VERSION "FL_EP_CANFD"

NS_ :

BS_:

BU_: BMS CDU DCB EAC EVCC FLZCU LBMS RXCU

BO_ 1170 TMS_TDU_3: 64 FLZCU
 SG_ HVHRu : 23|8@0+ (5,0) [0|1270] "V" RXCU
 SG_ HVHRi : 31|8@0+ (0.25,0) [0|63.5] "A" RXCU
 SG_ HVHR_Sts : 34|3@0+ (1,0) [0|7] "" RXCU

BO_ 1172 TMS_1: 8 FLZCU
 SG_ ExternalTemperature_C : 39|8@0+ (0.5,-40) [-40|85] "°C" RXCU
 SG_ CirculationModeDisplaySts : 45|1@0+ (1,0) [0|1] "" RXCU

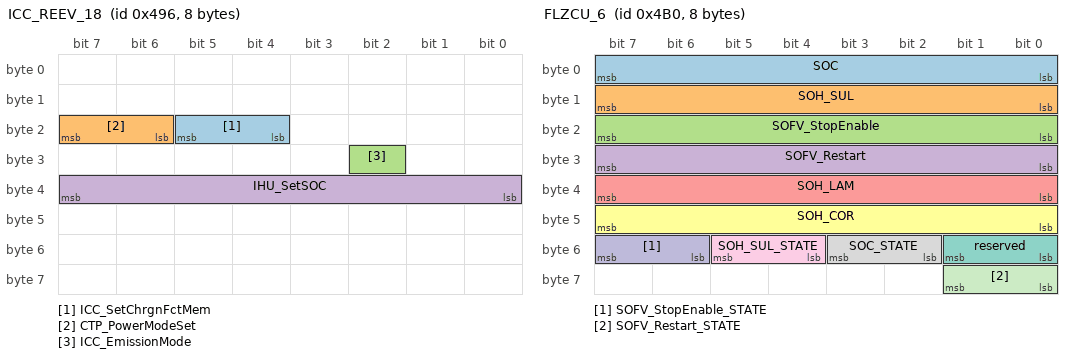
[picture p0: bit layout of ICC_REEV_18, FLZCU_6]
BO_ 1174 ICC_REEV_18: 8 FLZCU
 SG_ ICC_SetChrgnFctMem : 21|2@0+ (1,0) [0|3] "" RXCU
 SG_ CTP_PowerModeSet : 23|2@0+ (1,0) [0|3] "" RXCU
 SG_ ICC_EmissionMode : 26|1@0+ (1,0) [0|1] "" RXCU
 SG_ IHU_SetSOC : 39|8@0+ (1,0) [0|100] "%" RXCU

BO_ 1181 FLZCU_9: 8 FLZCU
 SG_ FLZCU_AlcoholLockInputSts : 47|1@0+ (1,0) [0|1] "" RXCU

BO_ 1182 CDU_OBC_3: 48 CDU
 SG_ CDU_OBC_3_CRC1 : 7|8@0+ (1,0) [0|255] "" RXCU
 SG_ CDU_OBC_3_RollgCntr1 : 11|4@0+ (1,0) [0|14] "" RXCU
 SG_ CDU_OBC_3_Resd1 : 15|4@0+ (1,0) [0|15] "" RXCU
 SG_ OBC_ChgCurr : 23|16@0+ (0.05,0) [0|400] "A" RXCU
 SG_ OBC_ChgVolt : 39|16@0+ (0.05,0) [0|1000] "V" RXCU
 SG_ OBC_MaxOutputPower : 55|8@0+ (0.1,0) [0|25.5] "kW" RXCU
 SG_ OBC_FaultCode : 63|8@0+ (1,0) [0|255] "" RXCU
 SG_ CDU_OBC_3_CRC2 : 71|8@0+ (1,0) [0|255] "" RXCU
 SG_ CDU_OBC_3_RollgCntr2 : 75|4@0+ (1,0) [0|14] "" RXCU
 SG_ CDU_OBC_3_Resd2 : 79|4@0+ (1,0) [0|15] "" RXCU
 SG_ OBC_MaxDisOutPower : 111|8@0+ (0.1,0) [0|25.5] "kW" RXCU
 SG_ OBC_CPMaxVolt : 119|8@0+ (0.1,0) [0|20] "V" RXCU
 SG_ CDU_OBC_3_CRC3 : 135|8@0+ (1,0) [0|255] "" RXCU
 SG_ CDU_OBC_3_RollgCntr3 : 139|4@0+ (1,0) [0|14] "" RXCU
 SG_ CDU_OBC_3_Resd3 : 143|4@0+ (1,0) [0|15] "" RXCU
 SG_ OBC_ChrgrInputCurr1 : 151|10@0+ (0.1,0) [0|100] "A" RXCU
 SG_ OBC_ChrgrInputCurr2 : 157|10@0+ (0.1,0) [0|100] "A" RXCU
 SG_ OBC_ChrgrInputCurr3 : 163|10@0+ (0.1,0) [0|100] "A" RXCU
 SG_ OBC_S2Swtsts : 169|2@0+ (1,0) [0|3] "" RXCU
 SG_ OBC_ChrgrInputVolt1 : 183|13@0+ (0.1,0) [0|800] "V" RXCU
 SG_ CDU_OBC_3_CRC4 : 199|8@0+ (1,0) [0|255] "" RXCU
 SG_ CDU_OBC_3_RollgCntr4 : 203|4@0+ (1,0) [0|14] "" RXCU
 SG_ CDU_OBC_3_Resd4 : 207|4@0+ (1,0) [0|15] "" RXCU
 SG_ OBC_ChrgrInputVolt2 : 215|13@0+ (0.1,0) [0|800] "V" RXCU
 SG_ OBC_ChrgrInputVolt3 : 231|13@0+ (0.1,0) [0|800] "V" RXCU
 SG_ OBC_FaultLevelSts : 234|3@0+ (1,0) [0|7] "" RXCU
 SG_ OBC_ElectronicLockSts : 242|3@0+ (1,0) [0|7] "" RXCU
 SG_ OBC_WorkingMode : 251|4@0+ (1,0) [0|15] "" RXCU
 SG_ OBC_Worksts : 253|2@0+ (1,0) [0|3] "" RXCU
 SG_ OBC_CPLineSts : 255|2@0+ (1,0) [0|3] "" RXCU
 SG_ CDU_OBC_3_CRC5 : 263|8@0+ (1,0) [0|255] "" RXCU
 SG_ CDU_OBC_3_RollgCntr5 : 267|4@0+ (1,0) [0|14] "" RXCU
 SG_ CDU_OBC_3_Resd5 : 271|4@0+ (1,0) [0|15] "" RXCU
 SG_ OBC_CCResisdent : 279|13@0+ (1,0) [0|3400] "R" RXCU
 SG_ OBC_HV_OutputUnderVolt : 280|1@0+ (1,0) [0|1] "" RXCU
 SG_ OBC_HV_OutputOverVolt : 288|1@0+ (1,0) [0|1] "" RXCU
 SG_ OBC_HV_OutputShortCircuit : 289|1@0+ (1,0) [0|1] "" RXCU
 SG_ OBC_InputUnderVolt : 290|1@0+ (1,0) [0|1] "" RXCU
 SG_ OBC_InputOverVolt : 291|1@0+ (1,0) [0|1] "" RXCU
 SG_ OBC_HighCurrOutputFault : 292|1@0+ (1,0) [0|1] "" RXCU
 SG_ OBC_CAN_Fault : 293|1@0+ (1,0) [0|1] "" RXCU
 SG_ OBC_KL30_UnderVolt : 302|1@0+ (1,0) [0|1] "" RXCU
 SG_ OBC_MaxInnerAc220VOutPower : 311|8@0+ (0.1,0) [0|25.4] "kW" RXCU
 SG_ OBC_ActInnerAc220VOutPower : 319|8@0+ (0.1,0) [0|25.4] "kW" RXCU
 SG_ CDU_OBC_3_CRC6 : 327|8@0+ (1,0) [0|255] "" RXCU
 SG_ CDU_OBC_3_RollgCntr6 : 331|4@0+ (1,0) [0|14] "" RXCU
 SG_ CDU_OBC_3_Resd6 : 335|4@0+ (1,0) [0|15] "" RXCU
 SG_ OBC_InnerDischgCurr : 343|10@0+ (0.1,0) [0|100] "A" RXCU
 SG_ OBC_InnerDischgVolt : 348|13@0+ (0.1,0) [0|800] "V" RXCU
 SG_ OBC_OutDischgCurr : 367|10@0+ (0.1,0) [0|100] "A" RXCU
 SG_ OBC_OutDischgVolt : 372|13@0+ (0.1,0) [0|800] "V" RXCU

BO_ 1184 TMS_TDU_1: 64 FLZCU
 SG_ TDU_1_EAC_Sts : 244|3@0+ (1,0) [0|7] "" RXCU
 SG_ EAC_u : 295|8@0+ (5,0) [0|1270] "V" RXCU
 SG_ EAC_i : 303|8@0+ (0.5,0) [0|127] "A" RXCU
 SG_ HVHu : 319|8@0+ (5,0) [0|1270] "V" RXCU
 SG_ HVHi : 343|8@0+ (0.25,0) [0|63.5] "A" RXCU
 SG_ HVH_Sts : 346|3@0+ (1,0) [0|7] "" RXCU

BO_ 1195 BNCM_8: 8 FLZCU
 SG_ BNCM_8_HV_Req : 35|2@0+ (1,0) [0|3] "" RXCU

BO_ 1199 TCM_1: 8 FLZCU
 SG_ TCM_1_TrailerSts : 16|1@0+ (1,0) [0|1] "" RXCU

BO_ 1200 FLZCU_6: 8 FLZCU
 SG_ SOC : 7|8@0+ (1,0) [0|100] "%" RXCU
 SG_ SOH_SUL : 15|8@0+ (1,0) [0|100] "%" RXCU
 SG_ SOFV_StopEnable : 23|8@0+ (0.0625,0) [0|15.875] "V" RXCU
 SG_ SOFV_Restart : 31|8@0+ (0.0625,0) [0|15.875] "V" RXCU
 SG_ SOH_LAM : 39|8@0+ (0.5,0) [0|127] "Ah" RXCU
 SG_ SOH_COR : 47|8@0+ (0.0625,0) [0|15.875] "V" RXCU
 SG_ reserved : 49|2@0+ (1,0) [0|3] "" RXCU
 SG_ SOC_STATE : 51|2@0+ (1,0) [0|3] "" RXCU
 SG_ SOH_SUL_STATE : 53|2@0+ (1,0) [0|3] "" RXCU
 SG_ SOFV_StopEnable_STATE : 55|2@0+ (1,0) [0|3] "" RXCU
 SG_ SOFV_Restart_STATE : 57|2@0+ (1,0) [0|3] "" RXCU

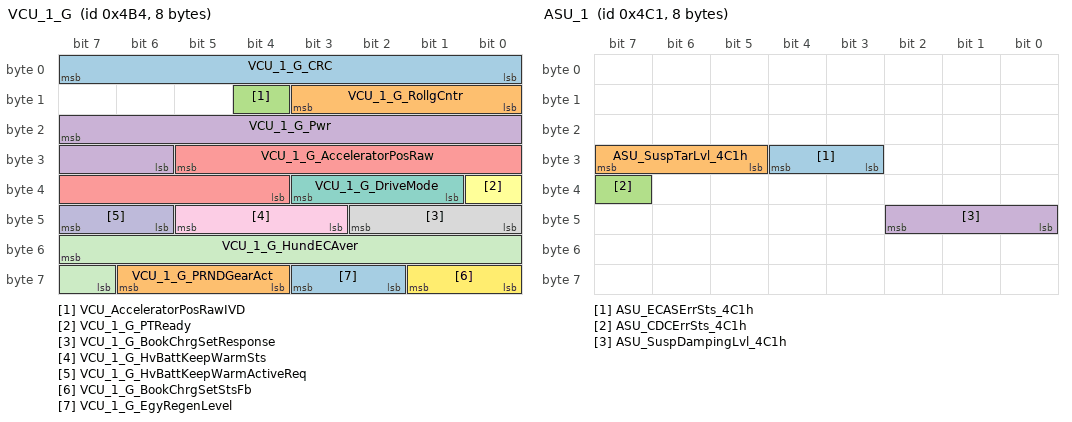
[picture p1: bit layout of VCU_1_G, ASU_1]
BO_ 1204 VCU_1_G: 8 RXCU
 SG_ VCU_1_G_CRC : 7|8@0+ (1,0) [0|255] "" FLZCU
 SG_ VCU_1_G_RollgCntr : 11|4@0+ (1,0) [0|14] "" FLZCU
 SG_ VCU_AcceleratorPosRawIVD : 12|1@0+ (1,0) [0|1] "" FLZCU
 SG_ VCU_1_G_Pwr : 23|10@0+ (1,-500) [-500|500] "" FLZCU
 SG_ VCU_1_G_AcceleratorPosRaw : 29|10@0+ (0.1,0) [0|100] "%" FLZCU
 SG_ VCU_1_G_PTReady : 32|1@0+ (1,0) [0|1] "" FLZCU
 SG_ VCU_1_G_DriveMode : 35|3@0+ (1,0) [0|7] "" FLZCU
 SG_ VCU_1_G_BookChrgSetResponse : 42|3@0+ (1,0) [0|7] "" BMS,CDU,FLZCU
 SG_ VCU_1_G_HvBattKeepWarmSts : 45|3@0+ (1,0) [0|7] "" FLZCU
 SG_ VCU_1_G_HvBattKeepWarmActiveReq : 47|2@0+ (1,0) [0|3] "" BMS,CDU,FLZCU
 SG_ VCU_1_G_HundECAver : 55|9@0+ (0.1,0) [0|51] "kwh" FLZCU
 SG_ VCU_1_G_BookChrgSetStsFb : 57|2@0+ (1,0) [0|3] "" FLZCU
 SG_ VCU_1_G_EgyRegenLevel : 59|2@0+ (1,0) [0|3] "" FLZCU
 SG_ VCU_1_G_PRNDGearAct : 62|3@0+ (1,0) [0|7] "" BMS,CDU,DCB,EVCC,FLZCU

BO_ 1207 TMS_TDU_2: 64 FLZCU
 SG_ EAC_i_400V : 279|9@0+ (0.1,0) [0|50] "A" RXCU
 SG_ HVH_Sts_400V : 282|3@0+ (1,0) [0|7] "" RXCU
 SG_ HVH_U_400V : 295|8@0+ (2,0) [0|508] "V" RXCU
 SG_ Flag_400V_800V : 299|2@0+ (1,0) [0|3] "" RXCU

BO_ 1209 VCU_2_G: 8 RXCU
 SG_ VCU_2_G_CRC : 7|8@0+ (1,0) [0|255] "" FLZCU
 SG_ VCU_2_G_RollgCntr : 11|4@0+ (1,0) [0|14] "" FLZCU
 SG_ VCU_2_G_Resd : 15|4@0+ (1,0) [0|15] "" FLZCU
 SG_ VCU_2_G_GasPedalPosInvalidData : 24|1@0+ (1,0) [0|1] "" FLZCU
 SG_ VCU_2_G_PowerLimit : 25|1@0+ (1,0) [0|1] "" FLZCU
 SG_ VCU_2_G_BrakeLightReq : 26|1@0+ (1,0) [0|1] "" FLZCU
 SG_ VCU_2_G_VehicleSystemFailure : 27|1@0+ (1,0) [0|1] "" FLZCU
 SG_ OnekeyHVOffSuccess_4B9h : 28|1@0+ (1,0) [0|1] "" FLZCU
 SG_ VCU_2_G_BootloadSts : 29|1@0+ (1,0) [0|1] "" FLZCU
 SG_ VCU_2_G_DischgSts : 30|1@0+ (1,0) [0|1] "" FLZCU
 SG_ VCU_2_G_BrakePedalStsValidData : 31|1@0+ (1,0) [0|1] "" FLZCU
 SG_ VCU_2_G_ExhibitionMod : 32|1@0+ (1,0) [0|1] "" FLZCU
 SG_ VCU_2_G_BrakePedalSts : 36|1@0+ (1,0) [0|1] "" FLZCU
 SG_ VCU_2_G_DCDCEnable : 37|1@0+ (1,0) [0|1] "" FLZCU
 SG_ VCU_2_G_HVReady : 38|1@0+ (1,0) [0|1] "" CDU,FLZCU,LBMS
 SG_ Res_VCU_2_G_Brake_state : 39|1@0+ (1,0) [0|1] "" FLZCU
 SG_ VCU_2_G_VCUEnergyflow : 43|4@0+ (1,0) [0|15] "" FLZCU
 SG_ VCU_2_G_GasPedalPosition : 49|10@0+ (0.1,0) [0|100] "%" FLZCU
 SG_ VCU_2_G_DrvGearShiftFailureIndcn : 53|4@0+ (1,0) [0|15] "" FLZCU
 SG_ VCU_2_G_OnekeyHVoffStyle : 55|2@0+ (1,0) [0|3] "" FLZCU

BO_ 1217 ASU_1: 8 FLZCU
 SG_ ASU_ECASErrSts_4C1h : 28|2@0+ (1,0) [0|3] "" RXCU
 SG_ ASU_SuspTarLvl_4C1h : 31|3@0+ (1,0) [0|7] "" RXCU
 SG_ ASU_CDCErrSts_4C1h : 39|1@0+ (1,0) [0|1] "" RXCU
 SG_ ASU_SuspDampingLvl_4C1h : 42|3@0+ (1,0) [0|7] "" RXCU

BO_ 1219 VCU_TMS_9: 16 RXCU
 SG_ VCU_CLMSystemPowerLimit : 23|10@0+ (0.04,0) [0|40] "KW" FLZCU
 SG_ HCU_HVHRAllow : 33|2@0+ (1,0) [0|3] "" FLZCU
 SG_ VCU_CLMEACAllow : 34|1@0+ (1,0) [0|1] "" FLZCU
 SG_ VCU_CLMHVHAllow : 35|1@0+ (1,0) [0|1] "" FLZCU
 SG_ VCU_CLMHVReady : 36|1@0+ (1,0) [0|1] "" FLZCU
 SG_ VCU_PwtCoolingLvl : 39|3@0+ (1,0) [0|7] "" FLZCU

BO_ 1224 BMS_12: 16 BMS
 SG_ BMS_Chg_Sts : 87|4@0+ (1,0) [0|15] "" RXCU

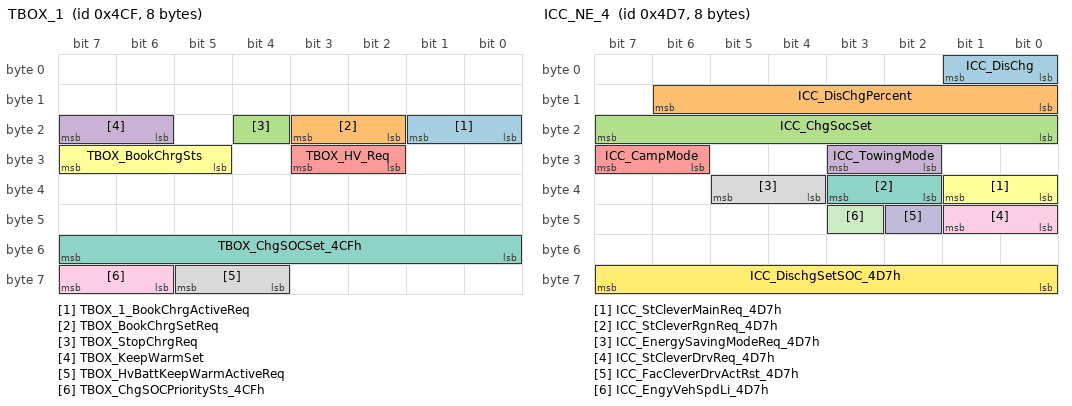
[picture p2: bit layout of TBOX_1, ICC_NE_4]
BO_ 1231 TBOX_1: 8 FLZCU
 SG_ TBOX_1_BookChrgActiveReq : 17|2@0+ (1,0) [0|3] "" RXCU
 SG_ TBOX_BookChrgSetReq : 19|2@0+ (1,0) [0|3] "" RXCU
 SG_ TBOX_StopChrgReq : 20|1@0+ (1,0) [0|1] "" RXCU
 SG_ TBOX_KeepWarmSet : 23|2@0+ (1,0) [0|3] "" RXCU
 SG_ TBOX_HV_Req : 27|2@0+ (1,0) [0|3] "" RXCU
 SG_ TBOX_BookChrgSts : 31|3@0+ (1,0) [0|7] "" RXCU
 SG_ TBOX_ChgSOCSet_4CFh : 55|8@0+ (1,0) [1|100] "%" RXCU
 SG_ TBOX_HvBattKeepWarmActiveReq : 61|2@0+ (1,0) [0|3] "" RXCU
 SG_ TBOX_ChgSOCPrioritySts_4CFh : 63|2@0+ (1,0) [0|3] "" RXCU

BO_ 1239 ICC_NE_4: 8 FLZCU
 SG_ ICC_DisChg : 1|2@0+ (1,0) [0|3] "" RXCU
 SG_ ICC_DisChgPercent : 14|7@0+ (1,0) [1|100] "%" RXCU
 SG_ ICC_ChgSocSet : 23|8@0+ (1,0) [1|100] "%" RXCU
 SG_ ICC_TowingMode : 27|2@0+ (1,0) [0|3] "" RXCU
 SG_ ICC_CampMode : 31|2@0+ (1,0) [0|3] "" RXCU
 SG_ ICC_StCleverMainReq_4D7h : 33|2@0+ (1,0) [0|3] "" RXCU
 SG_ ICC_StCleverRgnReq_4D7h : 35|2@0+ (1,0) [0|3] "" RXCU
 SG_ ICC_EnergySavingModeReq_4D7h : 37|2@0+ (1,0) [0|3] "" RXCU
 SG_ ICC_StCleverDrvReq_4D7h : 41|2@0+ (1,0) [0|3] "" RXCU
 SG_ ICC_FacCleverDrvActRst_4D7h : 42|1@0+ (1,0) [0|1] "" RXCU
 SG_ ICC_EngyVehSpdLi_4D7h : 43|1@0+ (1,0) [0|1] "" RXCU
 SG_ ICC_DischgSetSOC_4D7h : 63|8@0+ (1,0) [0|100] "" RXCU

BO_ 1246 ICC_TMS_5: 32 FLZCU
 SG_ ICC_KeepWarm : 35|2@0+ (1,0) [0|3] "" RXCU

BO_ 1248 FRZCU_TO_FLZCU: 48 FLZCU
 SG_ FRZCU_RKEButtAct : 239|3@0+ (1,0) [0|7] "" RXCU

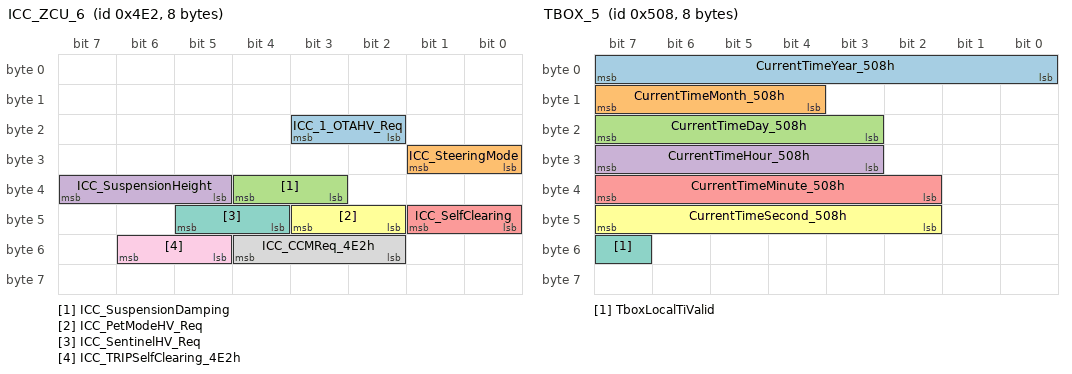
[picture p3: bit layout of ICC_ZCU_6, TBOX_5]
BO_ 1250 ICC_ZCU_6: 8 FLZCU
 SG_ ICC_1_OTAHV_Req : 19|2@0+ (1,0) [0|3] "" RXCU
 SG_ ICC_SteeringMode : 25|2@0+ (1,0) [0|3] "" RXCU
 SG_ ICC_SuspensionDamping : 36|2@0+ (1,0) [0|3] "" RXCU
 SG_ ICC_SuspensionHeight : 39|3@0+ (1,0) [0|7] "" RXCU
 SG_ ICC_SelfClearing : 41|2@0+ (1,0) [0|3] "" RXCU
 SG_ ICC_PetModeHV_Req : 43|2@0+ (1,0) [0|3] "" RXCU
 SG_ ICC_SentinelHV_Req : 45|2@0+ (1,0) [0|3] "" RXCU
 SG_ ICC_CCMReq_4E2h : 52|3@0+ (1,0) [0|7] "" RXCU
 SG_ ICC_TRIPSelfClearing_4E2h : 54|2@0+ (1,0) [0|3] "" RXCU

BO_ 1252 ICC_COM_1: 8 FLZCU
 SG_ TotalOdometer_km_OBD : 23|24@0+ (0.1,0) [0|999999.9] "km" RXCU
 SG_ TotalOdometer_km_OBDValidData : 60|1@0+ (1,0) [0|1] "" RXCU

BO_ 1265 ICC_ZCU_25: 24 FLZCU
 SG_ ICC_CinemaStatus : 185|2@0+ (1,0) [0|3] "" RXCU

BO_ 1268 BMS_4F4h: 64 BMS
 SG_ CRC1_4F4h : 7|8@0+ (1,0) [0|255] "" RXCU
 SG_ RollgCntr1_4F4h : 11|4@0+ (1,0) [0|14] "" RXCU
 SG_ Resd1_4F4h : 15|4@0+ (1,0) [0|15] "" RXCU
 SG_ SOCE_4F4h : 23|10@0+ (0.1,0) [0|100] "%" RXCU
 SG_ CRC2_4F4h : 71|8@0+ (1,0) [0|255] "" RXCU
 SG_ RollgCntr2_4F4h : 75|4@0+ (1,0) [0|14] "" RXCU
 SG_ Resd2_4F4h : 79|4@0+ (1,0) [0|15] "" RXCU
 SG_ HvBattEgyTotal_4F4h : 87|20@0+ (1,0) [0|1000000] "kWh" RXCU
 SG_ HvBattV2XTotal_4F4h : 99|20@0+ (1,0) [0|1000000] "kWh" RXCU
 SG_ CRC3_4F4h : 135|8@0+ (1,0) [0|255] "" RXCU
 SG_ RollgCntr3_4F4h : 139|4@0+ (1,0) [0|14] "" RXCU
 SG_ Resd3_4F4h : 143|4@0+ (1,0) [0|15] "" RXCU
 SG_ HvBattNoDrivEgyTotal_4F4h : 151|20@0+ (1,0) [0|1000000] "kWh" RXCU

BO_ 1288 TBOX_5: 8 FLZCU
 SG_ CurrentTimeYear_508h : 7|8@0+ (1,2000) [2000|2255] "" RXCU
 SG_ CurrentTimeMonth_508h : 15|4@0+ (1,0) [1|12] "" RXCU
 SG_ CurrentTimeDay_508h : 23|5@0+ (1,0) [1|31] "" RXCU
 SG_ CurrentTimeHour_508h : 31|5@0+ (1,0) [0|23] "" RXCU
 SG_ CurrentTimeMinute_508h : 39|6@0+ (1,0) [0|59] "" RXCU
 SG_ CurrentTimeSecond_508h : 47|6@0+ (1,0) [0|59] "" RXCU
 SG_ TboxLocalTiValid : 55|1@0+ (1,0) [0|1] "" RXCU

BO_ 1290 BMS_8: 8 BMS
 SG_ BMS_HvBattCellUnderU : 21|3@0+ (1,0) [0|7] "" RXCU
 SG_ BMS_HvBattUnderU : 23|2@0+ (1,0) [0|3] "" RXCU

BO_ 1291 BMS_2_G: 8 BMS
 SG_ BMS_SOCLight : 62|7@0+ (1,0) [0|100] "%" RXCU

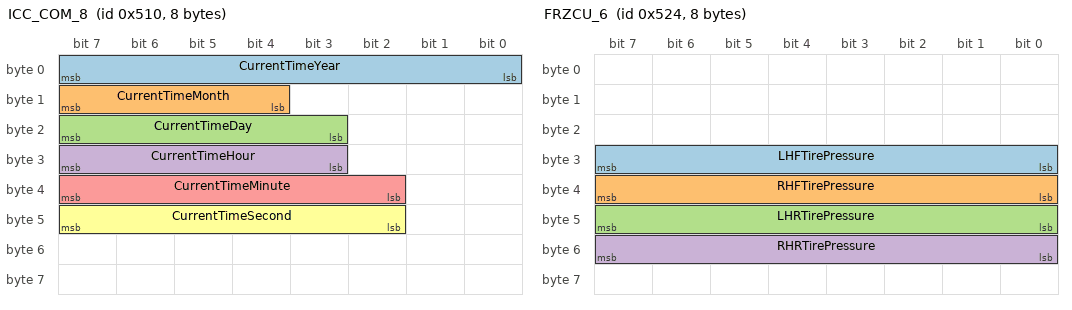
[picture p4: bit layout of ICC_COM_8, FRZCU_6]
BO_ 1296 ICC_COM_8: 8 FLZCU
 SG_ CurrentTimeYear : 7|8@0+ (1,2000) [2000|2255] "" RXCU
 SG_ CurrentTimeMonth : 15|4@0+ (1,0) [1|12] "" RXCU
 SG_ CurrentTimeDay : 23|5@0+ (1,0) [1|31] "" RXCU
 SG_ CurrentTimeHour : 31|5@0+ (1,0) [0|23] "" RXCU
 SG_ CurrentTimeMinute : 39|6@0+ (1,0) [0|59] "" RXCU
 SG_ CurrentTimeSecond : 47|6@0+ (1,0) [0|59] "" RXCU

BO_ 1298 APTC_2: 8 FLZCU
 SG_ APTC_ErrorLevel : 21|3@0+ (1,0) [0|7] "" RXCU
 SG_ APTC_ErrorCode2 : 31|8@0+ (1,0) [0|255] "" RXCU

BO_ 1314 HCU_25: 64 RXCU
 SG_ HCU_CRC1_522h : 7|8@0+ (1,0) [0|255] "" FLZCU
 SG_ HCU_RollgCntr1_522h : 11|4@0+ (1,0) [0|14] "" FLZCU
 SG_ HCU_Resd1_522h : 15|4@0+ (1,0) [0|15] "" FLZCU
 SG_ HCU_V2lDisChgBck : 17|2@0+ (1,0) [0|3] "" FLZCU
 SG_ HCU_DisChgMemFed : 19|2@0+ (1,0) [0|3] "" FLZCU
 SG_ HCU_V2VDisChgBck : 21|2@0+ (1,0) [0|3] "" CDU,FLZCU
 SG_ HCU_V2l_IntlDisChgBck : 23|2@0+ (1,0) [0|3] "" FLZCU
 SG_ HCU_FuelDetnOpDefeated : 25|2@0+ (1,0) [0|3] "" FLZCU
 SG_ HCU_FuelDetnModSwtFed : 27|2@0+ (1,0) [0|3] "" FLZCU
 SG_ HCU_FuelDetnStateFed : 29|2@0+ (1,0) [0|3] "" FLZCU
 SG_ HCU_HVDownRepairModeFed : 31|2@0+ (1,0) [0|3] "" FLZCU
 SG_ HCU_SumFuCns : 37|9@0+ (0.1,0) [0|50] "L/km" FLZCU
 SG_ HCU_TrailerMode : 39|2@0+ (1,0) [0|3] "" FLZCU
 SG_ HCU_TABSwtFed_522h : 40|2@0+ (1,0) [0|3] "" FLZCU
 SG_ HCU_MotSelfHeatLvlReq : 43|3@0+ (1,0) [0|7] "" FLZCU
 SG_ HCU_MotSelfHeatEnReq : 44|1@0+ (1,0) [0|1] "" FLZCU
 SG_ HCU_KeyDriveModememory : 49|2@0+ (1,0) [0|3] "" FLZCU
 SG_ HCU_DrivePowerDispSetFed : 51|2@0+ (1,0) [0|3] "" FLZCU
 SG_ HCU_TCMStsReq_522h : 54|1@0+ (1,0) [0|1] "" FLZCU
 SG_ HCU_EXPERTNormFed : 57|2@0+ (1,0) [0|3] "" FLZCU
 SG_ HCU_4LModeFed : 58|1@0+ (1,0) [0|1] "" FLZCU
 SG_ HCU_EXPERTEcoFed : 60|2@0+ (1,0) [0|3] "" FLZCU
 SG_ HCU_SingleRegnRmn : 61|1@0+ (1,0) [0|1] "" FLZCU
 SG_ HCU_DRIFTModeSts : 63|2@0+ (1,0) [0|3] "" FLZCU
 SG_ HCU_CRC2_522h : 71|8@0+ (1,0) [0|255] "" FLZCU
 SG_ HCU_RollgCntr2_522h : 75|4@0+ (1,0) [0|14] "" FLZCU
 SG_ HCU_Resd2_522h : 79|4@0+ (1,0) [0|15] "" FLZCU
 SG_ HCU_EXPERTAWDFed : 81|2@0+ (1,0) [0|3] "" FLZCU
 SG_ HCU_EXPERTRWDFed : 83|2@0+ (1,0) [0|3] "" FLZCU
 SG_ HCU_CrossaxisFed : 85|2@0+ (1,0) [0|3] "" FLZCU
 SG_ HCU_EXPERTSportFed : 87|2@0+ (1,0) [0|3] "" FLZCU
 SG_ HCU_StopChrgnModeFed : 89|2@0+ (1,0) [0|3] "" FLZCU
 SG_ HCU_StopChrgnFed : 91|2@0+ (1,0) [0|3] "" FLZCU
 SG_ HCU_CLIMBFed : 93|2@0+ (1,0) [0|3] "" FLZCU
 SG_ HCU_EXPERTAutoFed : 95|2@0+ (1,0) [0|3] "" FLZCU
 SG_ HCU_HEV_FunctionLimit : 96|1@0+ (1,0) [0|1] "" FLZCU
 SG_ HCU_ParkingChargeReminder : 97|1@0+ (1,0) [0|1] "" FLZCU
 SG_ HCU_PowerCut : 98|1@0+ (1,0) [0|1] "" FLZCU
 SG_ HCU_IMMOReleaseSignal : 99|1@0+ (1,0) [0|1] "" FLZCU
 SG_ HCU_LVPowSupSYSAbn_lit : 100|1@0+ (1,0) [0|1] "" FLZCU
 SG_ HCU_ChrgnFctMemSt : 102|2@0+ (1,0) [0|3] "" FLZCU
 SG_ HCU_PowerModeChangeInhibit : 104|1@0+ (1,0) [0|1] "" FLZCU
 SG_ HCU_DisconnectChagWarn : 105|1@0+ (1,0) [0|1] "" FLZCU
 SG_ HCU_EngineRunClmReq : 106|1@0+ (1,0) [0|1] "" FLZCU
 SG_ HCU_VehicleSpeedMax_Limit : 107|1@0+ (1,0) [0|1] "" FLZCU
 SG_ HCU_AccleAbility_Limit : 108|1@0+ (1,0) [0|1] "" FLZCU
 SG_ HCU_DriveInhibit_GearP : 109|1@0+ (1,0) [0|1] "" FLZCU
 SG_ HCU_SetModeNotChange : 110|1@0+ (1,0) [0|1] "" FLZCU
 SG_ HCU_UTURNSnowFed : 111|1@0+ (1,0) [0|1] "" FLZCU
 SG_ HCU_PowerLevel : 114|3@0+ (1,0) [0|7] "" FLZCU
 SG_ HCU_TowingModeEna : 115|1@0+ (1,0) [0|1] "" FLZCU
 SG_ HCU_LeaveVehicleWarning : 116|1@0+ (1,0) [0|1] "" FLZCU
 SG_ HCU_DedicatedModeInhibit : 117|1@0+ (1,0) [0|1] "" FLZCU
 SG_ HCU_DisChargeStopFault : 119|2@0+ (1,0) [0|3] "" FLZCU
 SG_ HCU_RearEDLSts : 123|4@0+ (1,0) [0|15] "" FLZCU
 SG_ HCU_FrntEDLSts : 127|4@0+ (1,0) [0|15] "" FLZCU
 SG_ HCU_CRC3_522h : 135|8@0+ (1,0) [0|255] "" FLZCU
 SG_ HCU_RollgCntr3_522h : 139|4@0+ (1,0) [0|14] "" FLZCU
 SG_ HCU_Resd3_522h : 143|4@0+ (1,0) [0|15] "" FLZCU
 SG_ HCU_CruiseLimitSpeedValue : 146|13@0+ (0.0625,0) [0|511.875] "km/h" FLZCU
 SG_ HCU_DriveMode_JT : 151|5@0+ (1,0) [0|31] "" BMS,FLZCU
 SG_ HCU_SocManageFed : 162|3@0+ (1,0) [0|7] "" FLZCU
 SG_ HCU_SinglePedalMemFed : 163|1@0+ (1,0) [0|1] "" FLZCU
 SG_ HCU_CCOSwtFed : 165|2@0+ (1,0) [0|3] "" FLZCU
 SG_ HCU_Pwr : 175|12@0+ (1,-2000) [-2000|2000] "KW" FLZCU
 SG_ HCU_DrvGearShiftFailureIndcn : 179|4@0+ (1,0) [0|15] "" FLZCU
 SG_ HCU_UTURNSandFed : 184|1@0+ (1,0) [0|1] "" FLZCU
 SG_ HCU_CruiseControlStatus : 186|2@0+ (1,0) [0|3] "" FLZCU
 SG_ HCU_EXPERTEESPSet : 188|2@0+ (1,0) [0|3] "" FLZCU
 SG_ HCU_EgyRegenLevel : 191|3@0+ (1,0) [0|7] "" FLZCU
 SG_ HCU_CRC4_522h : 199|8@0+ (1,0) [0|255] "" FLZCU
 SG_ HCU_RollgCntr4_522h : 203|4@0+ (1,0) [0|14] "" FLZCU
 SG_ HCU_Resd4_522h : 207|4@0+ (1,0) [0|15] "" FLZCU
 SG_ HCU_EngyFlowToDisp : 211|5@0+ (1,0) [0|31] "" FLZCU
 SG_ HCU_UTURNGrassFed : 212|1@0+ (1,0) [0|1] "" FLZCU
 SG_ HCU_UTURNMudFed : 213|1@0+ (1,0) [0|1] "" FLZCU
 SG_ HCU_LTCDispFed : 215|2@0+ (1,0) [0|3] "" FLZCU
 SG_ HCU_iTAS_Warn : 217|3@0+ (1,0) [0|7] "" FLZCU
 SG_ HCU_iCCO_Warn : 221|4@0+ (1,0) [0|15] "" FLZCU
 SG_ HCU_DriveModeChangeFail : 222|1@0+ (1,0) [0|1] "" FLZCU
 SG_ HCU_25_Crossaxis_Warn : 225|3@0+ (1,0) [0|7] "" FLZCU
 SG_ HCU_25_EDLFed : 227|2@0+ (1,0) [0|3] "" FLZCU
 SG_ HCU_DraggingModeRemind : 230|3@0+ (1,0) [0|7] "" FLZCU
 SG_ HCU_iTASSceneReq : 232|3@0+ (1,0) [0|7] "" FLZCU
 SG_ HCU_25_iTAS_SlopWarn : 234|2@0+ (1,0) [0|3] "" FLZCU
 SG_ HCU_ExterTempLowHint : 236|2@0+ (1,0) [0|3] "" FLZCU
 SG_ HCU_iTAS_Active : 238|2@0+ (1,0) [0|3] "" FLZCU
 SG_ HCU_25_VehSpdOffroadRmn : 240|1@0+ (1,0) [0|1] "" FLZCU
 SG_ HCU_DrivingModReq : 245|5@0+ (1,0) [0|31] "" FLZCU
 SG_ HCU_25_ADS_FctSts : 248|1@0+ (1,0) [0|1] "" FLZCU
 SG_ HCU_25_DRIFTModeSetReq : 251|3@0+ (1,0) [0|7] "" FLZCU
 SG_ HCU_25_CrossaxisReq : 253|2@0+ (1,0) [0|3] "" FLZCU
 SG_ HCU_25_CCOSwtReq : 255|2@0+ (1,0) [0|3] "" FLZCU
 SG_ HCU_CRC5_522h : 263|8@0+ (1,0) [0|255] "" FLZCU
 SG_ HCU_RollgCntr5_522h : 267|4@0+ (1,0) [0|14] "" FLZCU
 SG_ HCU_Resd5_522h : 271|4@0+ (1,0) [0|15] "" FLZCU
 SG_ HCU_25_ErrorCode : 279|16@0+ (1,0) [0|65535] "" FLZCU
 SG_ HCU_25_ErrorCount : 295|8@0+ (1,0) [0|255] "" FLZCU
 SG_ HCU_25_iDRIFT_Warn : 298|3@0+ (1,0) [0|7] "" FLZCU
 SG_ HCU_25_SetVehSpdOffroad : 300|2@0+ (1,0) [0|3] "" FLZCU
 SG_ HCU_25_LaunchMod_Warn : 303|3@0+ (1,0) [0|7] "" FLZCU
 SG_ HCU_25_TAB_Warn : 307|3@0+ (1,0) [0|7] "" FLZCU
 SG_ HCU_25_CCO_TextDisp : 311|4@0+ (1,0) [0|15] "" FLZCU
 SG_ HCU_25_DCM_Warn : 315|4@0+ (1,0) [0|15] "" FLZCU
 SG_ HCU_25_CCMFed : 317|2@0+ (1,0) [0|3] "" FLZCU
 SG_ HCU_25_TABReq : 319|2@0+ (1,0) [0|3] "" FLZCU
 SG_ HCU_SumElecCns : 339|12@0+ (0.1,-100) [-100|100] "kwh/100km" FLZCU
 SG_ HCU_CrossBorderSts : 341|2@0+ (1,0) [0|3] "" FLZCU
 SG_ HCU_DischgSetSOCFed : 367|8@0+ (1,0) [0|100] "%" FLZCU
 SG_ HCU_facCleverDrvAct_522h : 369|5@0+ (0.1,-1) [-1|2.1] "" FLZCU
 SG_ HCU_stCleverDrvAct_522h : 371|2@0+ (1,0) [0|3] "" FLZCU
 SG_ HCU_stCleverRgnAct_522h : 373|2@0+ (1,0) [0|3] "" FLZCU
 SG_ HCU_stCleverMainAct_522h : 375|2@0+ (1,0) [0|3] "" FLZCU
 SG_ EnergySavingModeSts_522h : 378|2@0+ (1,0) [0|3] "" FLZCU
 SG_ HCU_facCleverDrvActRstFed_522h : 380|2@0+ (1,0) [0|3] "" FLZCU
 SG_ HCU_SailramainingT_Indc_522h : 407|16@0+ (1,0) [0|65535] "s" FLZCU
 SG_ HCU_ATCM_Operation_REQ_522h : 416|3@0+ (1,0) [0|7] "" FLZCU
 SG_ HCU_ModeSwFailureIndc_522h : 419|3@0+ (1,0) [0|7] "" FLZCU
 SG_ HCU_Sailmode_522h : 423|4@0+ (1,0) [0|15] "" FLZCU
 SG_ HCU_CarSickRelfModeFb : 425|2@0+ (1,0) [0|3] "" FLZCU
 SG_ HCU_DeepSnowSts_522h : 427|2@0+ (1,0) [0|3] "" FLZCU
 SG_ DriveModeChangeFailReason_522h : 429|2@0+ (1,0) [0|3] "" FLZCU
 SG_ HCU_CLIMBDisReason_522h : 433|4@0+ (1,0) [0|15] "" FLZCU
 SG_ HCU_CarSickRelfModeDisReason : 436|3@0+ (1,0) [0|7] "" FLZCU
 SG_ HCU_DCMSwtFed : 439|3@0+ (1,0) [0|7] "" FLZCU
 SG_ HCU_LightSandSts_522h : 445|2@0+ (1,0) [0|3] "" FLZCU

BO_ 1316 FRZCU_6: 8 FLZCU
 SG_ LHFTirePressure : 31|8@0+ (2.75,0) [0|701.25] "kPa" RXCU
 SG_ RHFTirePressure : 39|8@0+ (2.75,0) [0|701.25] "kPa" RXCU
 SG_ LHRTirePressure : 47|8@0+ (2.75,0) [0|701.25] "kPa" RXCU
 SG_ RHRTirePressure : 55|8@0+ (2.75,0) [0|701.25] "kPa" RXCU

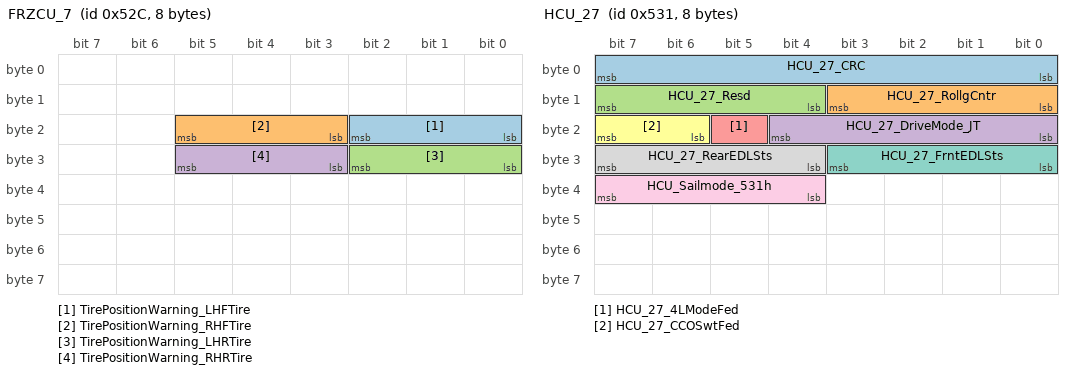
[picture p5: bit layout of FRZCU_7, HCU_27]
BO_ 1324 FRZCU_7: 8 FLZCU
 SG_ TirePositionWarning_LHFTire : 18|3@0+ (1,0) [0|7] "" RXCU
 SG_ TirePositionWarning_RHFTire : 21|3@0+ (1,0) [0|7] "" RXCU
 SG_ TirePositionWarning_LHRTire : 26|3@0+ (1,0) [0|7] "" RXCU
 SG_ TirePositionWarning_RHRTire : 29|3@0+ (1,0) [0|7] "" RXCU

BO_ 1329 HCU_27: 8 RXCU
 SG_ HCU_27_CRC : 7|8@0+ (1,0) [0|255] "" FLZCU
 SG_ HCU_27_RollgCntr : 11|4@0+ (1,0) [0|14] "" FLZCU
 SG_ HCU_27_Resd : 15|4@0+ (1,0) [0|15] "" FLZCU
 SG_ HCU_27_DriveMode_JT : 20|5@0+ (1,0) [0|31] "" FLZCU
 SG_ HCU_27_4LModeFed : 21|1@0+ (1,0) [0|1] "" FLZCU
 SG_ HCU_27_CCOSwtFed : 23|2@0+ (1,0) [0|3] "" FLZCU
 SG_ HCU_27_FrntEDLSts : 27|4@0+ (1,0) [0|15] "" FLZCU
 SG_ HCU_27_RearEDLSts : 31|4@0+ (1,0) [0|15] "" FLZCU
 SG_ HCU_Sailmode_531h : 39|4@0+ (1,0) [0|15] "" FLZCU

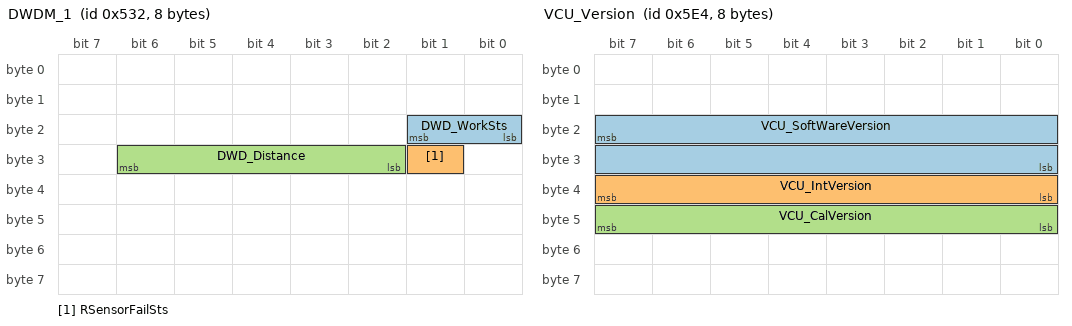
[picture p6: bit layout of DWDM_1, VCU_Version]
BO_ 1330 DWDM_1: 8 FLZCU
 SG_ DWD_WorkSts : 17|2@0+ (1,0) [0|3] "" RXCU
 SG_ RSensorFailSts : 25|1@0+ (1,0) [0|1] "" RXCU
 SG_ DWD_Distance : 30|5@0+ (1,0) [0|31] "" RXCU

BO_ 1360 ICC_LC_42: 64 FLZCU
 SG_ ICC_XDriveMode : 40|5@0+ (1,0) [0|31] "" RXCU

BO_ 1417 HCU_589h: 64 RXCU
 SG_ HCU_RangCnsDispElecThisTrip_589h : 7|11@0+ (1,0) [0|2047] "km" FLZCU
 SG_ HCU_RangCnsDispThisTrip_589h : 23|11@0+ (1,0) [0|2047] "km" FLZCU
 SG_ HCU_RealMileagThisTrip_589h : 28|11@0+ (1,0) [0|2047] "km" FLZCU
 SG_ HCU_ElecCnsAvgThisTrip_589h : 33|12@0+ (0.1,-100) [-100|100] "kwh/100km" FLZCU
 SG_ HCU_RangCnsDispHybThisTrip_589h : 53|11@0+ (1,0) [0|2047] "km" FLZCU
 SG_ HCU_RealMileagElecThisTrip_589h : 58|11@0+ (1,0) [0|2047] "km" FLZCU
 SG_ HCU_TimeHvRdyThisTrip_589h : 87|16@0+ (0.1,0) [0|6553.5] "h" FLZCU
 SG_ HCU_ACRangCnsThisTrip_589h : 103|11@0+ (1,-2047) [-2047|0] "km" FLZCU
 SG_ HCU_AuxRangCnsThisTrip_589h : 108|11@0+ (1,-2047) [-2047|0] "km" FLZCU
 SG_ HCU_RealMileagHybThisTrip_589h : 113|11@0+ (1,0) [0|2047] "km" FLZCU
 SG_ HCU_RangCnsDispElecAfRst_589h : 134|14@0+ (1,0) [0|16383] "km" FLZCU
 SG_ HCU_RgnRangBiasThisTrip_589h : 151|11@0+ (1,-1000) [-1000|1000] "km" FLZCU
 SG_ HCU_RangCnsDispAfChrg_589h : 156|11@0+ (1,0) [0|2047] "km" FLZCU
 SG_ HCU_RealMileagAfChrg_589h : 161|11@0+ (1,0) [0|2047] "km" FLZCU
 SG_ HCU_RangCnsDispElecAfChrg_589h : 182|11@0+ (1,0) [0|2047] "km" FLZCU
 SG_ HCU_RangCnsDispHybThisAfCh_589h : 187|11@0+ (1,0) [0|2047] "km" FLZCU
 SG_ HCU_FuelCnsAvgAfChrg_589h : 192|9@0+ (0.1,0) [0|50] "L/100km" FLZCU
 SG_ HCU_ElecCnsAvgAfChrg_589h : 215|12@0+ (0.1,-100) [-100|100] "kwh/100km" FLZCU
 SG_ HCU_TimeHvRdyAfChrg_589h : 219|11@0+ (0.1,0) [0|204.7] "h" FLZCU
 SG_ HCU_ACRangCnsAfChrg_589h : 235|11@0+ (1,-2047) [-2047|0] "km" FLZCU
 SG_ HCU_FuelCnsAvgThisTrip_589h : 240|9@0+ (0.1,0) [0|50] "L/100km" FLZCU
 SG_ HCU_RealMileagElecAfChrg_589h : 263|11@0+ (1,0) [0|2047] "km" FLZCU
 SG_ HCU_AuxRangCnsAfChrg_589h : 279|11@0+ (1,-2047) [-2047|0] "km" FLZCU
 SG_ HCU_RgnRangBiasAfChrg_589h : 284|11@0+ (1,-1000) [-1000|1032] "km" FLZCU
 SG_ HCU_RangCnsDispAfRst_589h : 289|11@0+ (1,0) [0|2047] "km" FLZCU
 SG_ HCU_RealMileagAfRst_589h : 310|11@0+ (1,0) [0|2047] "km" FLZCU
 SG_ HCU_RealMileagHybAfChrg_589h : 315|11@0+ (1,0) [0|2047] "km" FLZCU
 SG_ HCU_FuelCnsAvgAfRst_589h : 320|9@0+ (0.1,0) [0|50] "L/100km" FLZCU
 SG_ HCU_ElecCnsAvgAfRst_589h : 343|12@0+ (0.1,-100) [-100|100] "kwh/100km" FLZCU
 SG_ HCU_TimeHvRdyAfRst_589h : 347|16@0+ (0.1,0) [0|6553.5] "h" FLZCU
 SG_ HCU_ACRangCnsAfRst_589h : 363|11@0+ (1,-2047) [-2047|0] "km" FLZCU
 SG_ HCU_RangCnsDispHybThisAfRst_589h : 368|14@0+ (1,0) [0|16383] "km" FLZCU
 SG_ HCU_AuxRangCnsAfRst_589h : 407|11@0+ (1,-2047) [-2047|0] "km" FLZCU
 SG_ HCU_RgnRangBiasAfRst_589h : 412|11@0+ (1,-1000) [-1000|1032] "km" FLZCU
 SG_ HCU_stCleverDisReason_589h : 417|4@0+ (1,0) [0|15] "" FLZCU
 SG_ HCU_RealMileagElecAfRst_589h : 429|14@0+ (1,0) [0|16383] "km" FLZCU
 SG_ HCU_RealMileagHybAfRst_589h : 447|14@0+ (1,0) [0|16383] "km" FLZCU

BO_ 1419 ICC_58Bh: 32 FLZCU
 SG_ TotalOdometer_km_TRIPOBD_58Bh : 151|24@0+ (0.1,0) [0|999999.9] "km" RXCU

BO_ 1432 HCU_RemoteDiag: 32 RXCU
 SG_ HCU_TotalFaultNum : 7|8@0+ (1,0) [0|255] "" FLZCU
 SG_ HCU_FrameIndex : 12|5@0+ (1,0) [0|31] "" FLZCU
 SG_ HCU_SupplierNum : 15|3@0+ (1,0) [0|7] "" FLZCU
 SG_ HCU_FaultNum1 : 23|12@0+ (1,0) [0|4095] "" FLZCU
 SG_ HCU_FaultNum2 : 27|12@0+ (1,0) [0|4095] "" FLZCU
 SG_ HCU_FaultNum3 : 47|12@0+ (1,0) [0|4095] "" FLZCU
 SG_ HCU_FaultNum4 : 51|12@0+ (1,0) [0|4095] "" FLZCU
 SG_ HCU_FaultNum5 : 71|12@0+ (1,0) [0|4095] "" FLZCU
 SG_ HCU_FaultNum6 : 75|12@0+ (1,0) [0|4095] "" FLZCU
 SG_ HCU_FaultNum7 : 95|12@0+ (1,0) [0|4095] "" FLZCU
 SG_ HCU_FaultNum8 : 99|12@0+ (1,0) [0|4095] "" FLZCU
 SG_ HCU_FaultNum9 : 119|12@0+ (1,0) [0|4095] "" FLZCU
 SG_ HCU_FaultNum10 : 123|12@0+ (1,0) [0|4095] "" FLZCU
 SG_ HCU_FaultNum11 : 143|12@0+ (1,0) [0|4095] "" FLZCU
 SG_ HCU_FaultNum12 : 147|12@0+ (1,0) [0|4095] "" FLZCU
 SG_ HCU_FaultNum13 : 167|12@0+ (1,0) [0|4095] "" FLZCU
 SG_ HCU_FaultNum14 : 171|12@0+ (1,0) [0|4095] "" FLZCU
 SG_ HCU_FaultNum15 : 191|12@0+ (1,0) [0|4095] "" FLZCU
 SG_ HCU_FaultNum16 : 195|12@0+ (1,0) [0|4095] "" FLZCU
 SG_ HCU_FaultNum17 : 215|12@0+ (1,0) [0|4095] "" FLZCU
 SG_ HCU_FaultNum18 : 219|12@0+ (1,0) [0|4095] "" FLZCU
 SG_ HCU_FaultNum19 : 239|12@0+ (1,0) [0|4095] "" FLZCU
 SG_ HCU_FaultNum20 : 243|12@0+ (1,0) [0|4095] "" FLZCU

BO_ 1445 HCU_5A5h: 64 RXCU
 SG_ HCU_SumFuCnsThisTrip : 23|9@0+ (0.1,0) [0|50] "L/100km" FLZCU
 SG_ HCU_SumElecCnsThisTrip : 30|12@0+ (0.1,-100) [-100|100] "kwh/100km" FLZCU
 SG_ HCU_SumEgyCnsThisTrip : 34|9@0+ (0.1,0) [0|50] "L/100km" FLZCU
 SG_ TotalOdometer_km_virtual_5A5h : 87|24@0+ (0.1,0) [0|999999.9] "km" FLZCU

BO_ 1453 ICC_BD_49: 48 FLZCU
 SG_ ICC_BedStatus : 39|3@0+ (1,0) [0|7] "" RXCU

BO_ 1508 VCU_Version: 8 RXCU
 SG_ VCU_SoftWareVersion : 23|16@0+ (1,0) [0|65535] "" Vector__XXX
 SG_ VCU_IntVersion : 39|8@0+ (1,0) [0|255] "" Vector__XXX
 SG_ VCU_CalVersion : 47|8@0+ (1,0) [0|255] "" Vector__XXX

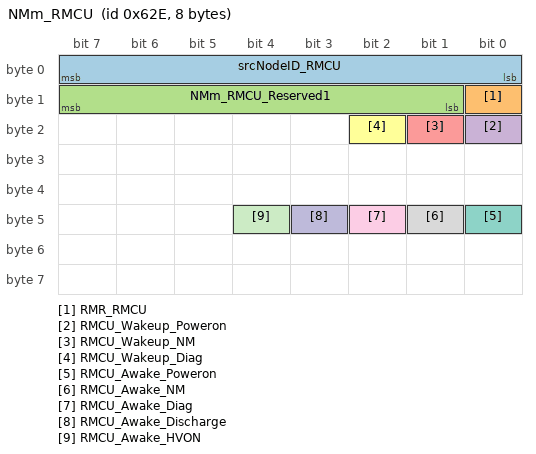
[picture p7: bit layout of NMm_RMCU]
BO_ 1582 NMm_RMCU: 8 RXCU
 SG_ srcNodeID_RMCU : 7|8@0+ (1,0) [0|255] "" Vector__XXX
 SG_ RMR_RMCU : 8|1@0+ (1,0) [0|1] "" Vector__XXX
 SG_ NMm_RMCU_Reserved1 : 15|7@0+ (1,0) [0|127] "" Vector__XXX
 SG_ RMCU_Wakeup_Poweron : 16|1@0+ (1,0) [0|1] "" Vector__XXX
 SG_ RMCU_Wakeup_NM : 17|1@0+ (1,0) [0|1] "" Vector__XXX
 SG_ RMCU_Wakeup_Diag : 18|1@0+ (1,0) [0|1] "" Vector__XXX
 SG_ RMCU_Awake_Poweron : 40|1@0+ (1,0) [0|1] "" Vector__XXX
 SG_ RMCU_Awake_NM : 41|1@0+ (1,0) [0|1] "" Vector__XXX
 SG_ RMCU_Awake_Diag : 42|1@0+ (1,0) [0|1] "" Vector__XXX
 SG_ RMCU_Awake_Discharge : 43|1@0+ (1,0) [0|1] "" Vector__XXX
 SG_ RMCU_Awake_HVON : 44|1@0+ (1,0) [0|1] "" Vector__XXX

CM_ BO_ 1184 "TMS发到总线的内部变量，方便查问题用";
CM_ BO_ 1195 "从休眠到唤醒：此帧快发20次，唤醒后：此阵按正常快发5次";
CM_ BO_ 1219 "TMS测试报文";
CM_ BO_ 1246 "TMS测试报文";
CM_ BO_ 1288 "ICC收到此帧报文后通过ICC_COM_8（0x510）转发出去";
CM_ BO_ 1298 "捷途新增";
CM_ BO_ 1360 "触发一次发送三帧有效+三帧 Not Active";
CM_ BO_ 1453 "捷途V1.3新增";
CM_ SG_ 1170 HVHRu "HVHR_Voltage
后高压电加热器电压";
CM_ SG_ 1170 HVHRi "HVHR_Current
后高压电加热器电流";
CM_ SG_ 1170 HVHR_Sts "HVHR_Status
后高压电加热器状态";
CM_ SG_ 1172 ExternalTemperature_C "External_temperature（℃）
Invalid:_When_external_temperature_is_fail,_the_signal_value_is_0xFE.";
CM_ SG_ 1172 CirculationModeDisplaySts "Circulation_Mode_Status
循环风门状态";
CM_ SG_ 1174 ICC_SetChrgnFctMem "强制保电记忆开关设置";
CM_ SG_ 1174 CTP_PowerModeSet "动力模式设置";
CM_ SG_ 1174 ICC_EmissionMode "设置排放检测模式";
CM_ SG_ 1174 IHU_SetSOC "设置电池";
CM_ SG_ 1181 FLZCU_AlcoholLockInputSts "酒精锁输入状态
0：输入无效，不允许上PT ready
1：输入有效，允许上PT ready";
CM_ SG_ 1182 CDU_OBC_3_CRC1 "Profile1A:E2E CRC (SAE J1850 CRC-8) for 8 Bytes
DataID:0x0026";
CM_ SG_ 1182 CDU_OBC_3_RollgCntr1 "Profile1A:E2E Rolling message counter(the maximum value of Alive counter is 14)";
CM_ SG_ 1182 CDU_OBC_3_Resd1 "Profile1A:E2E Reserved";
CM_ SG_ 1182 OBC_ChgCurr "output current";
CM_ SG_ 1182 OBC_ChgVolt "output voltage";
CM_ SG_ 1182 OBC_FaultCode "OBC fault matrix";
CM_ SG_ 1182 CDU_OBC_3_CRC2 "Profile1A:E2E CRC (SAE J1850 CRC-8) for 8 Bytes
DataID:No ASIL requirements.Not configure
CRC Reserved.";
CM_ SG_ 1182 CDU_OBC_3_RollgCntr2 "Profile1A:E2E Rolling message counter(the maximum value of Alive counter is 14)";
CM_ SG_ 1182 CDU_OBC_3_Resd2 "Profile1A:E2E Reserved";
CM_ SG_ 1182 OBC_CPMaxVolt "charger CP MaxVolt value";
CM_ SG_ 1182 CDU_OBC_3_CRC3 "Profile1A:E2E CRC (SAE J1850 CRC-8) for 8 Bytes
DataID:No ASIL requirements.Not configure
CRC Reserved.";
CM_ SG_ 1182 CDU_OBC_3_RollgCntr3 "Profile1A:E2E Rolling message counter(the maximum value of Alive counter is 14)";
CM_ SG_ 1182 CDU_OBC_3_Resd3 "Profile1A:E2E Reserved";
CM_ SG_ 1182 OBC_S2Swtsts "The states of S2 switch.";
CM_ SG_ 1182 CDU_OBC_3_CRC4 "Profile1A:E2E CRC (SAE J1850 CRC-8) for 8 Bytes
DataID:0x0027";
CM_ SG_ 1182 CDU_OBC_3_RollgCntr4 "Profile1A:E2E Rolling message counter(the maximum value of Alive counter is 14)";
CM_ SG_ 1182 CDU_OBC_3_Resd4 "Profile1A:E2E Reserved";
CM_ SG_ 1182 OBC_FaultLevelSts "OBC fault states
OBC故障等级状态（捷途新增等级4，等级5）";
CM_ SG_ 1182 OBC_ElectronicLockSts "Electronic Lock Sts";
CM_ SG_ 1182 OBC_WorkingMode "OBC working states";
CM_ SG_ 1182 OBC_Worksts "default state
steady power phase
steady voltage phase";
CM_ SG_ 1182 OBC_CPLineSts "The CP line status";
CM_ SG_ 1182 CDU_OBC_3_CRC5 "Profile1A:E2E CRC (SAE J1850 CRC-8) for 8 Bytes
DataID:No ASIL requirements.Not configure
CRC Reserved.";
CM_ SG_ 1182 CDU_OBC_3_RollgCntr5 "Profile1A:E2E Rolling message counter(the maximum value of Alive counter is 14)";
CM_ SG_ 1182 CDU_OBC_3_Resd5 "Profile1A:E2E Reserved";
CM_ SG_ 1182 OBC_HV_OutputUnderVolt "high voltage output under voltage";
CM_ SG_ 1182 OBC_HV_OutputOverVolt "high voltage output over voltage";
CM_ SG_ 1182 OBC_HV_OutputShortCircuit "high voltage output circuit short";
CM_ SG_ 1182 OBC_InputUnderVolt "OBC input under voltage";
CM_ SG_ 1182 OBC_InputOverVolt "OBC input over voltage";
CM_ SG_ 1182 OBC_HighCurrOutputFault "OBC output current fault";
CM_ SG_ 1182 OBC_CAN_Fault "CAN fault";
CM_ SG_ 1182 OBC_KL30_UnderVolt "KL30 under voltage";
CM_ SG_ 1182 OBC_MaxInnerAc220VOutPower "车内放电允许最大功率";
CM_ SG_ 1182 OBC_ActInnerAc220VOutPower "车内放电实际功率";
CM_ SG_ 1182 CDU_OBC_3_CRC6 "Profile1A:E2E CRC (SAE J1850 CRC-8) for 8 Bytes
DataID:No ASIL requirements.Not configure
CRC Reserved.";
CM_ SG_ 1182 CDU_OBC_3_RollgCntr6 "Profile1A:E2E Rolling message counter(the maximum value of Alive counter is 14)";
CM_ SG_ 1182 CDU_OBC_3_Resd6 "Profile1A:E2E Reserved";
CM_ SG_ 1184 TDU_1_EAC_Sts "EAC_Status
电动压缩机工作状态";
CM_ SG_ 1184 EAC_u "EAC_Voltage
电动压缩机电压";
CM_ SG_ 1184 EAC_i "EAC_current
电动压缩机电流";
CM_ SG_ 1184 HVHu "HVH_Voltage
高压电加热器电压";
CM_ SG_ 1184 HVHi "HVH_Current
高压电加热器电流";
CM_ SG_ 1184 HVH_Sts "HVH_Status
高压电加热器状态";
CM_ SG_ 1195 BNCM_8_HV_Req "APP请求上下高压";
CM_ SG_ 1199 TCM_1_TrailerSts "Trailer Status send by TCM. Vehicle can use this information to turn off/on some assistance like 'Park Distance Control'. Furthermore it might be used to turn off the fog light on the vehicle when a trailer is connected (at least in germany, there is a law saying that the vehicles fog lamp must not be turned on when a trailer is connected - only the fog of the trailer should be turned on).";
CM_ SG_ 1200 SOC "Battery_state_of_charge";
CM_ SG_ 1200 SOH_SUL "Max_possible_SOC,_reduced_by_sulphation";
CM_ SG_ 1200 SOFV_StopEnable "Battery_voltage_at_cranking_peak_with
pro-discharge";
CM_ SG_ 1200 SOFV_Restart "Battery_voltage_at_cranking_peak_without
pro-discharge";
CM_ SG_ 1200 SOH_LAM "State_of_health_(loss_of_active_mass_),预留";
CM_ SG_ 1200 SOH_COR "State of health (corrosion ),预留";
CM_ SG_ 1200 SOC_STATE "SOC_status";
CM_ SG_ 1200 SOH_SUL_STATE "SOH_SUL_status";
CM_ SG_ 1200 SOFV_StopEnable_STATE "SOFV_StopEnable_status";
CM_ SG_ 1200 SOFV_Restart_STATE "SOFV_Restart status";
CM_ SG_ 1204 VCU_1_G_CRC "Profile1A:E2E CRC (SAE J1850 CRC-8) for 8 Bytes
DataID:0x005C";
CM_ SG_ 1204 VCU_1_G_RollgCntr "Profile1A:E2E Rolling message counter(the maximum value of Alive counter is 14)";
CM_ SG_ 1204 VCU_1_G_Pwr "instant power（股份信号D01未使用）";
CM_ SG_ 1204 VCU_1_G_AcceleratorPosRaw "真实油门开度
Raw position of the accelerator pedal (unfiltered). Represents always raw pedal position without any other influcence only mandatory to calculated gradient acceleration pedal.";
CM_ SG_ 1204 VCU_1_G_PTReady "PT Ready indication";
CM_ SG_ 1204 VCU_1_G_DriveMode "Driving modes（股份信号D01未使用）";
CM_ SG_ 1204 VCU_1_G_HvBattKeepWarmSts "插枪保温状态";
CM_ SG_ 1204 VCU_1_G_HvBattKeepWarmActiveReq "插枪保温开启请求";
CM_ SG_ 1204 VCU_1_G_HundECAver "average consumption per hundred KM（股份信号D01未使用）";
CM_ SG_ 1204 VCU_1_G_BookChrgSetStsFb "预约充电设置与否状态反馈";
CM_ SG_ 1204 VCU_1_G_EgyRegenLevel "power regeneration level（股份信号D01未使用）";
CM_ SG_ 1204 VCU_1_G_PRNDGearAct "Gear indication";
CM_ SG_ 1207 EAC_i_400V "400V EAC current
400V电动压缩机电流（捷途不发，预留）";
CM_ SG_ 1207 HVH_Sts_400V "400V HVH Status
400V高压电加热器状态（捷途不发，预留）";
CM_ SG_ 1207 HVH_U_400V "400V HVH Voltage
400V高压电加热器电压（捷途不发，预留）";
CM_ SG_ 1207 Flag_400V_800V "Flag 400V 800V
400V和800V标志（预留）";
CM_ SG_ 1209 VCU_2_G_CRC "Profile1A:E2E CRC (SAE J1850 CRC-8) for 8 Bytes
DataID:0x005D";
CM_ SG_ 1209 VCU_2_G_RollgCntr "Profile1A:E2E Rolling message counter(the maximum value of Alive counter is 14)";
CM_ SG_ 1209 VCU_2_G_Resd "Profile1A:E2E Reserved";
CM_ SG_ 1209 VCU_2_G_PowerLimit "power limitation indication";
CM_ SG_ 1209 VCU_2_G_BrakeLightReq "break light during regeneration (calibration)";
CM_ SG_ 1209 VCU_2_G_VehicleSystemFailure "vehicle system failure";
CM_ SG_ 1209 OnekeyHVOffSuccess_4B9h "物理开关一键下高压状态反馈（法规要求）";
CM_ SG_ 1209 VCU_2_G_BootloadSts "0x1:software flash";
CM_ SG_ 1209 VCU_2_G_DischgSts "ICM indication Discharging state";
CM_ SG_ 1209 VCU_2_G_BrakePedalStsValidData "制动踏板状态有效";
CM_ SG_ 1209 VCU_2_G_BrakePedalSts "制动踏板状态";
CM_ SG_ 1209 VCU_2_G_HVReady "HV Ready";
CM_ SG_ 1209 Res_VCU_2_G_Brake_state "break signal

RVM legal request";
CM_ SG_ 1209 VCU_2_G_GasPedalPosition "Driver/Cruise control
This signal including compositive informations which are actual gas pedal position and dummy Cruise control gas pedal position";
CM_ SG_ 1209 VCU_2_G_DrvGearShiftFailureIndcn "0x0:No Indication；（仪表不显示）
0x1:换挡请踩刹车；（驾驶员期望换挡但没有踩下制动踏板时以此提示驾驶员。触发后驾驶员踩下制动踏板或4s后停发）
0x2:换挡车速过高
0x3:换挡请拔下充电枪（P挡且交流枪连接或直流枪连接时拨动换挡杆）
0x4: EPB无法锁止
0x5: EPB无法释放
0x6: 无法切换行驶方向（车辆D/R挡时EGS通讯丢失）
0x7: 换挡杆需求维修（EGS通讯丢失超过3个驾驶循环或发生故障AllWarningInfo!=0x0）";
CM_ SG_ 1209 VCU_2_G_OnekeyHVoffStyle "物理开关一键下高压触发类型";
CM_ SG_ 1217 ASU_ECASErrSts_4C1h "ECAS Error Status";
CM_ SG_ 1217 ASU_SuspTarLvl_4C1h "悬架高度反馈
Suspension Target High Level
0x0:No requirement
0x1:Very high level 脱困
0x2:high2 level  越野2
0x3:high1 level  越野1
0x4:normal level 标准
0x5:low level    较低
0x6:very low level 极低
0x7:easy Loading level  载物高度
";
CM_ SG_ 1217 ASU_CDCErrSts_4C1h "CDC error Satus";
CM_ SG_ 1217 ASU_SuspDampingLvl_4C1h "Suspension Target High Level";
CM_ SG_ 1219 VCU_CLMSystemPowerLimit "HVH_power_limit";
CM_ SG_ 1219 HCU_HVHRAllow "APTC允许使能信号
Before?HV?power?off,VCU?will?send?Unable,HVHR?will?prepare?for?HV?shut?down";
CM_ SG_ 1219 VCU_CLMEACAllow "Before?HV?power?off,VCU?will?send?Unable,EAC?will?prepare?for?HV?shut?down";
CM_ SG_ 1219 VCU_CLMHVHAllow "Before?HV?power?off,VCU?will?send?Unable,HVH?will?prepare?for?HV?shut?down";
CM_ SG_ 1219 VCU_CLMHVReady "HV_Ready";
CM_ SG_ 1219 VCU_PwtCoolingLvl "电驱系统冷却等级";
CM_ SG_ 1224 BMS_Chg_Sts "充电状态BMS_Chg_Sts";
CM_ SG_ 1231 TBOX_1_BookChrgActiveReq "起始充电时间到/请求充电;
VCU/IHU收服务化信号，TBOX同步转成CAN信号BNCM收；";
CM_ SG_ 1231 TBOX_BookChrgSetReq "TBOX预约充电开启/取消设置请求";
CM_ SG_ 1231 TBOX_StopChrgReq "结束充电请求";
CM_ SG_ 1231 TBOX_KeepWarmSet "TBOX插枪保温设置";
CM_ SG_ 1231 TBOX_HV_Req "TBOX远程高压上下电";
CM_ SG_ 1231 TBOX_BookChrgSts "预约充电状态";
CM_ SG_ 1231 TBOX_ChgSOCSet_4CFh "TBOX远程充电SOC设置
Charge target SOC";
CM_ SG_ 1231 TBOX_HvBattKeepWarmActiveReq "电池保温请求";
CM_ SG_ 1231 TBOX_ChgSOCPrioritySts_4CFh "充电优先级设置反馈
0x0:充电时长优先/充满优先（交流预约充电时）
0x1:SOC设置优先";
CM_ SG_ 1239 ICC_DisChg "Discharge switch";
CM_ SG_ 1239 ICC_DisChgPercent "discharge limit set SOC(ICC确认发送)";
CM_ SG_ 1239 ICC_ChgSocSet "Charge target SOC(ICC确认发送)";
CM_ SG_ 1239 ICC_TowingMode "打开/关闭拖车模式服务";
CM_ SG_ 1239 ICC_CampMode "露营模式开启/关闭";
CM_ SG_ 1239 ICC_StCleverMainReq_4D7h "智慧能量管理设置请求";
CM_ SG_ 1239 ICC_StCleverRgnReq_4D7h "智慧能量回收设置请求";
CM_ SG_ 1239 ICC_EnergySavingModeReq_4D7h "节能模式设置请求";
CM_ SG_ 1239 ICC_StCleverDrvReq_4D7h "智慧驾驶风格设置请求";
CM_ SG_ 1239 ICC_FacCleverDrvActRst_4D7h "运动因子重置";
CM_ SG_ 1239 ICC_EngyVehSpdLi_4D7h "限速设置";
CM_ SG_ 1239 ICC_DischgSetSOC_4D7h "放电SOC设置
0x0:Not Active
0xFE:Abnormal
0xFF:Invalid";
CM_ SG_ 1246 ICC_KeepWarm "Keep Warm Working Status Set
恒温模式工作状态设置";
CM_ SG_ 1248 FRZCU_RKEButtAct "RKE钥匙按键动作
增加0x2:RemoteLongPress（检测到用户按下钥匙启动按键后触发）";
CM_ SG_ 1250 ICC_1_OTAHV_Req "OTA high voltage power down request";
CM_ SG_ 1250 ICC_SteeringMode "个性化-转向模式设置";
CM_ SG_ 1250 ICC_SuspensionDamping "个性化-悬架阻尼设置";
CM_ SG_ 1250 ICC_SuspensionHeight "个性化-悬架高度设置";
CM_ SG_ 1250 ICC_SelfClearing "能耗分布自清零指令";
CM_ SG_ 1250 ICC_PetModeHV_Req "宠物模式高压请求";
CM_ SG_ 1250 ICC_SentinelHV_Req "哨兵模式高压请求";
CM_ SG_ 1250 ICC_CCMReq_4E2h "攀爬模式动画场景显示请求
0x0:不动作
0x1:沙地脱困
0x2:雪地暴行
0x3:攀爬挑战
0x4:丛林探路
0x5:拔河
0x6:救援";
CM_ SG_ 1250 ICC_TRIPSelfClearing_4E2h "本次里程自清零信号外发";
CM_ SG_ 1252 TotalOdometer_km_OBD "GB18285-2018新增OBD输出检查要求车辆累积行驶里程信号。";
CM_ SG_ 1265 ICC_CinemaStatus "影院模式状态";
CM_ SG_ 1268 CRC1_4F4h "Profile1A:E2E CRC (SAE J1850 CRC-8) for 8 Bytes
DataID:Reserved";
CM_ SG_ 1268 RollgCntr1_4F4h "Profile1A:E2E Rolling message counter(the maximum value of Alive counter is 14)";
CM_ SG_ 1268 SOCE_4F4h "发送SOCE
battery SOCE
0x3FE:Abnormal
0x3FF:Invalid";
CM_ SG_ 1268 CRC2_4F4h "Profile1A:E2E CRC (SAE J1850 CRC-8) for 8 Bytes
DataID:Reserved";
CM_ SG_ 1268 RollgCntr2_4F4h "Profile1A:E2E Rolling message counter(the maximum value of Alive counter is 14";
CM_ SG_ 1268 HvBattEgyTotal_4F4h "总吞吐能量
0xFFFFE:Abnormal
0xFFFFF:Invalid";
CM_ SG_ 1268 HvBattV2XTotal_4F4h "V2X总放电能量
0xFFFFE:Abnormal
0xFFFFF:Invalid";
CM_ SG_ 1268 CRC3_4F4h "Profile1A:E2E CRC (SAE J1850 CRC-8) for 8 Bytes
DataID:Reserved";
CM_ SG_ 1268 RollgCntr3_4F4h "Profile1A:E2E Rolling message counter(the maximum value of Alive counter is 14)";
CM_ SG_ 1268 HvBattNoDrivEgyTotal_4F4h "非驱动总能量
0xFFFFE:Abnormal
0xFFFFF:Invalid";
CM_ SG_ 1288 CurrentTimeYear_508h "GPS时间（年）";
CM_ SG_ 1288 CurrentTimeMonth_508h "GPS时间（月）";
CM_ SG_ 1288 CurrentTimeDay_508h "GPS时间（日）";
CM_ SG_ 1288 CurrentTimeHour_508h "GPS时间（时）";
CM_ SG_ 1288 CurrentTimeMinute_508h "GPS时间（分）";
CM_ SG_ 1288 CurrentTimeSecond_508h "GPS时间（秒）";
CM_ SG_ 1288 TboxLocalTiValid "本地时间有效位";
CM_ SG_ 1290 BMS_HvBattCellUnderU "电池电芯欠压故障
（默认发0，检测到电芯欠压时根据阈值发送过压等级)";
CM_ SG_ 1290 BMS_HvBattUnderU "电池包总压欠压故障
（默认发0，检测到电池过压时根据阈值发送过压等级)";
CM_ SG_ 1291 BMS_SOCLight "BMS SOCLight
SOC电量显示（仪表显示）";
CM_ SG_ 1296 CurrentTimeYear "时间（年)";
CM_ SG_ 1296 CurrentTimeMonth "时间（月）";
CM_ SG_ 1296 CurrentTimeDay "时间（日）";
CM_ SG_ 1296 CurrentTimeHour "时间（时）";
CM_ SG_ 1296 CurrentTimeMinute "时间（分）";
CM_ SG_ 1296 CurrentTimeSecond "时间（秒）";
CM_ SG_ 1298 APTC_ErrorLevel "APTC故障等级
0x0:正常
0x1:轻微故障
0x2:一般故障
0x3:严重故障";
CM_ SG_ 1298 APTC_ErrorCode2 "APTC故障码
0x00:无故障
Bit0:_高压互锁(ErrorLevel=1)
Bit1:CAN通讯超时(ErrorLevel=1)
Bit2:IGBT驱动15V电超范围故障(ErrorLevel=1)
Bit3低压超范围故障:(ErrorLevel=1)";
CM_ SG_ 1314 HCU_CRC1_522h "Profile1A:E2E CRC (SAE J1850 CRC-8) for 8 Bytes
DataID:Reserved";
CM_ SG_ 1314 HCU_RollgCntr1_522h "Profile1A:E2E Rolling message counter(the maximum value of Alive counter is 14)";
CM_ SG_ 1314 HCU_V2lDisChgBck "V2L外放电开关反馈";
CM_ SG_ 1314 HCU_DisChgMemFed "V2L外放电记忆开关反馈";
CM_ SG_ 1314 HCU_V2VDisChgBck "V2V放电开关反馈";
CM_ SG_ 1314 HCU_V2l_IntlDisChgBck "V2L内放电开关反馈";
CM_ SG_ 1314 HCU_FuelDetnOpDefeated "燃油检测开启失败提示";
CM_ SG_ 1314 HCU_FuelDetnModSwtFed "燃油检测开关反馈";
CM_ SG_ 1314 HCU_FuelDetnStateFed "燃油检测模式状态反馈";
CM_ SG_ 1314 HCU_HVDownRepairModeFed "断高压维修模式开关反馈";
CM_ SG_ 1314 HCU_SumFuCns "自清零后累计百公里油耗显示(仅仪表使用)";
CM_ SG_ 1314 HCU_TrailerMode "被拖模式开关反馈";
CM_ SG_ 1314 HCU_TABSwtFed_522h "ICC坦克转向开关反馈
0x0:Not_Active 使能位
0x1:Active 激活
0x2:Stand_by 就绪
0x3:Failed 失败";
CM_ SG_ 1314 HCU_MotSelfHeatLvlReq "电驱自发热档位需求";
CM_ SG_ 1314 HCU_MotSelfHeatEnReq "电驱自发热使能开关";
CM_ SG_ 1314 HCU_KeyDriveModememory "驾驶模式记忆开关反馈";
CM_ SG_ 1314 HCU_DrivePowerDispSetFed "驱动系统功率显示方式开关反馈";
CM_ SG_ 1314 HCU_TCMStsReq_522h "TCM使能状态";
CM_ SG_ 1314 HCU_EXPERTNormFed "专家模式动力设置标准模式开关反馈";
CM_ SG_ 1314 HCU_4LModeFed "低速四驱开关反馈";
CM_ SG_ 1314 HCU_EXPERTEcoFed "专家模式动力设置柔和模式开关反馈";
CM_ SG_ 1314 HCU_SingleRegnRmn "当车机收到HCU发送信号“HCU_SingleRegnRmn =0x1”时，弹框提示“单踏板受限已退出，请注意安全驾驶！”，并播放报警音持续3s；
当车机收到HCU发送信号“HCU_SingleRegnRmn=0x0”时，停止提示，并停止报警音；";
CM_ SG_ 1314 HCU_DRIFTModeSts "通过大屏设置漂移模式灵敏度开关反馈
0x0:不动作
0x1:入门
0x2:大师
0x3:专家";
CM_ SG_ 1314 HCU_CRC2_522h "Profile1A:E2E CRC (SAE J1850 CRC-8) for 8 Bytes
DataID:Reserved";
CM_ SG_ 1314 HCU_RollgCntr2_522h "Profile1A:E2E Rolling message counter(the maximum value of Alive counter is 14)";
CM_ SG_ 1314 HCU_EXPERTAWDFed "专家模式驱动形式四驱开关设置反馈";
CM_ SG_ 1314 HCU_EXPERTRWDFed "专家模式驱动形式后驱开关设置反馈";
CM_ SG_ 1314 HCU_CrossaxisFed "专家模式交叉轴模式开关设置反馈";
CM_ SG_ 1314 HCU_EXPERTSportFed "专家模式动力设置激进模式开关反馈";
CM_ SG_ 1314 HCU_StopChrgnModeFed "驻车发电模式开关反馈";
CM_ SG_ 1314 HCU_StopChrgnFed "驻车发电开关反馈";
CM_ SG_ 1314 HCU_CLIMBFed "防溜设置开关反馈";
CM_ SG_ 1314 HCU_EXPERTAutoFed "专家模式驱动形式Auto开关设置反馈";
CM_ SG_ 1314 HCU_HEV_FunctionLimit "仪表文字提示“HEV模式不可用”";
CM_ SG_ 1314 HCU_ParkingChargeReminder "仪表文字提示“请先驻车再充电”";
CM_ SG_ 1314 HCU_PowerCut "仪表文字提示“动力即将切断，请靠边停车”";
CM_ SG_ 1314 HCU_IMMOReleaseSignal "防盗报警指示灯信号";
CM_ SG_ 1314 HCU_LVPowSupSYSAbn_lit "低压供电系统异常状态";
CM_ SG_ 1314 HCU_ChrgnFctMemSt "强制保电记忆开关反馈";
CM_ SG_ 1314 HCU_PowerModeChangeInhibit "仪表文字提示“为保障越野性能，模式无法切换”";
CM_ SG_ 1314 HCU_DisconnectChagWarn "仪表文字提示“请拔下充电枪”";
CM_ SG_ 1314 HCU_EngineRunClmReq "仪表文字提示“空调请求发动机运行中”";
CM_ SG_ 1314 HCU_VehicleSpeedMax_Limit "仪表文字提示“最高车速受限，请尽快联系售后检修”";
CM_ SG_ 1314 HCU_AccleAbility_Limit "仪表文字提示“加速性能受限，请尽快联系售后检修”";
CM_ SG_ 1314 HCU_DriveInhibit_GearP "仪表文字提示“动力受限，进入P挡后无法再次行驶，请尽快联系售后检修”";
CM_ SG_ 1314 HCU_SetModeNotChange "仪表文字提示“模式禁止切换”";
CM_ SG_ 1314 HCU_UTURNSnowFed "极限调头雪地场景反馈";
CM_ SG_ 1314 HCU_PowerLevel "仪表驱动能力等级";
CM_ SG_ 1314 HCU_TowingModeEna "大屏被拖提醒文字提示ICC接收
0x1时，大屏文字提示“切换至被拖模式需满足以下条件：1、挡位处于P挡；2、踩下刹车；3、车辆不在充电状态”";
CM_ SG_ 1314 HCU_LeaveVehicleWarning "仪表声音提醒";
CM_ SG_ 1314 HCU_DedicatedModeInhibit "仪表文字提示“当前模式不可用，请切换至越野模式”";
CM_ SG_ 1314 HCU_DisChargeStopFault "0x1时仪表文字提示“电池电量过低，放电停止”0x2时仪表文字提示“燃油不足，放电停止”";
CM_ SG_ 1314 HCU_RearEDLSts "后差速锁状态
0x0:不锁
0x1:解锁
0x2:锁止
0x3:切换提醒
0x4:不满足锁止条件
0x5:差速锁无法锁止故障
0x6:差速锁无法解锁故障";
CM_ SG_ 1314 HCU_FrntEDLSts "前差速锁状态
0x0: 不锁
0x1: 解锁
0x2：锁止
0x3：切换提醒
0x4：不满足锁止条件
0x5：差速锁无法锁止故障
0x6：差速锁无法解锁故障
0x7：提示需挂入后锁和4L
0x8：提示开启后锁
0x9：提示开启4L";
CM_ SG_ 1314 HCU_CRC3_522h "Profile1A:E2E CRC (SAE J1850 CRC-8) for 8 Bytes
DataID:Reserved";
CM_ SG_ 1314 HCU_RollgCntr3_522h "Profile1A:E2E Rolling message counter(the maximum value of Alive counter is 14)";
CM_ SG_ 1314 HCU_CruiseLimitSpeedValue "定速巡航设定车速";
CM_ SG_ 1314 HCU_DriveMode_JT "驾驶模式反馈
0x0:经济
0x1:标准
0x2:运动
0x3:雪/草地
0x4:泥地
0x5:越野
0x6:沙地
0x7:岩石
0x8:专家
0x9:智能
0xA:涉水
0xB:极限掉头
0xC:漂移
0xD:拖挂
0xE:越野竞速
0xF:晕车舒缓
0x10:智慧能量管理
0x11:纵横征服
0x12~0x1F：预留";
CM_ SG_ 1314 HCU_SocManageFed "Soc_Manage_Feedback";
CM_ SG_ 1314 HCU_SinglePedalMemFed "单踏板记忆开关反馈";
CM_ SG_ 1314 HCU_CCOSwtFed "越野蠕行开关反馈";
CM_ SG_ 1314 HCU_Pwr "instant_power";
CM_ SG_ 1314 HCU_UTURNSandFed "极限调头泥地场景开关反馈";
CM_ SG_ 1314 HCU_CruiseControlStatus "定速巡航指示灯";
CM_ SG_ 1314 HCU_EXPERTEESPSet "关闭牵引力控制系统&车身稳定控制系统（TCS&VDC_OFF）
全开（TCS、VDC等与ESP有关功能全部开启）
全关（TCS、VDC及RMI放侧翻、DTC发动机拖滞力矩管理）";
CM_ SG_ 1314 HCU_EgyRegenLevel "power_regeneration_level";
CM_ SG_ 1314 HCU_CRC4_522h "Profile1A:E2E CRC (SAE J1850 CRC-8) for 8 Bytes
DataID:0x0114";
CM_ SG_ 1314 HCU_RollgCntr4_522h "Profile1A:E2E Rolling message counter(the maximum value of Alive counter is 14)";
CM_ SG_ 1314 HCU_EngyFlowToDisp "0x0:初始化
0x1:无能量流状态
0x2:发动机单独运行
0x3:纯电前驱
0x4:纯电前驱回馈
0x5:纯电后驱
0x6:纯电后驱回馈
0x7:纯电四驱
0x8:纯电四驱回馈
0x9:串联前驱电池充电
0xA:串联前驱电池放电
0xB:串联前驱电池无电流
0xC:串联前驱回馈
0xD:串联后驱电池充电
0xE:串联后驱电池放电
0xF:串联后驱电池无电流
0x10:串联后驱回馈
0x11:串联四驱电池充电
0x12:串联四驱电池放电
0x13:串联四驱电池无电流
0x14:串联四驱回馈
0x15:并联前驱电池充电
0x16:并联前驱电池放电
0x17:并联前驱电池无电流
0x18:并联前驱回馈
0x19:并联四驱电池充电
0x1A:并联四驱电池放电
0x1B:并联四驱电池无电流
0x1C:并联四驱回馈
0x1D:原地发电电池充电
0x1E:原地发电电池放电
0x1F:原地发电电池无电流";
CM_ SG_ 1314 HCU_UTURNGrassFed "极限调头草地场景反馈";
CM_ SG_ 1314 HCU_UTURNMudFed "极限调头沙地场景开关反馈";
CM_ SG_ 1314 HCU_LTCDispFed "续航里程选择开关反馈";
CM_ SG_ 1314 HCU_iTAS_Warn "0x0: 无提示
0x1:iTAS功能已激活，无法锁止后桥差速锁
0x2:请释放EPB
0x3:当前车速过高，请减速
0x4：制动盘温度过高，极限掉头功能已退出
0x5：车辆被卡住，极限掉头功能退出
0x6：极限掉头使用时间到达极限，功能退出
0x7：请切换至D档开启极限掉头";
CM_ SG_ 1314 HCU_iCCO_Warn "0x0: 无提示
0x1:请释放EPB
0x2:当前车速过高，请减速
0x3:请关好车门，系好安全带
0x4:请切换至D档或N档开启越野蠕行
0x5:请关闭 APA/ACC/CC巡航
0x6:请退出HDC陡坡缓降/自动驻车
0x7:请手动切换驾驶模式至雪地或泥地或沙地或岩石
0x8:请踩制动踏板
0x9:iCCO越野蠕行已退出";
CM_ SG_ 1314 HCU_DriveModeChangeFail "驾驶模式切换不满足条件，提示“请停车后退出当前驾驶模式”";
CM_ SG_ 1314 HCU_25_Crossaxis_Warn "0x0: 无提示
0x1:请释放EPB
0x2:当前车速过高，交叉轴功能已退出
0x3:请切换至D档开启交叉轴功能
0x4:请关好车门，系好安全带
0x5:请将车辆静止后踩制动踏板
0x6:进入交叉轴模式后进行空簧高度调节";
CM_ SG_ 1314 HCU_25_EDLFed "中央差速锁显示信号";
CM_ SG_ 1314 HCU_DraggingModeRemind "0x0: 无提示
0x1:禁用ECO和越野模式
0x2:拖挂模式下仅支持Normal和Sport
0x3:ECO和越野模式恢复
0x4~0x7:预留";
CM_ SG_ 1314 HCU_iTASSceneReq "iTAS场景选择信息";
CM_ SG_ 1314 HCU_25_iTAS_SlopWarn "极限调头坡度条件不满足提醒
0x0:无提示
0x1:地面坡度过大
0x2~0x3:Reserved";
CM_ SG_ 1314 HCU_ExterTempLowHint "0x0:无提示
0x1:环境温度低切换为HEV模式
0x2:环境温度过低发动机运行中";
CM_ SG_ 1314 HCU_iTAS_Active "极限掉头激活状态（仪表）";
CM_ SG_ 1314 HCU_25_VehSpdOffroadRmn "漂移，掉头，专家，交叉轴，越野蠕行，越野竞速功能，用户在车辆未静止状态下点退出按钮或硬开关，仪表接收该信号0x1后显示“请将车辆禁止后再设置”";
CM_ SG_ 1314 HCU_DrivingModReq "HCU给IPB映射驾驶模式";
CM_ SG_ 1314 HCU_25_ADS_FctSts "智能驾驶功能激活状态";
CM_ SG_ 1314 HCU_25_DRIFTModeSetReq "漂移灵敏度开启信号(HCU判断完成后外发)";
CM_ SG_ 1314 HCU_25_CrossaxisReq "交叉轴开启信号(HCU判断完成后外发)";
CM_ SG_ 1314 HCU_25_CCOSwtReq "CCO开启信号(HCU判断完成后外发)";
CM_ SG_ 1314 HCU_CRC5_522h "Profile1A:E2E CRC (SAE J1850 CRC-8) for 8 Bytes
DataID:Reserved";
CM_ SG_ 1314 HCU_RollgCntr5_522h "Profile1A:E2E Rolling message counter(the maximum value of Alive counter is 14)";
CM_ SG_ 1314 HCU_25_ErrorCode "HCU接收各控制器故障等级后处理的故障码";
CM_ SG_ 1314 HCU_25_ErrorCount "用于上报当前HCU故障总数";
CM_ SG_ 1314 HCU_25_iDRIFT_Warn "0x0:无提示
0x1:请关好车门，系好安全带
0x2:请将车辆停止
0x3:系统故障，漂移模式暂无法开启
0x4:进入漂移模式后进行空簧高度调节";
CM_ SG_ 1314 HCU_25_SetVehSpdOffroad "越野模式切换车速条件不满足提示
0x0:无提示
0x1:请将车辆静止后再设置
0x2~0x3:Reserved";
CM_ SG_ 1314 HCU_25_LaunchMod_Warn "越野竞速弹射模式弹窗提示
0x0:无提示
0x1:弹射模式已激活，松开制动踏板，开始弹射
0x2:弹射模式已退出
0x3:条件不满足，弹射模式不可用
0x4~0x7:Reserved";
CM_ SG_ 1314 HCU_25_TAB_Warn "TAB功能提醒(T1J FL2华为智驾使用，D01及D01华为智驾版不使用)";
CM_ SG_ 1314 HCU_25_CCO_TextDisp "CCO功能提示信息
越野蠕行功能提示
(T1J FL2华为智驾使用，D01及D01华为智驾版不使用)";
CM_ SG_ 1314 HCU_25_DCM_Warn "纵横征服功能提示
0x0:No_Warn
0x1:请释放 EPB
0x2:请关好车门,系好安全带
0x3:请切换至D/R档开启攀爬模式
0x4:请关闭APA/ACC/CC巡航
0x5:请退出HDC 陡坡缓降/AVH自动驻车
0x6:请踩制动踏板
0x7:纵横征服 已退出
0x8: 请在车辆静止时进入或退出该模式
0x9:功率限制，功能无法正常使用
0xA: 请丢开加速踏板
0xB:请踩制动
0xC~0xF:Reserved";
CM_ SG_ 1314 HCU_25_CCMFed "攀爬设置开关反馈";
CM_ SG_ 1314 HCU_25_TABReq "HCU发送TAB功能请求(T1J FL2华为智驾使用，D01及D01华为智驾版不使用)";
CM_ SG_ 1314 HCU_SumElecCns "自清零后累计百公里电耗显示(仅仪表使用)";
CM_ SG_ 1314 HCU_CrossBorderSts "HCU 反馈飞车模式执行情况
0x1: On 表示飞车模式限制已开启
0x2: Off 表示飞车模式限制未开启";
CM_ SG_ 1314 HCU_DischgSetSOCFed "放电SOC设置状态反馈
0xFE:Abnormal
0xFF:Invalid";
CM_ SG_ 1314 HCU_facCleverDrvAct_522h "驾驶运动因子";
CM_ SG_ 1314 HCU_stCleverDrvAct_522h "智慧驾驶风格状态";
CM_ SG_ 1314 HCU_stCleverRgnAct_522h "智慧能量回收状态";
CM_ SG_ 1314 HCU_stCleverMainAct_522h "智慧能量管理状态";
CM_ SG_ 1314 EnergySavingModeSts_522h "节能模式设置反馈";
CM_ SG_ 1314 HCU_facCleverDrvActRstFed_522h "驾驶运动因子重置反馈";
CM_ SG_ 1314 HCU_SailramainingT_Indc_522h "剩余航行时间（对比）,真实显示的";
CM_ SG_ 1314 HCU_ATCM_Operation_REQ_522h "航行模式按键确认信号
0x0:Not Active
0x1:进入航行提示  Switch to sailfunc indiction
0x2:进入上滩提示Switch to upbeach indiction
0x3:陆地时点击航行物理开关误操作提示 misoperation indiction: press sailfunc sw when conenmod 
0x4:陆地时点击上滩物理开关误操作提示misoperation indiction: press upbeach  sw when conenmod 
0x5:涉水时点击上滩物理开关误操作提示misoperation indiction: press upbeach sw when wadests
0x6:reserved
0x7:reserved";
CM_ SG_ 1314 HCU_ModeSwFailureIndc_522h "模式切换失效提示
0x0: Not Active
0x1:进入航行失败：车门未关
Entry navigation failed: Car door is not closed
0x2：进入航行失败：后视镜未展开
Entry navigation failed: Rearview mirror not deployed
0x3:进入航行失败：进排气防水阀故障
Entry navigation failed: Intake and exhaust waterproof valve malfunction
0x4：进入航行失败：车速过大
Entry navigation failed: Speed too fast
0x5：进入航行失败：电量过低
Entry navigation failed: Low battery
0x6：进入航行失败：空调放水阀故障|散热风扇故障
Entry navigation failed: Air conditioning drain valve malfunction| Cooling fan malfunction";
CM_ SG_ 1314 HCU_Sailmode_522h "涉水模式
0x0:Convenmod
0x1:SalWadeSts  浅涉水
0x2:DpWadeSts 深涉水（保留）
0x3:SailingFunc  航行
0x4:UpbeachSts  上滩
0x5:WaitfinspSts 待检（保留）
0x6:EmerfloatingSts 应急浮水
0x7:Reserved2";
CM_ SG_ 1314 HCU_CarSickRelfModeFb "晕车舒缓状态反馈";
CM_ SG_ 1314 HCU_DeepSnowSts_522h "深雪模式状态信号";
CM_ SG_ 1314 DriveModeChangeFailReason_522h "驾驶模式切换失败原因提示";
CM_ SG_ 1314 HCU_CLIMBDisReason_522h "攀爬防溜设置失败原因提示
0x0:不提醒
0x1:请踩刹车上Ready
0x2:请挂入D档或N档
0x3:请切换到岩石模式
0x4:底盘限扭系统激活
0x5:请关闭智驾功能后重试
0x6:请减速后重试
0x7:驱动系统故障
0x8:纵向加速度无效
0x9:请退出越野蠕行
0xA:制动辅助不可用
0xB:IPB系统故障";
CM_ SG_ 1314 HCU_CarSickRelfModeDisReason "晕车舒缓开启失败原因
0x0:不提示
0x1:请退出越野模式
0x2:请退出越野蠕行
0X3:请退出节能模式
0X4:请退出拖挂模式
0X5:请退出被拖模式
0X6:请退出定速巡航模式
0X7:请退出智驾模式";
CM_ SG_ 1314 HCU_DCMSwtFed "纵横征服模式场景
0x0:not active
0x1:泥沙脱困
0x2:雪地暴行
0x3:攀爬挑战
0x4:丛林探路
0x5:拔河
0x6:救援
0x7:Reserved";
CM_ SG_ 1314 HCU_LightSandSts_522h "浅沙模式：
0x0:信号无作用
0x1:浅沙模式激活
0x1:浅沙模式关闭";
CM_ SG_ 1316 LHFTirePressure "左前方位轮胎胎压";
CM_ SG_ 1316 RHFTirePressure "右前方位轮胎胎压";
CM_ SG_ 1316 LHRTirePressure "左后方位轮胎胎压";
CM_ SG_ 1316 RHRTirePressure "右后方位轮胎胎压";
CM_ SG_ 1324 TirePositionWarning_LHFTire "左前方位轮胎胎压报警，含快速失压、低压、高压、高温。";
CM_ SG_ 1324 TirePositionWarning_RHFTire "右前方位轮胎胎压报警，含快速失压、低压、高压、高温。";
CM_ SG_ 1324 TirePositionWarning_LHRTire "左后方位轮胎胎压报警，含快速失压、低压、高压、高温。";
CM_ SG_ 1324 TirePositionWarning_RHRTire "右后方位轮胎胎压报警，含快速失压、低压、高压、高温。";
CM_ SG_ 1329 HCU_27_CRC "Profile1A:E2E CRC (SAE J1850 CRC-8) for 8 Bytes
DataID:No ASIL requirements.Not configure
CRC Reserved.";
CM_ SG_ 1329 HCU_27_RollgCntr "Profile1A:E2E Rolling message counter(the maximum value of Alive counter is 14)";
CM_ SG_ 1329 HCU_27_Resd "Profile1A:E2E Reserved";
CM_ SG_ 1329 HCU_27_DriveMode_JT "驾驶模式反馈
0x0：经济
0x1：标准
0x2：运动
0x3：雪/草地
0x4: 泥地
0x5: 越野
0x6: 沙地
0x7: 岩石
0x8: 专家
0x9: 智能
0xA: 涉水
0xB: 极限掉头
0xC: 漂移
0xD: 拖挂
0xE: 越野竞速
0xF:晕车舒缓
0x10:智慧能量管理
0x11:纵横征服
0x12~0x1F：预留";
CM_ SG_ 1329 HCU_27_4LModeFed "低速四驱开关反馈";
CM_ SG_ 1329 HCU_27_CCOSwtFed "越野蠕行开关反馈";
CM_ SG_ 1329 HCU_27_FrntEDLSts "前差速锁状态
0x0:不锁
0x1:解锁
0x2：锁止
0x3：切换提醒
0x4：不满足锁止条件
0x5：差速锁无法锁止故障
0x6：差速锁无法解锁故障
0x7：提示需挂入后锁和4L
0x8：提示开启后锁
0x9：提示开启4L";
CM_ SG_ 1329 HCU_27_RearEDLSts "后差速锁状态
0x0:不锁
0x1:解锁
0x2：锁止
0x3：切换提醒
0x4：不满足锁止条件
0x5：差速锁无法锁止故障
0x6：差速锁无法解锁故障";
CM_ SG_ 1329 HCU_Sailmode_531h "模式切换
新增紧急浮水
0x0:Convenmod
0x1:SalWadeSts  浅涉水
0x2:DpWadeSts 深涉水（保留）
0x3:SailingFunc  航行
0x4:UpbeachSts  上滩
0x5:WaitfinspSts 待检（保留）
0x6:EmerfloatingSts 应急浮水（新增）
0x7:Reserved2";
CM_ SG_ 1330 DWD_WorkSts "涉水雷达工作状态";
CM_ SG_ 1330 RSensorFailSts "右探头工作状态";
CM_ SG_ 1330 DWD_Distance "报警距离分段";
CM_ SG_ 1360 ICC_XDriveMode "ICC通过视频流发给VCU进行驾驶模式设置
0x0:Not Active
0x1:无法判断 unidentifiable
0x2:普通1 Normal
0x3:雪地1 SNOW
0x4:泥地1 MUD
0x5:岩石1 ROCK
0x6:沙地1 SAND
0x7:水面1 WATER SURFACE
0x8：普通2 Normal
0x9:雪地2 SNOW
0xA:泥地2 MUD
0xB: 岩石2 ROCK
0xC:沙地2 SAND
0xD:水面2 WATER SURFACE
0xE:普通3 Normal
0xF:雪地3 SNOW
0x10:泥地3 MUD
0x11:岩石3 ROCK
0x12:沙地3 SAND";
CM_ SG_ 1417 HCU_RangCnsDispElecThisTrip_589h "本次行程消耗的纯电续航";
CM_ SG_ 1417 HCU_RangCnsDispThisTrip_589h "本次行程消耗续航";
CM_ SG_ 1417 HCU_RealMileagThisTrip_589h "本次行程实际里程数";
CM_ SG_ 1417 HCU_ElecCnsAvgThisTrip_589h "本次行程平均电耗";
CM_ SG_ 1417 HCU_RangCnsDispHybThisTrip_589h "本次行程消耗的燃油续航";
CM_ SG_ 1417 HCU_RealMileagElecThisTrip_589h "本次行程纯电行驶里程";
CM_ SG_ 1417 HCU_TimeHvRdyThisTrip_589h "本次行程用车时长";
CM_ SG_ 1417 HCU_ACRangCnsThisTrip_589h "本次行程空调导致里程衰减";
CM_ SG_ 1417 HCU_AuxRangCnsThisTrip_589h "本次行程电器额外消耗导致里程衰减";
CM_ SG_ 1417 HCU_RealMileagHybThisTrip_589h "本次行程混动行驶里程";
CM_ SG_ 1417 HCU_RangCnsDispElecAfRst_589h "自小计里程重置后在标准工况下消耗的纯电续航";
CM_ SG_ 1417 HCU_RgnRangBiasThisTrip_589h "本次行程里程偏差（上下坡、环境温度、驾驶风格等）";
CM_ SG_ 1417 HCU_RangCnsDispAfChrg_589h "自补能后消耗的续航";
CM_ SG_ 1417 HCU_RealMileagAfChrg_589h "自补能后实际里程数";
CM_ SG_ 1417 HCU_RangCnsDispElecAfChrg_589h "自补能后消耗的纯电续航";
CM_ SG_ 1417 HCU_RangCnsDispHybThisAfCh_589h "自补能后消耗的燃油续航";
CM_ SG_ 1417 HCU_FuelCnsAvgAfChrg_589h "自补能后平均油耗";
CM_ SG_ 1417 HCU_ElecCnsAvgAfChrg_589h "自补能后平均电耗";
CM_ SG_ 1417 HCU_TimeHvRdyAfChrg_589h "自补能后用车时长";
CM_ SG_ 1417 HCU_ACRangCnsAfChrg_589h "自补能后空调导致里程衰减";
CM_ SG_ 1417 HCU_FuelCnsAvgThisTrip_589h "本次行程平均油耗";
CM_ SG_ 1417 HCU_RealMileagElecAfChrg_589h "自补能后纯电行驶里程";
CM_ SG_ 1417 HCU_AuxRangCnsAfChrg_589h "自补能后电器额外消耗导致里程衰减";
CM_ SG_ 1417 HCU_RgnRangBiasAfChrg_589h "自补能后里程偏差（上下坡，环境温度，驾驶风格等）";
CM_ SG_ 1417 HCU_RangCnsDispAfRst_589h "自小计里程重置后消耗续航";
CM_ SG_ 1417 HCU_RealMileagAfRst_589h "自小计里程重置后实际里程数";
CM_ SG_ 1417 HCU_RealMileagHybAfChrg_589h "自补能后混动行驶里程";
CM_ SG_ 1417 HCU_FuelCnsAvgAfRst_589h "自小计里程重置后平均油耗";
CM_ SG_ 1417 HCU_ElecCnsAvgAfRst_589h "自小计里程重置后平均电耗";
CM_ SG_ 1417 HCU_TimeHvRdyAfRst_589h "自小计里程重置后用车时长";
CM_ SG_ 1417 HCU_ACRangCnsAfRst_589h "自小计里程重置后空调导致里程衰减";
CM_ SG_ 1417 HCU_RangCnsDispHybThisAfRst_589h "自小计里程重置后在标准工况下消耗的燃油续航";
CM_ SG_ 1417 HCU_AuxRangCnsAfRst_589h "自小计里程重置后电器额外消耗导致里程衰减";
CM_ SG_ 1417 HCU_RgnRangBiasAfRst_589h "自小计里程重置后里程偏差（上下坡、环境温度、驾驶风格等）";
CM_ SG_ 1417 HCU_stCleverDisReason_589h "智慧能量管理切换失败原因
0x0:No_Command
0x1:请退出越野驾驶模式
0x2:请退出cco模式
0x3:请退出ads模式
0x4:请退出节能模式
0x5:请退出晕车舒缓模式
0x6:请退出被拖模式
0x7:请退出拖挂模式";
CM_ SG_ 1417 HCU_RealMileagElecAfRst_589h "自小计里程重置后纯电行驶里程";
CM_ SG_ 1417 HCU_RealMileagHybAfRst_589h "自小计里程重置后混动行驶里程";
CM_ SG_ 1419 TotalOdometer_km_TRIPOBD_58Bh "自启动后累计里程";
CM_ SG_ 1432 HCU_TotalFaultNum "当前故障总数";
CM_ SG_ 1432 HCU_FrameIndex "帧序号";
CM_ SG_ 1432 HCU_SupplierNum "供应商代码";
CM_ SG_ 1432 HCU_FaultNum1 "故障列表1";
CM_ SG_ 1432 HCU_FaultNum2 "故障列表2";
CM_ SG_ 1432 HCU_FaultNum3 "故障列表3";
CM_ SG_ 1432 HCU_FaultNum4 "故障列表4";
CM_ SG_ 1432 HCU_FaultNum5 "故障列表5";
CM_ SG_ 1432 HCU_FaultNum6 "故障列表6";
CM_ SG_ 1432 HCU_FaultNum7 "故障列表7";
CM_ SG_ 1432 HCU_FaultNum8 "故障列表8";
CM_ SG_ 1432 HCU_FaultNum9 "故障列表9";
CM_ SG_ 1432 HCU_FaultNum10 "故障列表10";
CM_ SG_ 1432 HCU_FaultNum11 "故障列表11";
CM_ SG_ 1432 HCU_FaultNum12 "故障列表12";
CM_ SG_ 1432 HCU_FaultNum13 "故障列表13";
CM_ SG_ 1432 HCU_FaultNum14 "故障列表14";
CM_ SG_ 1432 HCU_FaultNum15 "故障列表15";
CM_ SG_ 1432 HCU_FaultNum16 "故障列表16";
CM_ SG_ 1432 HCU_FaultNum17 "故障列表17";
CM_ SG_ 1432 HCU_FaultNum18 "故障列表18";
CM_ SG_ 1432 HCU_FaultNum19 "故障列表19";
CM_ SG_ 1432 HCU_FaultNum20 "故障列表20";
CM_ SG_ 1445 HCU_SumFuCnsThisTrip "自启动后百公里油耗显示(仅仪表使用)";
CM_ SG_ 1445 HCU_SumElecCnsThisTrip "自启动后百公里电耗显示(仅仪表使用)";
CM_ SG_ 1445 HCU_SumEgyCnsThisTrip "自启动后百公里能耗L/100km";
CM_ SG_ 1445 TotalOdometer_km_virtual_5A5h "电池耐久法规（GTR 22）新增仪表接收总虚拟里程";
CM_ SG_ 1453 ICC_BedStatus "大床模式开关请求
0x1:居家大床
0x2:副驾单人床
0x3:驻车沙发
0x4:旅行小床
0x5:暂停";
CM_ SG_ 1582 RMR_RMCU "If set to 1 to force the network management of all other nodes on the bus into the re-peat message state.";
CM_ SG_ 1582 RMCU_Wakeup_Poweron "KL15 ON";
CM_ SG_ 1582 RMCU_Wakeup_NM "NM报文";
CM_ SG_ 1582 RMCU_Wakeup_Diag "Wakeup Source3 Reserved";
CM_ SG_ 1582 RMCU_Awake_Poweron "KL15 ON";
CM_ SG_ 1582 RMCU_Awake_NM "Awake Reason2 Reserved";
CM_ SG_ 1582 RMCU_Awake_Diag "接收到本部件相关的诊断报文";
CM_ SG_ 1582 RMCU_Awake_Discharge "放电中且放电未超时";
CM_ SG_ 1582 RMCU_Awake_HVON "整车处于高压状态";
BA_DEF_ SG_ "ASIL" ENUM "QM","A","B","C","D";
BA_DEF_ SG_ "E2EDataLength" INT 0 65535;
BA_DEF_ SG_ "GenSigInactiveValue" HEX 0 80000000;
BA_DEF_ SG_ "GenSigInvalidValue" HEX 0 281474976710655;
BA_DEF_ SG_ "GenSigStartValue" HEX 0 80000000;
BA_DEF_ SG_ "GenSigSendType" ENUM "Cyclic","OnWrite","OnWriteWithRepetition","OnChange","OnChangeWithRepetition","IfActive","IfActiveWithRepetition","NoSigSendType";
BA_DEF_ BO_ "CANFD_BRS" ENUM "0","1";
BA_DEF_ BO_ "DiagUudtResponse" ENUM "True","False";
BA_DEF_ BO_ "GRC_History" STRING ;
BA_DEF_ BO_ "GenMsgCycleTime" INT 0 65535;
BA_DEF_ BO_ "GenMsgCycleTimeFast" INT 0 65535;
BA_DEF_ BO_ "GenMsgDelayTime" INT 0 65535;
BA_DEF_ BO_ "GenMsgILSupport" ENUM "No","Yes";
BA_DEF_ BO_ "GenMsgNrOfRepetition" INT 0 255;
BA_DEF_ BO_ "GenMsgSendType" ENUM "Cyclic","Event","IfActive","CE","CA","NoMsgSendType";
BA_DEF_ BO_ "GenMsgStartDelayTime" INT 0 65535;
BA_DEF_ BO_ "MsgType" ENUM "IL","NM","DIAG","APPL";
BA_DEF_ BO_ "Msg_ASIL" ENUM "vector_leerstring","QM","A","B","C","D";
BA_DEF_ BO_ "NmAsrMessage" ENUM "No","Yes";
BA_DEF_ BO_ "NmMessage" ENUM "No","Yes";
BA_DEF_ BO_ "SCP_AuthInfoTxLength" INT 9 512;
BA_DEF_ BO_ "SCP_FreshnessValueLength" INT 0 512;
BA_DEF_ BO_ "SCP_FreshnessValueTxLength" INT 0 512;
BA_DEF_ BO_ "VFrameFormat" ENUM "StandardCAN","ExtendedCAN","reserved","J1939PG","reserved","reserved","reserved","reserved","reserved","reserved","reserved","reserved","reserved","reserved","StandardCAN_FD","ExtendedCAN_FD";
BA_DEF_DEF_ "ASIL" "QM";
BA_DEF_DEF_ "E2EDataLength" 64;
BA_DEF_DEF_ "GenSigInactiveValue" 0;
BA_DEF_DEF_ "GenSigInvalidValue" 0;
BA_DEF_DEF_ "GenSigStartValue" 0;
BA_DEF_DEF_ "GenSigSendType" "NoSigSendType";
BA_DEF_DEF_ "CANFD_BRS" "1";
BA_DEF_DEF_ "DiagUudtResponse" "True";
BA_DEF_DEF_ "GRC_History" "";
BA_DEF_DEF_ "GenMsgCycleTime" 0;
BA_DEF_DEF_ "GenMsgCycleTimeFast" 0;
BA_DEF_DEF_ "GenMsgDelayTime" 0;
BA_DEF_DEF_ "GenMsgILSupport" "Yes";
BA_DEF_DEF_ "GenMsgNrOfRepetition" 0;
BA_DEF_DEF_ "GenMsgSendType" "Cyclic";
BA_DEF_DEF_ "GenMsgStartDelayTime" 0;
BA_DEF_DEF_ "MsgType" "IL";
BA_DEF_DEF_ "Msg_ASIL" "vector_leerstring";
BA_DEF_DEF_ "NmAsrMessage" "No";
BA_DEF_DEF_ "NmMessage" "No";
BA_DEF_DEF_ "SCP_AuthInfoTxLength" 28;
BA_DEF_DEF_ "SCP_FreshnessValueLength" 48;
BA_DEF_DEF_ "SCP_FreshnessValueTxLength" 4;
BA_DEF_DEF_ "VFrameFormat" "J1939PG";
BA_ "GenMsgCycleTime" BO_ 1170 100;
BA_ "VFrameFormat" BO_ 1170 14;
BA_ "GenMsgCycleTime" BO_ 1172 100;
BA_ "VFrameFormat" BO_ 1172 14;
BA_ "GenMsgNrOfRepetition" BO_ 1174 3;
BA_ "GenMsgCycleTime" BO_ 1174 100;
BA_ "GenMsgDelayTime" BO_ 1174 5;
BA_ "GenMsgCycleTimeFast" BO_ 1174 50;
BA_ "GenMsgSendType" BO_ 1174 3;
BA_ "VFrameFormat" BO_ 1174 14;
BA_ "GenMsgCycleTime" BO_ 1181 100;
BA_ "VFrameFormat" BO_ 1181 14;
BA_ "GenMsgCycleTime" BO_ 1182 100;
BA_ "VFrameFormat" BO_ 1182 14;
BA_ "GenMsgCycleTime" BO_ 1184 100;
BA_ "VFrameFormat" BO_ 1184 14;
BA_ "GenMsgNrOfRepetition" BO_ 1195 5;
BA_ "GenMsgCycleTime" BO_ 1195 100;
BA_ "GenMsgDelayTime" BO_ 1195 5;
BA_ "GenMsgCycleTimeFast" BO_ 1195 100;
BA_ "GenMsgSendType" BO_ 1195 3;
BA_ "VFrameFormat" BO_ 1195 14;
BA_ "GenMsgCycleTime" BO_ 1199 100;
BA_ "VFrameFormat" BO_ 1199 14;
BA_ "GenMsgCycleTime" BO_ 1200 100;
BA_ "VFrameFormat" BO_ 1200 14;
BA_ "GenMsgCycleTime" BO_ 1204 100;
BA_ "VFrameFormat" BO_ 1204 14;
BA_ "GenMsgCycleTime" BO_ 1207 100;
BA_ "VFrameFormat" BO_ 1207 14;
BA_ "GenMsgCycleTime" BO_ 1209 100;
BA_ "VFrameFormat" BO_ 1209 14;
BA_ "GenMsgCycleTime" BO_ 1217 100;
BA_ "VFrameFormat" BO_ 1217 14;
BA_ "GenMsgCycleTime" BO_ 1219 100;
BA_ "VFrameFormat" BO_ 1219 14;
BA_ "GenMsgCycleTime" BO_ 1224 100;
BA_ "VFrameFormat" BO_ 1224 14;
BA_ "GenMsgNrOfRepetition" BO_ 1231 3;
BA_ "GenMsgCycleTime" BO_ 1231 100;
BA_ "GenMsgDelayTime" BO_ 1231 5;
BA_ "GenMsgCycleTimeFast" BO_ 1231 100;
BA_ "GenMsgSendType" BO_ 1231 3;
BA_ "VFrameFormat" BO_ 1231 14;
BA_ "GenMsgNrOfRepetition" BO_ 1239 3;
BA_ "GenMsgCycleTime" BO_ 1239 100;
BA_ "GenMsgDelayTime" BO_ 1239 5;
BA_ "GenMsgCycleTimeFast" BO_ 1239 50;
BA_ "GenMsgSendType" BO_ 1239 3;
BA_ "VFrameFormat" BO_ 1239 14;
BA_ "GenMsgNrOfRepetition" BO_ 1246 3;
BA_ "GenMsgCycleTime" BO_ 1246 100;
BA_ "GenMsgDelayTime" BO_ 1246 5;
BA_ "GenMsgCycleTimeFast" BO_ 1246 50;
BA_ "GenMsgSendType" BO_ 1246 3;
BA_ "VFrameFormat" BO_ 1246 14;
BA_ "GenMsgNrOfRepetition" BO_ 1248 5;
BA_ "GenMsgCycleTime" BO_ 1248 100;
BA_ "GenMsgDelayTime" BO_ 1248 5;
BA_ "GenMsgCycleTimeFast" BO_ 1248 10;
BA_ "GenMsgSendType" BO_ 1248 3;
BA_ "VFrameFormat" BO_ 1248 14;
BA_ "GenMsgNrOfRepetition" BO_ 1250 3;
BA_ "GenMsgCycleTime" BO_ 1250 100;
BA_ "GenMsgDelayTime" BO_ 1250 5;
BA_ "GenMsgCycleTimeFast" BO_ 1250 50;
BA_ "GenMsgSendType" BO_ 1250 3;
BA_ "VFrameFormat" BO_ 1250 14;
BA_ "GenMsgCycleTime" BO_ 1252 100;
BA_ "VFrameFormat" BO_ 1252 14;
BA_ "GenMsgNrOfRepetition" BO_ 1265 3;
BA_ "GenMsgCycleTime" BO_ 1265 100;
BA_ "GenMsgDelayTime" BO_ 1265 5;
BA_ "GenMsgCycleTimeFast" BO_ 1265 100;
BA_ "GenMsgSendType" BO_ 1265 3;
BA_ "VFrameFormat" BO_ 1265 14;
BA_ "GenMsgCycleTime" BO_ 1268 500;
BA_ "VFrameFormat" BO_ 1268 14;
BA_ "GenMsgCycleTime" BO_ 1288 500;
BA_ "VFrameFormat" BO_ 1288 14;
BA_ "GenMsgCycleTime" BO_ 1290 500;
BA_ "VFrameFormat" BO_ 1290 14;
BA_ "GenMsgCycleTime" BO_ 1291 500;
BA_ "VFrameFormat" BO_ 1291 14;
BA_ "GenMsgCycleTime" BO_ 1296 500;
BA_ "VFrameFormat" BO_ 1296 14;
BA_ "GenMsgCycleTime" BO_ 1298 500;
BA_ "VFrameFormat" BO_ 1298 14;
BA_ "GenMsgCycleTime" BO_ 1314 100;
BA_ "VFrameFormat" BO_ 1314 14;
BA_ "GenMsgCycleTime" BO_ 1316 500;
BA_ "VFrameFormat" BO_ 1316 14;
BA_ "GenMsgCycleTime" BO_ 1324 500;
BA_ "VFrameFormat" BO_ 1324 14;
BA_ "GenMsgCycleTime" BO_ 1329 100;
BA_ "VFrameFormat" BO_ 1329 14;
BA_ "GenMsgCycleTime" BO_ 1330 100;
BA_ "VFrameFormat" BO_ 1330 14;
BA_ "GenMsgNrOfRepetition" BO_ 1360 3;
BA_ "GenMsgCycleTime" BO_ 1360 100;
BA_ "GenMsgDelayTime" BO_ 1360 5;
BA_ "GenMsgCycleTimeFast" BO_ 1360 100;
BA_ "GenMsgSendType" BO_ 1360 3;
BA_ "VFrameFormat" BO_ 1360 14;
BA_ "GenMsgCycleTime" BO_ 1417 1000;
BA_ "VFrameFormat" BO_ 1417 14;
BA_ "GenMsgCycleTime" BO_ 1419 1000;
BA_ "VFrameFormat" BO_ 1419 14;
BA_ "GenMsgCycleTime" BO_ 1432 500;
BA_ "GRC_History" BO_ 1432 "[{'approvedBy':'贾少辉','author':'于俊','changesComments':'1、HCU新增故障报文HCU_RemoteDiag；\n[能源管理部-王新欢]','date':'2026/3/12','ecu':'HCU_RemoteDiag(0x598)','ecuName':'RXCU,\nPDCS1,\nPDCS2,\nCGW','reviewedBy':'杨华','revision':'V2.0'}]";
BA_ "VFrameFormat" BO_ 1432 14;
BA_ "GenMsgCycleTime" BO_ 1445 1000;
BA_ "VFrameFormat" BO_ 1445 14;
BA_ "GenMsgCycleTime" BO_ 1453 500;
BA_ "VFrameFormat" BO_ 1453 14;
BA_ "GenMsgCycleTime" BO_ 1508 2000;
BA_ "VFrameFormat" BO_ 1508 14;
BA_ "GenMsgCycleTime" BO_ 1582 1000;
BA_ "NmMessage" BO_ 1582 1;
BA_ "DiagUudtResponse" BO_ 1582 1;
BA_ "MsgType" BO_ 1582 1;
BA_ "NmAsrMessage" BO_ 1582 1;
BA_ "GenMsgILSupport" BO_ 1582 0;
BA_ "VFrameFormat" BO_ 1582 0;
BA_ "GenSigInvalidValue" SG_ 1170 HVHRu 255;
BA_ "GenSigSendType" SG_ 1170 HVHRu 0;
BA_ "GenSigInvalidValue" SG_ 1170 HVHRi 255;
BA_ "GenSigSendType" SG_ 1170 HVHRi 0;
BA_ "GenSigInvalidValue" SG_ 1170 HVHR_Sts 7;
BA_ "GenSigSendType" SG_ 1170 HVHR_Sts 0;
BA_ "GenSigInvalidValue" SG_ 1172 ExternalTemperature_C 254;
BA_ "GenSigStartValue" SG_ 1172 ExternalTemperature_C 254;
BA_ "GenSigSendType" SG_ 1172 ExternalTemperature_C 0;
BA_ "GenSigStartValue" SG_ 1172 CirculationModeDisplaySts 1;
BA_ "GenSigSendType" SG_ 1172 CirculationModeDisplaySts 0;
BA_ "GenSigSendType" SG_ 1174 ICC_SetChrgnFctMem 2;
BA_ "GenSigSendType" SG_ 1174 CTP_PowerModeSet 2;
BA_ "GenSigSendType" SG_ 1174 ICC_EmissionMode 0;
BA_ "GenSigSendType" SG_ 1174 IHU_SetSOC 2;
BA_ "GenSigSendType" SG_ 1181 FLZCU_AlcoholLockInputSts 0;
BA_ "GenSigSendType" SG_ 1182 CDU_OBC_3_CRC1 0;
BA_ "GenSigSendType" SG_ 1182 CDU_OBC_3_RollgCntr1 0;
BA_ "GenSigSendType" SG_ 1182 CDU_OBC_3_Resd1 0;
BA_ "GenSigInvalidValue" SG_ 1182 OBC_ChgCurr 65535;
BA_ "GenSigSendType" SG_ 1182 OBC_ChgCurr 0;
BA_ "GenSigInvalidValue" SG_ 1182 OBC_ChgVolt 65535;
BA_ "GenSigSendType" SG_ 1182 OBC_ChgVolt 0;
BA_ "GenSigInvalidValue" SG_ 1182 OBC_MaxOutputPower 255;
BA_ "GenSigSendType" SG_ 1182 OBC_MaxOutputPower 0;
BA_ "GenSigSendType" SG_ 1182 OBC_FaultCode 0;
BA_ "GenSigSendType" SG_ 1182 CDU_OBC_3_CRC2 0;
BA_ "GenSigSendType" SG_ 1182 CDU_OBC_3_RollgCntr2 0;
BA_ "GenSigSendType" SG_ 1182 CDU_OBC_3_Resd2 0;
BA_ "GenSigInvalidValue" SG_ 1182 OBC_MaxDisOutPower 255;
BA_ "GenSigSendType" SG_ 1182 OBC_MaxDisOutPower 0;
BA_ "GenSigInvalidValue" SG_ 1182 OBC_CPMaxVolt 255;
BA_ "GenSigSendType" SG_ 1182 OBC_CPMaxVolt 0;
BA_ "GenSigSendType" SG_ 1182 CDU_OBC_3_CRC3 0;
BA_ "GenSigSendType" SG_ 1182 CDU_OBC_3_RollgCntr3 0;
BA_ "GenSigSendType" SG_ 1182 CDU_OBC_3_Resd3 0;
BA_ "GenSigSendType" SG_ 1182 OBC_ChrgrInputCurr1 0;
BA_ "GenSigSendType" SG_ 1182 OBC_ChrgrInputCurr2 0;
BA_ "GenSigSendType" SG_ 1182 OBC_ChrgrInputCurr3 0;
BA_ "GenSigSendType" SG_ 1182 OBC_S2Swtsts 0;
BA_ "GenSigSendType" SG_ 1182 OBC_ChrgrInputVolt1 0;
BA_ "GenSigSendType" SG_ 1182 CDU_OBC_3_CRC4 0;
BA_ "GenSigSendType" SG_ 1182 CDU_OBC_3_RollgCntr4 0;
BA_ "GenSigSendType" SG_ 1182 CDU_OBC_3_Resd4 0;
BA_ "GenSigSendType" SG_ 1182 OBC_ChrgrInputVolt2 0;
BA_ "GenSigSendType" SG_ 1182 OBC_ChrgrInputVolt3 0;
BA_ "GenSigSendType" SG_ 1182 OBC_FaultLevelSts 0;
BA_ "GenSigSendType" SG_ 1182 OBC_ElectronicLockSts 0;
BA_ "GenSigSendType" SG_ 1182 OBC_WorkingMode 0;
BA_ "GenSigSendType" SG_ 1182 OBC_Worksts 0;
BA_ "GenSigSendType" SG_ 1182 OBC_CPLineSts 0;
BA_ "GenSigSendType" SG_ 1182 CDU_OBC_3_CRC5 0;
BA_ "GenSigSendType" SG_ 1182 CDU_OBC_3_RollgCntr5 0;
BA_ "GenSigSendType" SG_ 1182 CDU_OBC_3_Resd5 0;
BA_ "GenSigSendType" SG_ 1182 OBC_CCResisdent 0;
BA_ "GenSigSendType" SG_ 1182 OBC_HV_OutputUnderVolt 0;
BA_ "GenSigSendType" SG_ 1182 OBC_HV_OutputOverVolt 0;
BA_ "GenSigSendType" SG_ 1182 OBC_HV_OutputShortCircuit 0;
BA_ "GenSigSendType" SG_ 1182 OBC_InputUnderVolt 0;
BA_ "GenSigSendType" SG_ 1182 OBC_InputOverVolt 0;
BA_ "GenSigSendType" SG_ 1182 OBC_HighCurrOutputFault 0;
BA_ "GenSigSendType" SG_ 1182 OBC_CAN_Fault 0;
BA_ "GenSigSendType" SG_ 1182 OBC_KL30_UnderVolt 0;
BA_ "GenSigInvalidValue" SG_ 1182 OBC_MaxInnerAc220VOutPower 255;
BA_ "GenSigSendType" SG_ 1182 OBC_MaxInnerAc220VOutPower 0;
BA_ "GenSigInvalidValue" SG_ 1182 OBC_ActInnerAc220VOutPower 255;
BA_ "GenSigSendType" SG_ 1182 OBC_ActInnerAc220VOutPower 0;
BA_ "GenSigSendType" SG_ 1182 CDU_OBC_3_CRC6 0;
BA_ "GenSigSendType" SG_ 1182 CDU_OBC_3_RollgCntr6 0;
BA_ "GenSigSendType" SG_ 1182 CDU_OBC_3_Resd6 0;
BA_ "GenSigInvalidValue" SG_ 1182 OBC_InnerDischgCurr 1023;
BA_ "GenSigSendType" SG_ 1182 OBC_InnerDischgCurr 0;
BA_ "GenSigInvalidValue" SG_ 1182 OBC_InnerDischgVolt 8191;
BA_ "GenSigSendType" SG_ 1182 OBC_InnerDischgVolt 0;
BA_ "GenSigInvalidValue" SG_ 1182 OBC_OutDischgCurr 1023;
BA_ "GenSigSendType" SG_ 1182 OBC_OutDischgCurr 0;
BA_ "GenSigInvalidValue" SG_ 1182 OBC_OutDischgVolt 8191;
BA_ "GenSigSendType" SG_ 1182 OBC_OutDischgVolt 0;
BA_ "GenSigSendType" SG_ 1184 TDU_1_EAC_Sts 0;
BA_ "GenSigInvalidValue" SG_ 1184 EAC_u 255;
BA_ "GenSigStartValue" SG_ 1184 EAC_u 255;
BA_ "GenSigSendType" SG_ 1184 EAC_u 0;
BA_ "GenSigInvalidValue" SG_ 1184 EAC_i 255;
BA_ "GenSigStartValue" SG_ 1184 EAC_i 255;
BA_ "GenSigSendType" SG_ 1184 EAC_i 0;
BA_ "GenSigInvalidValue" SG_ 1184 HVHu 255;
BA_ "GenSigSendType" SG_ 1184 HVHu 0;
BA_ "GenSigInvalidValue" SG_ 1184 HVHi 255;
BA_ "GenSigSendType" SG_ 1184 HVHi 0;
BA_ "GenSigInvalidValue" SG_ 1184 HVH_Sts 7;
BA_ "GenSigSendType" SG_ 1184 HVH_Sts 0;
BA_ "GenSigSendType" SG_ 1195 BNCM_8_HV_Req 4;
BA_ "ASIL" SG_ 1199 TCM_1_TrailerSts 2;
BA_ "GenSigSendType" SG_ 1199 TCM_1_TrailerSts 0;
BA_ "GenSigInvalidValue" SG_ 1200 SOC 255;
BA_ "GenSigStartValue" SG_ 1200 SOC 255;
BA_ "GenSigSendType" SG_ 1200 SOC 0;
BA_ "GenSigInvalidValue" SG_ 1200 SOH_SUL 255;
BA_ "GenSigStartValue" SG_ 1200 SOH_SUL 100;
BA_ "GenSigSendType" SG_ 1200 SOH_SUL 0;
BA_ "GenSigInvalidValue" SG_ 1200 SOFV_StopEnable 255;
BA_ "GenSigStartValue" SG_ 1200 SOFV_StopEnable 254;
BA_ "GenSigSendType" SG_ 1200 SOFV_StopEnable 0;
BA_ "GenSigInvalidValue" SG_ 1200 SOFV_Restart 255;
BA_ "GenSigStartValue" SG_ 1200 SOFV_Restart 254;
BA_ "GenSigSendType" SG_ 1200 SOFV_Restart 0;
BA_ "GenSigStartValue" SG_ 1200 SOH_LAM 255;
BA_ "GenSigSendType" SG_ 1200 SOH_LAM 0;
BA_ "GenSigStartValue" SG_ 1200 SOH_COR 255;
BA_ "GenSigSendType" SG_ 1200 SOH_COR 0;
BA_ "GenSigStartValue" SG_ 1200 reserved 3;
BA_ "GenSigSendType" SG_ 1200 reserved 0;
BA_ "GenSigInvalidValue" SG_ 1200 SOC_STATE 3;
BA_ "GenSigStartValue" SG_ 1200 SOC_STATE 3;
BA_ "GenSigSendType" SG_ 1200 SOC_STATE 0;
BA_ "GenSigInvalidValue" SG_ 1200 SOH_SUL_STATE 3;
BA_ "GenSigStartValue" SG_ 1200 SOH_SUL_STATE 3;
BA_ "GenSigSendType" SG_ 1200 SOH_SUL_STATE 0;
BA_ "GenSigInvalidValue" SG_ 1200 SOFV_StopEnable_STATE 3;
BA_ "GenSigStartValue" SG_ 1200 SOFV_StopEnable_STATE 3;
BA_ "GenSigSendType" SG_ 1200 SOFV_StopEnable_STATE 0;
BA_ "GenSigInvalidValue" SG_ 1200 SOFV_Restart_STATE 3;
BA_ "GenSigStartValue" SG_ 1200 SOFV_Restart_STATE 3;
BA_ "GenSigSendType" SG_ 1200 SOFV_Restart_STATE 0;
BA_ "GenSigSendType" SG_ 1204 VCU_1_G_CRC 0;
BA_ "GenSigSendType" SG_ 1204 VCU_1_G_RollgCntr 0;
BA_ "GenSigSendType" SG_ 1204 VCU_AcceleratorPosRawIVD 0;
BA_ "GenSigStartValue" SG_ 1204 VCU_1_G_Pwr 500;
BA_ "GenSigSendType" SG_ 1204 VCU_1_G_Pwr 0;
BA_ "ASIL" SG_ 1204 VCU_1_G_AcceleratorPosRaw 2;
BA_ "GenSigSendType" SG_ 1204 VCU_1_G_AcceleratorPosRaw 0;
BA_ "ASIL" SG_ 1204 VCU_1_G_PTReady 2;
BA_ "GenSigSendType" SG_ 1204 VCU_1_G_PTReady 0;
BA_ "GenSigStartValue" SG_ 1204 VCU_1_G_DriveMode 6;
BA_ "ASIL" SG_ 1204 VCU_1_G_DriveMode 2;
BA_ "GenSigSendType" SG_ 1204 VCU_1_G_DriveMode 0;
BA_ "GenSigSendType" SG_ 1204 VCU_1_G_BookChrgSetResponse 0;
BA_ "GenSigSendType" SG_ 1204 VCU_1_G_HvBattKeepWarmSts 0;
BA_ "GenSigSendType" SG_ 1204 VCU_1_G_HvBattKeepWarmActiveReq 0;
BA_ "GenSigInvalidValue" SG_ 1204 VCU_1_G_HundECAver 511;
BA_ "GenSigSendType" SG_ 1204 VCU_1_G_HundECAver 0;
BA_ "GenSigSendType" SG_ 1204 VCU_1_G_BookChrgSetStsFb 0;
BA_ "GenSigSendType" SG_ 1204 VCU_1_G_EgyRegenLevel 0;
BA_ "ASIL" SG_ 1204 VCU_1_G_PRNDGearAct 2;
BA_ "GenSigSendType" SG_ 1204 VCU_1_G_PRNDGearAct 0;
BA_ "GenSigInvalidValue" SG_ 1207 EAC_i_400V 511;
BA_ "GenSigSendType" SG_ 1207 EAC_i_400V 0;
BA_ "GenSigInvalidValue" SG_ 1207 HVH_Sts_400V 7;
BA_ "GenSigStartValue" SG_ 1207 HVH_Sts_400V 7;
BA_ "GenSigSendType" SG_ 1207 HVH_Sts_400V 0;
BA_ "GenSigInvalidValue" SG_ 1207 HVH_U_400V 255;
BA_ "GenSigSendType" SG_ 1207 HVH_U_400V 0;
BA_ "GenSigSendType" SG_ 1207 Flag_400V_800V 0;
BA_ "GenSigSendType" SG_ 1209 VCU_2_G_CRC 0;
BA_ "GenSigSendType" SG_ 1209 VCU_2_G_RollgCntr 0;
BA_ "GenSigSendType" SG_ 1209 VCU_2_G_Resd 0;
BA_ "GenSigInvalidValue" SG_ 1209 VCU_2_G_GasPedalPosInvalidData 1;
BA_ "ASIL" SG_ 1209 VCU_2_G_GasPedalPosInvalidData 2;
BA_ "GenSigSendType" SG_ 1209 VCU_2_G_GasPedalPosInvalidData 0;
BA_ "ASIL" SG_ 1209 VCU_2_G_PowerLimit 2;
BA_ "GenSigSendType" SG_ 1209 VCU_2_G_PowerLimit 0;
BA_ "GenSigSendType" SG_ 1209 VCU_2_G_BrakeLightReq 0;
BA_ "ASIL" SG_ 1209 VCU_2_G_VehicleSystemFailure 2;
BA_ "GenSigSendType" SG_ 1209 VCU_2_G_VehicleSystemFailure 0;
BA_ "GenSigSendType" SG_ 1209 OnekeyHVOffSuccess_4B9h 0;
BA_ "GenSigSendType" SG_ 1209 VCU_2_G_BootloadSts 0;
BA_ "GenSigSendType" SG_ 1209 VCU_2_G_DischgSts 0;
BA_ "GenSigSendType" SG_ 1209 VCU_2_G_BrakePedalStsValidData 0;
BA_ "GenSigSendType" SG_ 1209 VCU_2_G_ExhibitionMod 0;
BA_ "ASIL" SG_ 1209 VCU_2_G_BrakePedalSts 2;
BA_ "GenSigSendType" SG_ 1209 VCU_2_G_BrakePedalSts 0;
BA_ "GenSigSendType" SG_ 1209 VCU_2_G_DCDCEnable 0;
BA_ "ASIL" SG_ 1209 VCU_2_G_HVReady 2;
BA_ "GenSigSendType" SG_ 1209 VCU_2_G_HVReady 0;
BA_ "GenSigSendType" SG_ 1209 Res_VCU_2_G_Brake_state 0;
BA_ "GenSigSendType" SG_ 1209 VCU_2_G_VCUEnergyflow 0;
BA_ "GenSigInvalidValue" SG_ 1209 VCU_2_G_GasPedalPosition 1023;
BA_ "ASIL" SG_ 1209 VCU_2_G_GasPedalPosition 2;
BA_ "GenSigSendType" SG_ 1209 VCU_2_G_GasPedalPosition 0;
BA_ "GenSigSendType" SG_ 1209 VCU_2_G_DrvGearShiftFailureIndcn 0;
BA_ "GenSigSendType" SG_ 1209 VCU_2_G_OnekeyHVoffStyle 0;
BA_ "ASIL" SG_ 1217 ASU_ECASErrSts_4C1h 2;
BA_ "GenSigSendType" SG_ 1217 ASU_ECASErrSts_4C1h 0;
BA_ "ASIL" SG_ 1217 ASU_SuspTarLvl_4C1h 2;
BA_ "GenSigSendType" SG_ 1217 ASU_SuspTarLvl_4C1h 0;
BA_ "ASIL" SG_ 1217 ASU_CDCErrSts_4C1h 2;
BA_ "GenSigSendType" SG_ 1217 ASU_CDCErrSts_4C1h 0;
BA_ "ASIL" SG_ 1217 ASU_SuspDampingLvl_4C1h 2;
BA_ "GenSigSendType" SG_ 1217 ASU_SuspDampingLvl_4C1h 0;
BA_ "GenSigInvalidValue" SG_ 1219 VCU_CLMSystemPowerLimit 1023;
BA_ "GenSigSendType" SG_ 1219 VCU_CLMSystemPowerLimit 0;
BA_ "GenSigSendType" SG_ 1219 HCU_HVHRAllow 0;
BA_ "GenSigSendType" SG_ 1219 VCU_CLMEACAllow 0;
BA_ "GenSigSendType" SG_ 1219 VCU_CLMHVHAllow 0;
BA_ "GenSigSendType" SG_ 1219 VCU_CLMHVReady 0;
BA_ "GenSigSendType" SG_ 1219 VCU_PwtCoolingLvl 0;
BA_ "GenSigInvalidValue" SG_ 1224 BMS_Chg_Sts 15;
BA_ "GenSigSendType" SG_ 1224 BMS_Chg_Sts 0;
BA_ "GenSigSendType" SG_ 1231 TBOX_1_BookChrgActiveReq 0;
BA_ "GenSigSendType" SG_ 1231 TBOX_BookChrgSetReq 2;
BA_ "GenSigSendType" SG_ 1231 TBOX_StopChrgReq 2;
BA_ "GenSigSendType" SG_ 1231 TBOX_KeepWarmSet 0;
BA_ "GenSigSendType" SG_ 1231 TBOX_HV_Req 0;
BA_ "GenSigSendType" SG_ 1231 TBOX_BookChrgSts 0;
BA_ "GenSigInvalidValue" SG_ 1231 TBOX_ChgSOCSet_4CFh 255;
BA_ "GenSigSendType" SG_ 1231 TBOX_ChgSOCSet_4CFh 2;
BA_ "GenSigSendType" SG_ 1231 TBOX_HvBattKeepWarmActiveReq 2;
BA_ "GenSigSendType" SG_ 1231 TBOX_ChgSOCPrioritySts_4CFh 0;
BA_ "GenSigSendType" SG_ 1239 ICC_DisChg 2;
BA_ "GenSigInvalidValue" SG_ 1239 ICC_DisChgPercent 127;
BA_ "GenSigSendType" SG_ 1239 ICC_DisChgPercent 0;
BA_ "GenSigInvalidValue" SG_ 1239 ICC_ChgSocSet 255;
BA_ "GenSigStartValue" SG_ 1239 ICC_ChgSocSet 255;
BA_ "GenSigSendType" SG_ 1239 ICC_ChgSocSet 2;
BA_ "GenSigSendType" SG_ 1239 ICC_TowingMode 2;
BA_ "GenSigSendType" SG_ 1239 ICC_CampMode 2;
BA_ "GenSigSendType" SG_ 1239 ICC_StCleverMainReq_4D7h 2;
BA_ "GenSigSendType" SG_ 1239 ICC_StCleverRgnReq_4D7h 2;
BA_ "GenSigSendType" SG_ 1239 ICC_EnergySavingModeReq_4D7h 2;
BA_ "GenSigSendType" SG_ 1239 ICC_StCleverDrvReq_4D7h 2;
BA_ "GenSigSendType" SG_ 1239 ICC_FacCleverDrvActRst_4D7h 2;
BA_ "GenSigSendType" SG_ 1239 ICC_EngyVehSpdLi_4D7h 0;
BA_ "GenSigSendType" SG_ 1239 ICC_DischgSetSOC_4D7h 2;
BA_ "GenSigSendType" SG_ 1246 ICC_KeepWarm 0;
BA_ "GenSigSendType" SG_ 1248 FRZCU_RKEButtAct 0;
BA_ "GenSigSendType" SG_ 1250 ICC_1_OTAHV_Req 0;
BA_ "GenSigSendType" SG_ 1250 ICC_SteeringMode 2;
BA_ "GenSigSendType" SG_ 1250 ICC_SuspensionDamping 2;
BA_ "GenSigSendType" SG_ 1250 ICC_SuspensionHeight 2;
BA_ "GenSigSendType" SG_ 1250 ICC_SelfClearing 2;
BA_ "GenSigSendType" SG_ 1250 ICC_PetModeHV_Req 0;
BA_ "GenSigSendType" SG_ 1250 ICC_SentinelHV_Req 0;
BA_ "GenSigSendType" SG_ 1250 ICC_CCMReq_4E2h 2;
BA_ "GenSigSendType" SG_ 1250 ICC_TRIPSelfClearing_4E2h 2;
BA_ "GenSigInvalidValue" SG_ 1252 TotalOdometer_km_OBD 16777215;
BA_ "GenSigSendType" SG_ 1252 TotalOdometer_km_OBD 0;
BA_ "GenSigSendType" SG_ 1252 TotalOdometer_km_OBDValidData 0;
BA_ "GenSigSendType" SG_ 1265 ICC_CinemaStatus 0;
BA_ "GenSigSendType" SG_ 1268 CRC1_4F4h 0;
BA_ "GenSigSendType" SG_ 1268 RollgCntr1_4F4h 0;
BA_ "GenSigSendType" SG_ 1268 Resd1_4F4h 0;
BA_ "GenSigInvalidValue" SG_ 1268 SOCE_4F4h 1023;
BA_ "GenSigStartValue" SG_ 1268 SOCE_4F4h 1022;
BA_ "GenSigSendType" SG_ 1268 SOCE_4F4h 0;
BA_ "GenSigSendType" SG_ 1268 CRC2_4F4h 0;
BA_ "GenSigSendType" SG_ 1268 RollgCntr2_4F4h 0;
BA_ "GenSigSendType" SG_ 1268 Resd2_4F4h 0;
BA_ "GenSigInvalidValue" SG_ 1268 HvBattEgyTotal_4F4h 1048575;
BA_ "GenSigStartValue" SG_ 1268 HvBattEgyTotal_4F4h 1048574;
BA_ "GenSigSendType" SG_ 1268 HvBattEgyTotal_4F4h 0;
BA_ "GenSigInvalidValue" SG_ 1268 HvBattV2XTotal_4F4h 1048575;
BA_ "GenSigStartValue" SG_ 1268 HvBattV2XTotal_4F4h 1048574;
BA_ "GenSigSendType" SG_ 1268 HvBattV2XTotal_4F4h 0;
BA_ "GenSigSendType" SG_ 1268 CRC3_4F4h 0;
BA_ "GenSigSendType" SG_ 1268 RollgCntr3_4F4h 0;
BA_ "GenSigSendType" SG_ 1268 Resd3_4F4h 0;
BA_ "GenSigInvalidValue" SG_ 1268 HvBattNoDrivEgyTotal_4F4h 1048575;
BA_ "GenSigStartValue" SG_ 1268 HvBattNoDrivEgyTotal_4F4h 1048574;
BA_ "GenSigSendType" SG_ 1268 HvBattNoDrivEgyTotal_4F4h 0;
BA_ "GenSigSendType" SG_ 1288 CurrentTimeYear_508h 0;
BA_ "GenSigStartValue" SG_ 1288 CurrentTimeMonth_508h 1;
BA_ "GenSigSendType" SG_ 1288 CurrentTimeMonth_508h 0;
BA_ "GenSigStartValue" SG_ 1288 CurrentTimeDay_508h 1;
BA_ "GenSigSendType" SG_ 1288 CurrentTimeDay_508h 0;
BA_ "GenSigSendType" SG_ 1288 CurrentTimeHour_508h 0;
BA_ "GenSigSendType" SG_ 1288 CurrentTimeMinute_508h 0;
BA_ "GenSigSendType" SG_ 1288 CurrentTimeSecond_508h 0;
BA_ "GenSigSendType" SG_ 1288 TboxLocalTiValid 0;
BA_ "ASIL" SG_ 1290 BMS_HvBattCellUnderU 3;
BA_ "GenSigSendType" SG_ 1290 BMS_HvBattCellUnderU 0;
BA_ "ASIL" SG_ 1290 BMS_HvBattUnderU 3;
BA_ "GenSigSendType" SG_ 1290 BMS_HvBattUnderU 0;
BA_ "GenSigInvalidValue" SG_ 1291 BMS_SOCLight 127;
BA_ "ASIL" SG_ 1291 BMS_SOCLight 2;
BA_ "GenSigSendType" SG_ 1291 BMS_SOCLight 0;
BA_ "GenSigSendType" SG_ 1296 CurrentTimeYear 0;
BA_ "GenSigStartValue" SG_ 1296 CurrentTimeMonth 1;
BA_ "GenSigSendType" SG_ 1296 CurrentTimeMonth 0;
BA_ "GenSigStartValue" SG_ 1296 CurrentTimeDay 1;
BA_ "GenSigSendType" SG_ 1296 CurrentTimeDay 0;
BA_ "GenSigSendType" SG_ 1296 CurrentTimeHour 0;
BA_ "GenSigSendType" SG_ 1296 CurrentTimeMinute 0;
BA_ "GenSigSendType" SG_ 1296 CurrentTimeSecond 0;
BA_ "GenSigSendType" SG_ 1298 APTC_ErrorLevel 0;
BA_ "GenSigSendType" SG_ 1298 APTC_ErrorCode2 0;
BA_ "GenSigSendType" SG_ 1314 HCU_CRC1_522h 0;
BA_ "GenSigSendType" SG_ 1314 HCU_RollgCntr1_522h 0;
BA_ "GenSigSendType" SG_ 1314 HCU_Resd1_522h 0;
BA_ "GenSigSendType" SG_ 1314 HCU_V2lDisChgBck 0;
BA_ "GenSigSendType" SG_ 1314 HCU_DisChgMemFed 0;
BA_ "GenSigSendType" SG_ 1314 HCU_V2VDisChgBck 0;
BA_ "GenSigSendType" SG_ 1314 HCU_V2l_IntlDisChgBck 0;
BA_ "GenSigSendType" SG_ 1314 HCU_FuelDetnOpDefeated 0;
BA_ "GenSigInvalidValue" SG_ 1314 HCU_FuelDetnModSwtFed 3;
BA_ "GenSigSendType" SG_ 1314 HCU_FuelDetnModSwtFed 0;
BA_ "GenSigInvalidValue" SG_ 1314 HCU_FuelDetnStateFed 3;
BA_ "GenSigSendType" SG_ 1314 HCU_FuelDetnStateFed 0;
BA_ "GenSigInvalidValue" SG_ 1314 HCU_HVDownRepairModeFed 3;
BA_ "GenSigSendType" SG_ 1314 HCU_HVDownRepairModeFed 0;
BA_ "GenSigSendType" SG_ 1314 HCU_SumFuCns 0;
BA_ "GenSigInvalidValue" SG_ 1314 HCU_TrailerMode 3;
BA_ "GenSigSendType" SG_ 1314 HCU_TrailerMode 0;
BA_ "GenSigSendType" SG_ 1314 HCU_TABSwtFed_522h 0;
BA_ "GenSigSendType" SG_ 1314 HCU_MotSelfHeatLvlReq 0;
BA_ "GenSigSendType" SG_ 1314 HCU_MotSelfHeatEnReq 0;
BA_ "GenSigSendType" SG_ 1314 HCU_KeyDriveModememory 0;
BA_ "GenSigSendType" SG_ 1314 HCU_DrivePowerDispSetFed 0;
BA_ "GenSigSendType" SG_ 1314 HCU_TCMStsReq_522h 0;
BA_ "GenSigInvalidValue" SG_ 1314 HCU_EXPERTNormFed 3;
BA_ "GenSigSendType" SG_ 1314 HCU_EXPERTNormFed 0;
BA_ "GenSigSendType" SG_ 1314 HCU_4LModeFed 0;
BA_ "GenSigInvalidValue" SG_ 1314 HCU_EXPERTEcoFed 3;
BA_ "GenSigSendType" SG_ 1314 HCU_EXPERTEcoFed 0;
BA_ "GenSigSendType" SG_ 1314 HCU_SingleRegnRmn 0;
BA_ "GenSigSendType" SG_ 1314 HCU_DRIFTModeSts 0;
BA_ "GenSigSendType" SG_ 1314 HCU_CRC2_522h 0;
BA_ "GenSigSendType" SG_ 1314 HCU_RollgCntr2_522h 0;
BA_ "GenSigSendType" SG_ 1314 HCU_Resd2_522h 0;
BA_ "GenSigInvalidValue" SG_ 1314 HCU_EXPERTAWDFed 3;
BA_ "GenSigSendType" SG_ 1314 HCU_EXPERTAWDFed 0;
BA_ "GenSigInvalidValue" SG_ 1314 HCU_EXPERTRWDFed 3;
BA_ "GenSigSendType" SG_ 1314 HCU_EXPERTRWDFed 0;
BA_ "GenSigInvalidValue" SG_ 1314 HCU_CrossaxisFed 3;
BA_ "GenSigSendType" SG_ 1314 HCU_CrossaxisFed 0;
BA_ "GenSigInvalidValue" SG_ 1314 HCU_EXPERTSportFed 3;
BA_ "GenSigSendType" SG_ 1314 HCU_EXPERTSportFed 0;
BA_ "GenSigSendType" SG_ 1314 HCU_StopChrgnModeFed 0;
BA_ "GenSigInvalidValue" SG_ 1314 HCU_StopChrgnFed 3;
BA_ "GenSigSendType" SG_ 1314 HCU_StopChrgnFed 0;
BA_ "GenSigInvalidValue" SG_ 1314 HCU_CLIMBFed 3;
BA_ "GenSigSendType" SG_ 1314 HCU_CLIMBFed 0;
BA_ "GenSigInvalidValue" SG_ 1314 HCU_EXPERTAutoFed 3;
BA_ "GenSigSendType" SG_ 1314 HCU_EXPERTAutoFed 0;
BA_ "GenSigSendType" SG_ 1314 HCU_HEV_FunctionLimit 0;
BA_ "GenSigSendType" SG_ 1314 HCU_ParkingChargeReminder 0;
BA_ "GenSigSendType" SG_ 1314 HCU_PowerCut 0;
BA_ "GenSigSendType" SG_ 1314 HCU_IMMOReleaseSignal 0;
BA_ "GenSigSendType" SG_ 1314 HCU_LVPowSupSYSAbn_lit 0;
BA_ "GenSigSendType" SG_ 1314 HCU_ChrgnFctMemSt 0;
BA_ "GenSigSendType" SG_ 1314 HCU_PowerModeChangeInhibit 0;
BA_ "GenSigSendType" SG_ 1314 HCU_DisconnectChagWarn 0;
BA_ "GenSigSendType" SG_ 1314 HCU_EngineRunClmReq 0;
BA_ "GenSigSendType" SG_ 1314 HCU_VehicleSpeedMax_Limit 0;
BA_ "GenSigSendType" SG_ 1314 HCU_AccleAbility_Limit 0;
BA_ "GenSigSendType" SG_ 1314 HCU_DriveInhibit_GearP 0;
BA_ "GenSigSendType" SG_ 1314 HCU_SetModeNotChange 0;
BA_ "GenSigSendType" SG_ 1314 HCU_UTURNSnowFed 0;
BA_ "GenSigSendType" SG_ 1314 HCU_PowerLevel 0;
BA_ "GenSigSendType" SG_ 1314 HCU_TowingModeEna 0;
BA_ "GenSigSendType" SG_ 1314 HCU_LeaveVehicleWarning 0;
BA_ "GenSigSendType" SG_ 1314 HCU_DedicatedModeInhibit 0;
BA_ "GenSigSendType" SG_ 1314 HCU_DisChargeStopFault 0;
BA_ "GenSigSendType" SG_ 1314 HCU_RearEDLSts 0;
BA_ "GenSigSendType" SG_ 1314 HCU_FrntEDLSts 0;
BA_ "GenSigSendType" SG_ 1314 HCU_CRC3_522h 0;
BA_ "GenSigSendType" SG_ 1314 HCU_RollgCntr3_522h 0;
BA_ "GenSigSendType" SG_ 1314 HCU_Resd3_522h 0;
BA_ "GenSigSendType" SG_ 1314 HCU_CruiseLimitSpeedValue 0;
BA_ "GenSigSendType" SG_ 1314 HCU_DriveMode_JT 0;
BA_ "GenSigSendType" SG_ 1314 HCU_SocManageFed 0;
BA_ "GenSigSendType" SG_ 1314 HCU_SinglePedalMemFed 0;
BA_ "GenSigSendType" SG_ 1314 HCU_CCOSwtFed 0;
BA_ "GenSigStartValue" SG_ 1314 HCU_Pwr 2000;
BA_ "GenSigSendType" SG_ 1314 HCU_Pwr 0;
BA_ "GenSigSendType" SG_ 1314 HCU_DrvGearShiftFailureIndcn 0;
BA_ "GenSigSendType" SG_ 1314 HCU_UTURNSandFed 0;
BA_ "GenSigSendType" SG_ 1314 HCU_CruiseControlStatus 0;
BA_ "GenSigSendType" SG_ 1314 HCU_EXPERTEESPSet 0;
BA_ "GenSigSendType" SG_ 1314 HCU_EgyRegenLevel 0;
BA_ "GenSigSendType" SG_ 1314 HCU_CRC4_522h 0;
BA_ "GenSigSendType" SG_ 1314 HCU_RollgCntr4_522h 0;
BA_ "GenSigSendType" SG_ 1314 HCU_Resd4_522h 0;
BA_ "GenSigSendType" SG_ 1314 HCU_EngyFlowToDisp 0;
BA_ "GenSigSendType" SG_ 1314 HCU_UTURNGrassFed 0;
BA_ "GenSigSendType" SG_ 1314 HCU_UTURNMudFed 0;
BA_ "GenSigSendType" SG_ 1314 HCU_LTCDispFed 0;
BA_ "GenSigSendType" SG_ 1314 HCU_iTAS_Warn 0;
BA_ "GenSigSendType" SG_ 1314 HCU_iCCO_Warn 0;
BA_ "GenSigSendType" SG_ 1314 HCU_DriveModeChangeFail 0;
BA_ "GenSigSendType" SG_ 1314 HCU_25_Crossaxis_Warn 0;
BA_ "GenSigSendType" SG_ 1314 HCU_25_EDLFed 0;
BA_ "GenSigSendType" SG_ 1314 HCU_DraggingModeRemind 0;
BA_ "GenSigSendType" SG_ 1314 HCU_iTASSceneReq 0;
BA_ "GenSigSendType" SG_ 1314 HCU_25_iTAS_SlopWarn 0;
BA_ "GenSigSendType" SG_ 1314 HCU_ExterTempLowHint 0;
BA_ "GenSigSendType" SG_ 1314 HCU_iTAS_Active 0;
BA_ "GenSigSendType" SG_ 1314 HCU_25_VehSpdOffroadRmn 0;
BA_ "GenSigSendType" SG_ 1314 HCU_DrivingModReq 0;
BA_ "GenSigSendType" SG_ 1314 HCU_25_ADS_FctSts 0;
BA_ "GenSigSendType" SG_ 1314 HCU_25_DRIFTModeSetReq 0;
BA_ "GenSigSendType" SG_ 1314 HCU_25_CrossaxisReq 0;
BA_ "GenSigSendType" SG_ 1314 HCU_25_CCOSwtReq 0;
BA_ "GenSigSendType" SG_ 1314 HCU_CRC5_522h 0;
BA_ "GenSigSendType" SG_ 1314 HCU_RollgCntr5_522h 0;
BA_ "GenSigSendType" SG_ 1314 HCU_Resd5_522h 0;
BA_ "GenSigSendType" SG_ 1314 HCU_25_ErrorCode 0;
BA_ "GenSigSendType" SG_ 1314 HCU_25_ErrorCount 0;
BA_ "GenSigSendType" SG_ 1314 HCU_25_iDRIFT_Warn 0;
BA_ "GenSigSendType" SG_ 1314 HCU_25_SetVehSpdOffroad 0;
BA_ "GenSigSendType" SG_ 1314 HCU_25_LaunchMod_Warn 0;
BA_ "GenSigSendType" SG_ 1314 HCU_25_TAB_Warn 0;
BA_ "GenSigSendType" SG_ 1314 HCU_25_CCO_TextDisp 0;
BA_ "GenSigSendType" SG_ 1314 HCU_25_DCM_Warn 0;
BA_ "GenSigSendType" SG_ 1314 HCU_25_CCMFed 0;
BA_ "GenSigSendType" SG_ 1314 HCU_25_TABReq 0;
BA_ "GenSigInvalidValue" SG_ 1314 HCU_SumElecCns 4095;
BA_ "GenSigSendType" SG_ 1314 HCU_SumElecCns 0;
BA_ "GenSigSendType" SG_ 1314 HCU_CrossBorderSts 0;
BA_ "GenSigSendType" SG_ 1314 HCU_DischgSetSOCFed 0;
BA_ "GenSigSendType" SG_ 1314 HCU_facCleverDrvAct_522h 0;
BA_ "GenSigSendType" SG_ 1314 HCU_stCleverDrvAct_522h 0;
BA_ "GenSigSendType" SG_ 1314 HCU_stCleverRgnAct_522h 0;
BA_ "GenSigSendType" SG_ 1314 HCU_stCleverMainAct_522h 0;
BA_ "GenSigSendType" SG_ 1314 EnergySavingModeSts_522h 0;
BA_ "GenSigSendType" SG_ 1314 HCU_facCleverDrvActRstFed_522h 0;
BA_ "GenSigSendType" SG_ 1314 HCU_SailramainingT_Indc_522h 0;
BA_ "GenSigSendType" SG_ 1314 HCU_ATCM_Operation_REQ_522h 0;
BA_ "GenSigSendType" SG_ 1314 HCU_ModeSwFailureIndc_522h 0;
BA_ "GenSigSendType" SG_ 1314 HCU_Sailmode_522h 0;
BA_ "GenSigSendType" SG_ 1314 HCU_CarSickRelfModeFb 0;
BA_ "GenSigSendType" SG_ 1314 HCU_DeepSnowSts_522h 0;
BA_ "GenSigSendType" SG_ 1314 DriveModeChangeFailReason_522h 0;
BA_ "GenSigSendType" SG_ 1314 HCU_CLIMBDisReason_522h 0;
BA_ "GenSigSendType" SG_ 1314 HCU_CarSickRelfModeDisReason 0;
BA_ "GenSigSendType" SG_ 1314 HCU_DCMSwtFed 0;
BA_ "GenSigSendType" SG_ 1314 HCU_LightSandSts_522h 0;
BA_ "GenSigInvalidValue" SG_ 1316 LHFTirePressure 255;
BA_ "GenSigSendType" SG_ 1316 LHFTirePressure 0;
BA_ "GenSigInvalidValue" SG_ 1316 RHFTirePressure 255;
BA_ "GenSigSendType" SG_ 1316 RHFTirePressure 0;
BA_ "GenSigInvalidValue" SG_ 1316 LHRTirePressure 255;
BA_ "GenSigSendType" SG_ 1316 LHRTirePressure 0;
BA_ "GenSigInvalidValue" SG_ 1316 RHRTirePressure 255;
BA_ "GenSigSendType" SG_ 1316 RHRTirePressure 0;
BA_ "GenSigSendType" SG_ 1324 TirePositionWarning_LHFTire 0;
BA_ "GenSigSendType" SG_ 1324 TirePositionWarning_RHFTire 0;
BA_ "GenSigSendType" SG_ 1324 TirePositionWarning_LHRTire 0;
BA_ "GenSigSendType" SG_ 1324 TirePositionWarning_RHRTire 0;
BA_ "GenSigSendType" SG_ 1329 HCU_27_CRC 0;
BA_ "GenSigSendType" SG_ 1329 HCU_27_RollgCntr 0;
BA_ "GenSigSendType" SG_ 1329 HCU_27_Resd 0;
BA_ "GenSigSendType" SG_ 1329 HCU_27_DriveMode_JT 0;
BA_ "GenSigSendType" SG_ 1329 HCU_27_4LModeFed 0;
BA_ "GenSigSendType" SG_ 1329 HCU_27_CCOSwtFed 0;
BA_ "GenSigSendType" SG_ 1329 HCU_27_FrntEDLSts 0;
BA_ "GenSigSendType" SG_ 1329 HCU_27_RearEDLSts 0;
BA_ "GenSigSendType" SG_ 1329 HCU_Sailmode_531h 0;
BA_ "GenSigSendType" SG_ 1330 DWD_WorkSts 0;
BA_ "GenSigSendType" SG_ 1330 RSensorFailSts 0;
BA_ "GenSigSendType" SG_ 1330 DWD_Distance 0;
BA_ "GenSigSendType" SG_ 1360 ICC_XDriveMode 0;
BA_ "GenSigSendType" SG_ 1417 HCU_RangCnsDispElecThisTrip_589h 0;
BA_ "GenSigSendType" SG_ 1417 HCU_RangCnsDispThisTrip_589h 0;
BA_ "GenSigSendType" SG_ 1417 HCU_RealMileagThisTrip_589h 0;
BA_ "GenSigInvalidValue" SG_ 1417 HCU_ElecCnsAvgThisTrip_589h 4095;
BA_ "GenSigSendType" SG_ 1417 HCU_ElecCnsAvgThisTrip_589h 0;
BA_ "GenSigSendType" SG_ 1417 HCU_RangCnsDispHybThisTrip_589h 0;
BA_ "GenSigSendType" SG_ 1417 HCU_RealMileagElecThisTrip_589h 0;
BA_ "GenSigSendType" SG_ 1417 HCU_TimeHvRdyThisTrip_589h 0;
BA_ "GenSigSendType" SG_ 1417 HCU_ACRangCnsThisTrip_589h 0;
BA_ "GenSigSendType" SG_ 1417 HCU_AuxRangCnsThisTrip_589h 0;
BA_ "GenSigSendType" SG_ 1417 HCU_RealMileagHybThisTrip_589h 0;
BA_ "GenSigSendType" SG_ 1417 HCU_RangCnsDispElecAfRst_589h 0;
BA_ "GenSigSendType" SG_ 1417 HCU_RgnRangBiasThisTrip_589h 0;
BA_ "GenSigSendType" SG_ 1417 HCU_RangCnsDispAfChrg_589h 0;
BA_ "GenSigSendType" SG_ 1417 HCU_RealMileagAfChrg_589h 0;
BA_ "GenSigSendType" SG_ 1417 HCU_RangCnsDispElecAfChrg_589h 0;
BA_ "GenSigSendType" SG_ 1417 HCU_RangCnsDispHybThisAfCh_589h 0;
BA_ "GenSigInvalidValue" SG_ 1417 HCU_FuelCnsAvgAfChrg_589h 499;
BA_ "GenSigSendType" SG_ 1417 HCU_FuelCnsAvgAfChrg_589h 0;
BA_ "GenSigInvalidValue" SG_ 1417 HCU_ElecCnsAvgAfChrg_589h 4095;
BA_ "GenSigSendType" SG_ 1417 HCU_ElecCnsAvgAfChrg_589h 0;
BA_ "GenSigSendType" SG_ 1417 HCU_TimeHvRdyAfChrg_589h 0;
BA_ "GenSigSendType" SG_ 1417 HCU_ACRangCnsAfChrg_589h 0;
BA_ "GenSigInvalidValue" SG_ 1417 HCU_FuelCnsAvgThisTrip_589h 499;
BA_ "GenSigSendType" SG_ 1417 HCU_FuelCnsAvgThisTrip_589h 0;
BA_ "GenSigSendType" SG_ 1417 HCU_RealMileagElecAfChrg_589h 0;
BA_ "GenSigSendType" SG_ 1417 HCU_AuxRangCnsAfChrg_589h 0;
BA_ "GenSigSendType" SG_ 1417 HCU_RgnRangBiasAfChrg_589h 0;
BA_ "GenSigSendType" SG_ 1417 HCU_RangCnsDispAfRst_589h 0;
BA_ "GenSigSendType" SG_ 1417 HCU_RealMileagAfRst_589h 0;
BA_ "GenSigSendType" SG_ 1417 HCU_RealMileagHybAfChrg_589h 0;
BA_ "GenSigInvalidValue" SG_ 1417 HCU_FuelCnsAvgAfRst_589h 499;
BA_ "GenSigSendType" SG_ 1417 HCU_FuelCnsAvgAfRst_589h 0;
BA_ "GenSigInvalidValue" SG_ 1417 HCU_ElecCnsAvgAfRst_589h 4095;
BA_ "GenSigSendType" SG_ 1417 HCU_ElecCnsAvgAfRst_589h 0;
BA_ "GenSigSendType" SG_ 1417 HCU_TimeHvRdyAfRst_589h 0;
BA_ "GenSigSendType" SG_ 1417 HCU_ACRangCnsAfRst_589h 0;
BA_ "GenSigSendType" SG_ 1417 HCU_RangCnsDispHybThisAfRst_589h 0;
BA_ "GenSigSendType" SG_ 1417 HCU_AuxRangCnsAfRst_589h 0;
BA_ "GenSigSendType" SG_ 1417 HCU_RgnRangBiasAfRst_589h 0;
BA_ "GenSigSendType" SG_ 1417 HCU_stCleverDisReason_589h 0;
BA_ "GenSigSendType" SG_ 1417 HCU_RealMileagElecAfRst_589h 0;
BA_ "GenSigSendType" SG_ 1417 HCU_RealMileagHybAfRst_589h 0;
BA_ "GenSigInvalidValue" SG_ 1419 TotalOdometer_km_TRIPOBD_58Bh 16777215;
BA_ "GenSigSendType" SG_ 1419 TotalOdometer_km_TRIPOBD_58Bh 0;
BA_ "GenSigSendType" SG_ 1432 HCU_TotalFaultNum 0;
BA_ "GenSigSendType" SG_ 1432 HCU_FrameIndex 0;
BA_ "GenSigSendType" SG_ 1432 HCU_SupplierNum 0;
BA_ "GenSigSendType" SG_ 1432 HCU_FaultNum1 0;
BA_ "GenSigSendType" SG_ 1432 HCU_FaultNum2 0;
BA_ "GenSigSendType" SG_ 1432 HCU_FaultNum3 0;
BA_ "GenSigSendType" SG_ 1432 HCU_FaultNum4 0;
BA_ "GenSigSendType" SG_ 1432 HCU_FaultNum5 0;
BA_ "GenSigSendType" SG_ 1432 HCU_FaultNum6 0;
BA_ "GenSigSendType" SG_ 1432 HCU_FaultNum7 0;
BA_ "GenSigSendType" SG_ 1432 HCU_FaultNum8 0;
BA_ "GenSigSendType" SG_ 1432 HCU_FaultNum9 0;
BA_ "GenSigSendType" SG_ 1432 HCU_FaultNum10 0;
BA_ "GenSigSendType" SG_ 1432 HCU_FaultNum11 0;
BA_ "GenSigSendType" SG_ 1432 HCU_FaultNum12 0;
BA_ "GenSigSendType" SG_ 1432 HCU_FaultNum13 0;
BA_ "GenSigSendType" SG_ 1432 HCU_FaultNum14 0;
BA_ "GenSigSendType" SG_ 1432 HCU_FaultNum15 0;
BA_ "GenSigSendType" SG_ 1432 HCU_FaultNum16 0;
BA_ "GenSigSendType" SG_ 1432 HCU_FaultNum17 0;
BA_ "GenSigSendType" SG_ 1432 HCU_FaultNum18 0;
BA_ "GenSigSendType" SG_ 1432 HCU_FaultNum19 0;
BA_ "GenSigSendType" SG_ 1432 HCU_FaultNum20 0;
BA_ "GenSigSendType" SG_ 1445 HCU_SumFuCnsThisTrip 0;
BA_ "GenSigSendType" SG_ 1445 HCU_SumElecCnsThisTrip 0;
BA_ "GenSigSendType" SG_ 1445 HCU_SumEgyCnsThisTrip 0;
BA_ "GenSigInvalidValue" SG_ 1445 TotalOdometer_km_virtual_5A5h 16777215;
BA_ "GenSigSendType" SG_ 1445 TotalOdometer_km_virtual_5A5h 0;
BA_ "GenSigSendType" SG_ 1453 ICC_BedStatus 0;
BA_ "GenSigSendType" SG_ 1508 VCU_SoftWareVersion 0;
BA_ "GenSigSendType" SG_ 1508 VCU_IntVersion 0;
BA_ "GenSigSendType" SG_ 1508 VCU_CalVersion 0;
BA_ "GenSigStartValue" SG_ 1582 srcNodeID_RMCU 46;
BA_ "GenSigSendType" SG_ 1582 srcNodeID_RMCU 0;
BA_ "GenSigSendType" SG_ 1582 RMR_RMCU 0;
BA_ "GenSigSendType" SG_ 1582 NMm_RMCU_Reserved1 0;
BA_ "GenSigSendType" SG_ 1582 RMCU_Wakeup_Poweron 0;
BA_ "GenSigSendType" SG_ 1582 RMCU_Wakeup_NM 0;
BA_ "GenSigSendType" SG_ 1582 RMCU_Wakeup_Diag 0;
BA_ "GenSigSendType" SG_ 1582 RMCU_Awake_Poweron 0;
BA_ "GenSigSendType" SG_ 1582 RMCU_Awake_NM 0;
BA_ "GenSigSendType" SG_ 1582 RMCU_Awake_Diag 0;
BA_ "GenSigSendType" SG_ 1582 RMCU_Awake_Discharge 0;
BA_ "GenSigSendType" SG_ 1582 RMCU_Awake_HVON 0;
VAL_ 1170 HVHR_Sts 0 "off" 1 "on" 2 "degraded" 3 "stopped" 4 "shutdown" 5 "shorted" 6 "reset_not_possible";
VAL_ 1172 ExternalTemperature_C 254 "invalid";
VAL_ 1172 CirculationModeDisplaySts 0 "Recirculation_mode" 1 "Air_circulation_mode";
VAL_ 1174 ICC_SetChrgnFctMem 0 "Not active" 1 "Remember" 2 "No Remember" 3 "Reserved";
VAL_ 1174 CTP_PowerModeSet 0 "Not Active" 1 "EV" 2 "HEV" 3 "EV+";
VAL_ 1174 ICC_EmissionMode 0 "Not Active" 1 "Active";
VAL_ 1174 IHU_SetSOC 255 "Not Active";
VAL_ 1181 FLZCU_AlcoholLockInputSts 0 "Invalid" 1 "valid";
VAL_ 1182 OBC_S2Swtsts 0 "open" 1 "close" 2 "reserved" 3 "Error";
VAL_ 1182 OBC_FaultLevelSts 0 "No fault" 1 "Lever1 fault" 2 "Lever2 fault" 3 "Lever3 fault" 4 "Lever4 fault" 5 "Lever5 fault" 6 "Reserved" 7 "Reserved";
VAL_ 1182 OBC_ElectronicLockSts 0 "Unlock" 1 "Lock" 2 "Lock error" 3 "Unlock error" 4 "Elock error";
VAL_ 1182 OBC_WorkingMode 0 "Init" 1 "Standby" 2 "Chg" 3 "Default" 4 "Preheat" 5 "Keepwarm" 6 "V2L" 7 "V2V" 8 "Powerdown" 9 "Afterrun" 10 "Fault" 11 "Reserved" 12 "Reserved" 13 "Reserved" 14 "Reserved" 15 "Reserved";
VAL_ 1182 OBC_Worksts 0 "default" 1 "steady power" 2 "steady voltage" 3 "Reserved";
VAL_ 1182 OBC_CPLineSts 0 "Not connected" 1 "Connected and valid" 2 "Connected but invalid" 3 "Error";
VAL_ 1182 OBC_HV_OutputUnderVolt 0 "No fault" 1 "Fault";
VAL_ 1182 OBC_HV_OutputOverVolt 0 "No fault" 1 "Fault";
VAL_ 1182 OBC_HV_OutputShortCircuit 0 "No fault" 1 "Fault";
VAL_ 1182 OBC_InputUnderVolt 0 "No fault" 1 "Fault";
VAL_ 1182 OBC_InputOverVolt 0 "No fault" 1 "Fault";
VAL_ 1182 OBC_HighCurrOutputFault 0 "No fault" 1 "Fault";
VAL_ 1182 OBC_CAN_Fault 0 "No fault" 1 "Fault";
VAL_ 1182 OBC_KL30_UnderVolt 0 "No fault" 1 "Fault";
VAL_ 1184 TDU_1_EAC_Sts 0 "COMP_OFF" 1 "COMP_ON" 2 "COMP_STOPP" 3 "COMP_DIRECTPWM" 4 "COMP_ON_DEGRADED";
VAL_ 1184 HVH_Sts 0 "Start_mode" 1 "Standby_mode" 2 "Normal_heating_mode" 3 "Power_limit_mode" 4 "Neutral_state" 5 "HW_check_state" 6 "Temprory_lock_state" 7 "Permanent_lock_state";
VAL_ 1195 BNCM_8_HV_Req 0 "Init" 1 "HV ON" 2 "HV OFF" 3 "No Action";
VAL_ 1199 TCM_1_TrailerSts 0 "Disconnect" 1 "Connect";
VAL_ 1200 SOC_STATE 0 "Deviation_higher_15%" 1 "Deviation_lower_15%" 2 "Deviation_lower_10%" 3 "Startup_Invalid";
VAL_ 1200 SOH_SUL_STATE 0 "Deviation_higher_15%" 1 "Deviation_lower equals_15%" 2 "Reserved" 3 "Invalid Value";
VAL_ 1200 SOFV_StopEnable_STATE 0 "Deviation_higher_500mV" 1 "Deviation_lower equals_500mV" 2 "Reserved" 3 "Invalid Value";
VAL_ 1200 SOFV_Restart_STATE 0 "Deviation_higher_500mV" 1 "Deviation_lower equals_500mV" 2 "Reserved" 3 "Invalid Value";
VAL_ 1204 VCU_AcceleratorPosRawIVD 0 "Valid" 1 "Invalid";
VAL_ 1204 VCU_1_G_PTReady 0 "LmpOFF" 1 "LmpON";
VAL_ 1204 VCU_1_G_DriveMode 0 "Not Active" 1 "ECO" 2 "Normal" 3 "Sport" 4 "Snow" 5 "Off Road" 6 "Individual" 7 "Reserved";
VAL_ 1204 VCU_1_G_BookChrgSetResponse 0 "Default" 1 "Success" 2 "Cancelled" 3 "Fail" 4 "Reserved";
VAL_ 1204 VCU_1_G_HvBattKeepWarmSts 0 "NotWarm" 1 "Warming" 2 "ExitWarm" 3 "WarmCompete" 4 "Reserved" 5 "Reserved" 6 "Reserved" 7 "Reserved";
VAL_ 1204 VCU_1_G_HvBattKeepWarmActiveReq 0 "default" 1 "StartWarm" 2 "EndWarm" 3 "Reserved";
VAL_ 1204 VCU_1_G_HundECAver 511 "Invalid";
VAL_ 1204 VCU_1_G_BookChrgSetStsFb 0 "NotBook" 1 "Booked" 2 "Reserved";
VAL_ 1204 VCU_1_G_EgyRegenLevel 0 "Off" 1 "Low" 2 "High" 3 "Reserved";
VAL_ 1204 VCU_1_G_PRNDGearAct 0 "Init" 1 "P" 2 "R" 3 "N" 4 "D" 5 "Reserved" 6 "Reserved" 7 "Reserved";
VAL_ 1207 HVH_Sts_400V 0 "OFF" 1 "ON" 2 "PTC_Degraded" 3 "PTC_Stopped" 4 "PTC_Shutdown" 5 "PTC_Shorted" 6 "PTC_Reset not Possible";
VAL_ 1207 Flag_400V_800V 0 "400V" 1 "800V" 2 "Reserved" 3 "Reserved";
VAL_ 1209 VCU_2_G_GasPedalPosInvalidData 0 "Valid" 1 "Invalid";
VAL_ 1209 VCU_2_G_PowerLimit 0 "LmpOFF" 1 "LmpON";
VAL_ 1209 VCU_2_G_BrakeLightReq 0 "LmpOFF" 1 "LmpON";
VAL_ 1209 VCU_2_G_VehicleSystemFailure 0 "Fail not present" 1 "Fail present";
VAL_ 1209 OnekeyHVOffSuccess_4B9h 0 "Not Success" 1 "Success";
VAL_ 1209 VCU_2_G_BootloadSts 0 "No Display" 1 "Display";
VAL_ 1209 VCU_2_G_DischgSts 0 "No Active" 1 "Active";
VAL_ 1209 VCU_2_G_BrakePedalStsValidData 0 "Valid" 1 "Not Valid";
VAL_ 1209 VCU_2_G_ExhibitionMod 0 "No Active" 1 "Active";
VAL_ 1209 VCU_2_G_BrakePedalSts 0 "Not applied" 1 "Applied";
VAL_ 1209 VCU_2_G_DCDCEnable 0 "Disable" 1 "Enable";
VAL_ 1209 VCU_2_G_HVReady 0 "LmpOFF" 1 "LmpON";
VAL_ 1209 Res_VCU_2_G_Brake_state 0 "Not braking" 1 "Braking";
VAL_ 1209 VCU_2_G_VCUEnergyflow 0 "NotHvReady" 1 "charging" 2 "RWD" 3 "recycle" 4 "external_discharge" 5 "battery_heat" 6 "AWD" 7 "FWD" 8 "HV_ON" 9 "Reserved";
VAL_ 1209 VCU_2_G_GasPedalPosition 1023 "Invalid";
VAL_ 1209 VCU_2_G_DrvGearShiftFailureIndcn 0 "No Command" 1 "rake pedal applied" 2 "Over Speed" 3 "Charge Gun Connect" 4 "EPB Can Not Lock" 5 "EPB Can Not Release" 6 "Invalid shift" 7 "Shift fault";
VAL_ 1209 VCU_2_G_OnekeyHVoffStyle 0 "NotActive" 1 "Independent" 2 "Park Button";
VAL_ 1217 ASU_ECASErrSts_4C1h 0 "no error" 1 "fault priority 1(minor)" 2 "fault priority 2(seriously)" 3 "fault priority 3(Very seriously)";
VAL_ 1217 ASU_SuspTarLvl_4C1h 0 "No requirement" 1 "Very high level" 2 "high2 level" 3 "high1 level" 4 "normal level" 5 "low level" 6 "very low level" 7 "easy Loading level";
VAL_ 1217 ASU_CDCErrSts_4C1h 0 "no error" 1 "error";
VAL_ 1217 ASU_SuspDampingLvl_4C1h 0 "None" 1 "Very Hard" 2 "Hard" 3 "Middle" 4 "Soft" 5 "Reserved" 6 "Reserved" 7 "Reserved";
VAL_ 1219 HCU_HVHRAllow 0 "Unable" 1 "Enable";
VAL_ 1219 VCU_CLMEACAllow 0 "Unable" 1 "Enable";
VAL_ 1219 VCU_CLMHVHAllow 0 "Unable" 1 "Enable";
VAL_ 1219 VCU_CLMHVReady 0 "LmpOFF" 1 "LmpON";
VAL_ 1219 VCU_PwtCoolingLvl 0 "L0" 1 "L1" 2 "L2" 3 "L3" 4 "L4";
VAL_ 1224 BMS_Chg_Sts 1 "Parking chagre" 2 "Driving charge" 3 "no charge" 4 "charge complete" 14 "Abnomal" 15 "Invalid";
VAL_ 1231 TBOX_1_BookChrgActiveReq 0 "Not Active" 1 "StartCharge" 2 "EndCharge" 3 "Not used";
VAL_ 1231 TBOX_BookChrgSetReq 0 "default" 1 "BookSet" 2 "CancellBook" 3 "Reserved";
VAL_ 1231 TBOX_StopChrgReq 0 "not active" 1 "active";
VAL_ 1231 TBOX_KeepWarmSet 0 "OFF" 1 "ON";
VAL_ 1231 TBOX_HV_Req 0 "not active" 1 "HVON" 2 "HVOFF" 3 "Reserved";
VAL_ 1231 TBOX_BookChrgSts 0 "Default" 1 "WaitingCharge" 2 "Charging" 3 "ChargeFinished" 4 "Reserved";
VAL_ 1231 TBOX_ChgSOCSet_4CFh 0 "Not Active" 254 "Abnormal" 255 "Invalid";
VAL_ 1231 TBOX_HvBattKeepWarmActiveReq 0 "Not active" 1 "StartWarm" 2 "EndWarm" 3 "Not Used";
VAL_ 1231 TBOX_ChgSOCPrioritySts_4CFh 0 "ChrgDuration_FullPriority" 1 "SOC_SetPriority";
VAL_ 1239 ICC_DisChg 0 "Not Active" 1 "OFF" 2 "V2L ON" 3 "V2V ON";
VAL_ 1239 ICC_DisChgPercent 0 "Not Active";
VAL_ 1239 ICC_ChgSocSet 0 "Not Active" 254 "Abnormal" 255 "Invalid";
VAL_ 1239 ICC_TowingMode 0 "Not Active" 1 "OFF" 2 "ON" 3 "Not Used";
VAL_ 1239 ICC_CampMode 0 "Not Active" 1 "OFF" 2 "ON" 3 "Not Used";
VAL_ 1239 ICC_StCleverMainReq_4D7h 0 "Not Active" 1 "ON" 2 "OFF" 3 "Reserved";
VAL_ 1239 ICC_StCleverRgnReq_4D7h 0 "Not Active" 1 "ON" 2 "OFF" 3 "Reserved";
VAL_ 1239 ICC_EnergySavingModeReq_4D7h 0 "Not Active" 1 "ON" 2 "OFF" 3 "Reserved";
VAL_ 1239 ICC_StCleverDrvReq_4D7h 0 "Not Active" 1 "ON" 2 "OFF" 3 "Reserved";
VAL_ 1239 ICC_FacCleverDrvActRst_4D7h 0 "Not Active" 1 "Reset";
VAL_ 1239 ICC_EngyVehSpdLi_4D7h 0 "Not Active" 1 "Active";
VAL_ 1246 ICC_KeepWarm 0 "Not_active" 1 "Open_AC" 2 "Open_NotAC" 3 "Closed";
VAL_ 1248 FRZCU_RKEButtAct 0 "None" 1 "UnLockButt_LongPress" 2 "RemoteLongPress" 3 "Reserved" 4 "Reserved" 5 "Reserved" 6 "Reserved" 7 "Reserved";
VAL_ 1250 ICC_1_OTAHV_Req 0 "Not_active" 1 "HVON" 2 "HVOFF" 3 "Reserved";
VAL_ 1250 ICC_SteeringMode 0 "Not_Active" 1 "Normal" 2 "Sport" 3 "Light";
VAL_ 1250 ICC_SuspensionDamping 0 "Not_Active" 1 "Soft" 2 "Middle" 3 "Hard";
VAL_ 1250 ICC_SuspensionHeight 0 "Not_Active" 1 "Very_Low" 2 "Low" 3 "Normal" 4 "High" 5 "Very_High";
VAL_ 1250 ICC_SelfClearing 0 "Not_active" 1 "Enable";
VAL_ 1250 ICC_PetModeHV_Req 0 "Not_Active" 1 "HVON" 2 "HVOFF" 3 "Reserved";
VAL_ 1250 ICC_SentinelHV_Req 0 "Not_active" 1 "HVON" 2 "HVOFF" 3 "Reserved";
VAL_ 1250 ICC_CCMReq_4E2h 0 "Not Active" 1 "sand" 2 "snow" 3 "crawl" 4 "forest" 5 "Tug of war" 6 "Rescue" 7 "Reserved";
VAL_ 1250 ICC_TRIPSelfClearing_4E2h 0 "Not active" 1 "Enable";
VAL_ 1252 TotalOdometer_km_OBD 16777215 "Invalid";
VAL_ 1252 TotalOdometer_km_OBDValidData 0 "Valid" 1 "Not valid";
VAL_ 1265 ICC_CinemaStatus 0 "Not Active" 1 "ON" 2 "OFF" 3 "Not Used";
VAL_ 1288 TboxLocalTiValid 0 "invalid" 1 "valid";
VAL_ 1290 BMS_HvBattCellUnderU 0 "Normal" 1 "Fault Level 1" 2 "Fault Level 2" 3 "Fault Level 3" 4 "Fault Level 4";
VAL_ 1290 BMS_HvBattUnderU 0 "Normal" 1 "Fault Level 1" 2 "Fault Level 2";
VAL_ 1291 BMS_SOCLight 127 "Invalid";
VAL_ 1298 APTC_ErrorLevel 0 "Normal" 1 "Level_1" 2 "Level_2" 3 "Level_3" 4 "Level_4";
VAL_ 1314 HCU_V2lDisChgBck 0 "Not_Active" 1 "V2L_ON" 2 "OFF";
VAL_ 1314 HCU_DisChgMemFed 0 "Not_Active" 1 "Remember" 2 "No_Remember" 3 "Reserved";
VAL_ 1314 HCU_V2VDisChgBck 0 "Not_Active" 1 "V2V_ON" 2 "OFF";
VAL_ 1314 HCU_V2l_IntlDisChgBck 0 "Not_Active" 1 "V2L_ON" 2 "OFF";
VAL_ 1314 HCU_FuelDetnOpDefeated 0 "No_Prompt" 1 "Prompt";
VAL_ 1314 HCU_FuelDetnModSwtFed 0 "Not_Active" 1 "ON" 2 "OFF" 3 "Invalid";
VAL_ 1314 HCU_FuelDetnStateFed 0 "Not_Active" 1 "HighIdle" 2 "LowIdle" 3 "Invalid";
VAL_ 1314 HCU_HVDownRepairModeFed 0 "Not_Active" 1 "ON" 2 "OFF" 3 "Invalid";
VAL_ 1314 HCU_TrailerMode 0 "Not_Active" 1 "ON" 2 "OFF" 3 "Invalid";
VAL_ 1314 HCU_TABSwtFed_522h 0 "Not_Active" 1 "Active" 2 "Stand_by" 3 "Failed";
VAL_ 1314 HCU_MotSelfHeatLvlReq 0 "No Request" 1 "Level 1" 2 "Level 2" 3 "Level 3" 4 "Level 4" 5 "Level 5" 6 "Reserved" 7 "Reserved";
VAL_ 1314 HCU_MotSelfHeatEnReq 0 "Prohibit" 1 "Permission";
VAL_ 1314 HCU_KeyDriveModememory 0 "Not_Active" 1 "Remember" 2 "No_Remember";
VAL_ 1314 HCU_DrivePowerDispSetFed 0 "Not_Active" 1 "PercentDisp" 2 "kWDisp";
VAL_ 1314 HCU_TCMStsReq_522h 0 "Disable" 1 "Enable";
VAL_ 1314 HCU_EXPERTNormFed 0 "Not_Active" 1 "ON" 2 "OFF" 3 "Invalid";
VAL_ 1314 HCU_4LModeFed 0 "Not_Active" 1 "Active";
VAL_ 1314 HCU_EXPERTEcoFed 0 "Not_Active" 1 "ON" 2 "OFF" 3 "Invalid";
VAL_ 1314 HCU_SingleRegnRmn 0 "Not_Active" 1 "Active";
VAL_ 1314 HCU_DRIFTModeSts 0 "Not_Active" 1 "Entry_Mode" 2 "Master_mode" 3 "Expert_mode";
VAL_ 1314 HCU_EXPERTAWDFed 0 "Not_Active" 1 "ON" 2 "OFF" 3 "Invalid";
VAL_ 1314 HCU_EXPERTRWDFed 0 "Not_Active" 1 "ON" 2 "OFF" 3 "Invalid";
VAL_ 1314 HCU_CrossaxisFed 0 "Not_Active" 1 "Active" 2 "Stand_by" 3 "Failed";
VAL_ 1314 HCU_EXPERTSportFed 0 "Not_Active" 1 "ON" 2 "OFF" 3 "Invalid";
VAL_ 1314 HCU_StopChrgnModeFed 0 "Not_Active" 1 "Silence" 2 "Quick";
VAL_ 1314 HCU_StopChrgnFed 0 "Not_Active" 1 "ON" 2 "OFF" 3 "Invalid";
VAL_ 1314 HCU_CLIMBFed 0 "Not_Active" 1 "ON" 2 "OFF" 3 "InValid";
VAL_ 1314 HCU_EXPERTAutoFed 0 "Not_Active" 1 "ON" 2 "OFF" 3 "Invalid";
VAL_ 1314 HCU_HEV_FunctionLimit 0 "Not_Active" 1 "Active";
VAL_ 1314 HCU_ParkingChargeReminder 0 "Not_Active" 1 "Active";
VAL_ 1314 HCU_PowerCut 0 "Not_Active" 1 "Active";
VAL_ 1314 HCU_IMMOReleaseSignal 0 "Not_Active" 1 "Active";
VAL_ 1314 HCU_LVPowSupSYSAbn_lit 0 "Not_Active" 1 "Active";
VAL_ 1314 HCU_ChrgnFctMemSt 0 "Not_Active" 1 "Remember" 2 "No_Remember" 3 "Reserved";
VAL_ 1314 HCU_PowerModeChangeInhibit 0 "Not_Active" 1 "Active";
VAL_ 1314 HCU_DisconnectChagWarn 0 "Not_Active" 1 "Active";
VAL_ 1314 HCU_EngineRunClmReq 0 "Not_Active" 1 "Active";
VAL_ 1314 HCU_VehicleSpeedMax_Limit 0 "Not_Active" 1 "Active";
VAL_ 1314 HCU_AccleAbility_Limit 0 "Not_Active" 1 "Active";
VAL_ 1314 HCU_DriveInhibit_GearP 0 "Not_Active" 1 "Active";
VAL_ 1314 HCU_SetModeNotChange 0 "Not_Active" 1 "Active";
VAL_ 1314 HCU_UTURNSnowFed 0 "Not_Active" 1 "Active";
VAL_ 1314 HCU_PowerLevel 0 "Init" 1 "Level_1" 2 "Level_2" 3 "Level_3" 4 "Level_4";
VAL_ 1314 HCU_TowingModeEna 0 "No Prompt" 1 "Prompt";
VAL_ 1314 HCU_LeaveVehicleWarning 0 "Not_Active" 1 "Active";
VAL_ 1314 HCU_DedicatedModeInhibit 0 "Not_Active" 1 "Active";
VAL_ 1314 HCU_DisChargeStopFault 0 "Init" 1 "LowSOC" 2 "LowFuel";
VAL_ 1314 HCU_RearEDLSts 0 "No Lock" 1 "UNLock" 2 "Lock" 3 "Warning" 4 "UnAvailable" 5 "Stuck_Open" 6 "Stuck_Close" 7 "Reserved" 8 "Reserved" 9 "Reserved";
VAL_ 1314 HCU_FrntEDLSts 0 "No Lock" 1 "UNLock" 2 "Lock" 3 "Warning" 4 "UnAvailable" 5 "Stuck Open" 6 "Stuck Close" 7 "Rear4LReq" 8 "RearReq" 9 "4LReq";
VAL_ 1314 HCU_DriveMode_JT 0 "ECO" 1 "NORMAL" 2 "SPORT" 3 "SNOW" 4 "MUD" 5 "OffRoad" 6 "SAND" 7 "ROCK" 8 "EXPERT" 9 "X" 10 "WADE" 11 "UTURN" 12 "DRIFT" 13 "TOW" 14 "OffroadRace" 15 "CarSickRelfMode" 16 "CleverEngy" 17 "DCM";
VAL_ 1314 HCU_SocManageFed 0 "Default" 1 "Pure_electricity_priority_mode" 2 "Fuel_priority_mode" 3 "SOC_hold_mode" 4 "SAVE" 5 "Charge";
VAL_ 1314 HCU_SinglePedalMemFed 0 "ON" 1 "OFF";
VAL_ 1314 HCU_CCOSwtFed 0 "Not_Active" 1 "Active" 2 "Stand_by" 3 "Failed";
VAL_ 1314 HCU_DrvGearShiftFailureIndcn 0 "No_Command" 1 "brake_pedal_applied" 2 "Over_Speed" 3 "Charge_Gun_Connect" 4 "EPB_Can_Not_Lock" 5 "EPB_Can_Not_Release" 6 "Invalid_shift" 7 "Shift_fault" 8 "BrkPedl_to_start" 9 "OpenDoor_Shift";
VAL_ 1314 HCU_UTURNSandFed 0 "OFF" 1 "ON";
VAL_ 1314 HCU_CruiseControlStatus 0 "Not_Active" 1 "Active" 2 "Stand_by" 3 "Fault";
VAL_ 1314 HCU_EXPERTEESPSet 0 "ALLON" 1 "TCS_VDC_OFF" 2 "ALLOFF" 3 "Reserved";
VAL_ 1314 HCU_EgyRegenLevel 0 "Off" 1 "Low" 2 "High" 3 "middle" 4 "SinglePedl";
VAL_ 1314 HCU_EngyFlowToDisp 0 "Init" 1 "No_EngyFlow" 2 "Engine Idling" 3 "EV_FWD" 4 "EV_FWD_Regene" 5 "EV_RWD" 6 "EV_RWD_Regene" 7 "EV_4WD" 8 "EV_4WD_Regene" 9 "Series_FWD_BattChg" 10 "Series_FWD_BattDisChg" 11 "Series_FWD_BattNoCurr" 12 "Series_FWD_Regene" 13 "Series_RWD_BattChg" 14 "Series_RWD_BattDisChg" 15 "Series_RWD_BattNoCurr" 16 "Series_RWD_Regene" 17 "Series_4WD_BattChg" 18 "Series_4WD_BattDisChg" 19 "Series_4WD_BattNoCurr" 20 "Series_4WD_Regene" 21 "Parallel_FWD_BattChg" 22 "Parallel_FWD_BattDisChg" 23 "Parallel_FWD_BattNoCurr" 24 "Parallel_FWD_Regene" 25 "Parallel_4WD_BattChg" 26 "Parallel_4WD_BattDisChg" 27 "Parallel_4WD_BattNoCurr" 28 "Parallel_4WD_Regene" 29 "StopCharging_BatChg" 30 "StopCharging_BatDChg" 31 "StopCharging_BatNoCurr";
VAL_ 1314 HCU_UTURNGrassFed 0 "OFF" 1 "ON";
VAL_ 1314 HCU_UTURNMudFed 0 "OFF" 1 "ON";
VAL_ 1314 HCU_LTCDispFed 0 "Not Active" 1 "WLTC" 2 "CLTC";
VAL_ 1314 HCU_iTAS_Warn 0 "No_Warn" 1 "ELD Unable to lock" 2 "Please_Release_EPB" 3 "Please_slow_down" 4 "Disc temperature too high" 5 "vehicle is stuck" 6 "iTAS active max time" 7 "Please Open in D";
VAL_ 1314 HCU_iCCO_Warn 0 "No_Warn" 1 "Please_Release_EPB" 2 "Please_slow_down" 3 "Please_Close_ Door and Belt" 4 "Please_Open in D or N" 5 "Please_Close_APA/ACC/CC" 6 "Please_Exit_HDC/AVH" 7 "Please_Switch to Snow/Mud/Sand/Rock" 8 "Please Depress the brake pedal" 9 "iCCO Exited" 10 "Reserved" 11 "Reserved" 12 "Reserved" 13 "Reserved" 14 "Reserved" 15 "Reserved";
VAL_ 1314 HCU_DriveModeChangeFail 0 "NOT FAIL" 1 "FAIL";
VAL_ 1314 HCU_25_Crossaxis_Warn 0 "No_Warn" 1 "Please_Release_EPB" 2 "Crossaxis Exited" 3 "Please_Open in D" 4 "Please_Close_ Door and Belt" 5 "Please Depress the brake pedal" 6 "Not Adjust Suspension Height" 7 "Reserved";
VAL_ 1314 HCU_25_EDLFed 0 "Not_Active" 1 "Forward" 2 "Backward" 3 "Reserved";
VAL_ 1314 HCU_DraggingModeRemind 0 "Not_Active" 1 "Enter" 2 "Working" 3 "Exit" 4 "Reserved" 5 "Reserved" 6 "Reserved" 7 "Reserved";
VAL_ 1314 HCU_iTASSceneReq 0 "Not Active" 1 "Snow" 2 "Mud" 3 "Sand" 4 "Grass" 5 "Exit";
VAL_ 1314 HCU_25_iTAS_SlopWarn 0 "No_Warn" 1 "Active" 2 "Reserved" 3 "Reserved";
VAL_ 1314 HCU_ExterTempLowHint 0 "Init" 1 "Temp to HEV" 2 "Temp to EngRun" 3 "reserved";
VAL_ 1314 HCU_iTAS_Active 0 "Not_Active" 1 "Standby" 2 "Active" 3 "Filed";
VAL_ 1314 HCU_25_VehSpdOffroadRmn 0 "Not Acitve" 1 "Acitve";
VAL_ 1314 HCU_DrivingModReq 0 "Normal" 1 "Snow" 2 "Mud" 3 "Sand" 4 "Rock" 5 "Wade" 6 "Expert" 7 "UTURN" 8 "DRIFT" 9 "OffroadRace" 10 "DCM" 11 "Reserved" 12 "Reserved" 13 "Reserved" 14 "Reserved" 15 "Reserved" 16 "Reserved" 17 "Reserved" 18 "Reserved" 19 "Reserved" 20 "Reserved" 21 "Reserved" 22 "Reserved" 23 "Reserved" 24 "Reserved" 25 "Reserved" 26 "Reserved" 27 "Reserved" 28 "Reserved" 29 "Reserved" 30 "Reserved" 31 "invalid";
VAL_ 1314 HCU_25_ADS_FctSts 0 "Off" 1 "On";
VAL_ 1314 HCU_25_DRIFTModeSetReq 0 "Not Active" 1 "Entry Mode" 2 "Master mode" 3 "Expert mode";
VAL_ 1314 HCU_25_CrossaxisReq 0 "Not Active" 1 "ON" 2 "OFF" 3 "Not used";
VAL_ 1314 HCU_25_CCOSwtReq 0 "Not Active" 1 "ON" 2 "OFF" 3 "invalid";
VAL_ 1314 HCU_25_iDRIFT_Warn 0 "No_Warn" 1 "Please_Close_ Door and Belt" 2 "Please stop the vehicle" 3 "Error" 4 "Not Adjust Suspension Height";
VAL_ 1314 HCU_25_SetVehSpdOffroad 0 "No_Warn" 1 "Active" 2 "Reserved" 3 "Reserved";
VAL_ 1314 HCU_25_LaunchMod_Warn 0 "No_Warn" 1 "Active" 2 "Exit" 3 "Error" 4 "Reserved" 5 "Reserved" 6 "Reserved" 7 "Reserved";
VAL_ 1314 HCU_25_TAB_Warn 0 "No Warn" 1 "Please open CCO" 2 "Please Unlock EDL" 3 "Prohibit locking EDL" 4 "Reserved";
VAL_ 1314 HCU_25_CCO_TextDisp 0 "No_Warn" 1 "Please_Release_EPB" 2 "Please_Slow_Down" 3 "Please_Close_ Door and Belt" 4 "Please_Open in D" 5 "Please_Close_APA/ACC/CC" 6 "Please_Exit_HDC" 7 "Please_Switch to Mud/Sand/Rock" 8 "Reduce_Speed_Below 12kph" 9 "Please_Close_CCO" 10 "CC0 Exited";
VAL_ 1314 HCU_25_DCM_Warn 0 "No_Warn" 1 "Please_Release_EPB" 2 "Please_Close_ Door and Belt" 3 "Please_Open in D/R" 4 "Please_Close_APA/ACC/CC" 5 "Please_Exit_HDC" 6 "Please Depress the brake pedal" 7 "CCM Exited" 8 "Please enter or exit this mode when the vehicle is stationary" 9 "power limit" 10 "Please release the accelerator pedal" 11 "Please depress the brake pedal" 12 "Reserved" 13 "Reserved" 14 "Reserved" 15 "Reserved";
VAL_ 1314 HCU_25_CCMFed 0 "Not Active" 1 "On" 2 "Off" 3 "Reserved";
VAL_ 1314 HCU_25_TABReq 0 "Not Active" 1 "ON" 2 "OFF" 3 "Not used";
VAL_ 1314 HCU_CrossBorderSts 0 "Not Active" 1 "On" 2 "Off" 3 "Reserved";
VAL_ 1314 HCU_stCleverDrvAct_522h 0 "OFF" 1 "ON" 2 "Reserved" 3 "Invalid";
VAL_ 1314 HCU_stCleverRgnAct_522h 0 "OFF" 1 "ON" 2 "Reserved" 3 "Invalid";
VAL_ 1314 HCU_stCleverMainAct_522h 0 "OFF" 1 "ON" 2 "Reserved" 3 "Invalid";
VAL_ 1314 EnergySavingModeSts_522h 0 "Not Active" 1 "ON" 2 "OFF" 3 "Reserved";
VAL_ 1314 HCU_facCleverDrvActRstFed_522h 0 "Not Active" 1 "success" 2 "Fail" 3 "Reserved";
VAL_ 1314 HCU_ATCM_Operation_REQ_522h 0 "Not Active" 1 "Switch to sailfunc indiction" 2 "Switch to upbeach indiction" 3 "misoperation indiction”press sailfunc sw when conenmod “" 4 "misoperation indiction”press upbeach  sw when conenmod“" 5 "misoperation indiction”press upbeach sw when wadests“" 6 "reserved" 7 "reserved";
VAL_ 1314 HCU_ModeSwFailureIndc_522h 0 "Not Active" 1 "Entry navigation failed“Car door is not closed”" 2 "Entry navigation failed“Rearview mirror not deployed”" 3 "Entry navigation failed“Intake and exhaust waterproof valve malfunction”" 4 "Entry navigation failed“Speed too fast”" 5 "Entry navigation failed“Low battery”" 6 "Entry navigation failed“Air conditioning drain valve malfunction|Cooling fan malfunction”";
VAL_ 1314 HCU_Sailmode_522h 0 "Convenmod" 1 "SalWadeSts" 2 "DpWadeSts" 3 "SailingFunc" 4 "UpbeachSts" 5 "WaitfinspSts" 6 "EmerfloatingSts" 7 "Reserved";
VAL_ 1314 HCU_CarSickRelfModeFb 0 "NotActive" 1 "ON" 2 "OFF";
VAL_ 1314 HCU_DeepSnowSts_522h 0 "NOT ACTIVE" 1 "ON" 2 "OFF";
VAL_ 1314 DriveModeChangeFailReason_522h 0 "NOT FAIL" 1 "Fail" 2 "EngySavMod_Fail" 3 "Reserved";
VAL_ 1314 HCU_CLIMBDisReason_522h 0 "No_Warn" 1 "Please_brake_to_PtReady" 2 "Please_Open in D or N" 3 "Please_Switch to Rock" 4 "TCS/DTC/AVH/ABS_Active" 5 "Please_Close_APA/ACC/CC" 6 "Please_Slow_Down" 7 "Drive_System_Err" 8 "LongitudinalAcceleration_Invld" 9 "Pleased quit iCCO" 10 "OPD_Brake_not_Available" 11 "IPB_System_Err" 12 "Reserved" 13 "Reserved" 14 "Reserved" 15 "Reserved";
VAL_ 1314 HCU_CarSickRelfModeDisReason 0 "No prompts" 1 "Please exit off-road mode" 2 "Please exit CCO mode" 3 "Please exit power saving mode" 4 "Please exit Towing Mode" 5 "Please exit TrailerMode" 6 "Please exit CCMode" 7 "Please exit ADS mode";
VAL_ 1314 HCU_DCMSwtFed 0 "not active" 1 "sand" 2 "snow" 3 "crawl" 4 "forest" 5 "Tug of war" 6 "Rescue" 7 "Reserved";
VAL_ 1314 HCU_LightSandSts_522h 0 "Inactive" 1 "ON" 2 "OFF";
VAL_ 1324 TirePositionWarning_LHFTire 0 "Normal" 1 "Rapid_Air_Loss(Reserved)" 2 "Low_Pressure" 3 "Low Batter" 4 "High_Pressure(Reserved)" 5 "High_Temperature" 6 "Error_Mode" 7 "Not_used(Reserved)";
VAL_ 1324 TirePositionWarning_RHFTire 0 "Normal" 1 "Rapid_Air_Loss(Reserved)" 2 "Low_Pressure" 3 "Low Batter" 4 "High_Pressure(Reserved)" 5 "High_Temperature" 6 "Error_Mode" 7 "Not_used(Reserved)";
VAL_ 1324 TirePositionWarning_LHRTire 0 "Normal" 1 "Rapid_Air_Loss(Reserved)" 2 "Low_Pressure" 3 "Low Batter" 4 "High_Pressure(Reserved)" 5 "High_Temperature" 6 "Error_Mode" 7 "Not_used(Reserved)";
VAL_ 1324 TirePositionWarning_RHRTire 0 "Normal" 1 "Rapid_Air_Loss(Reserved)" 2 "Low_Pressure" 3 "Low Batter" 4 "High_Pressure(Reserved)" 5 "High_Temperature" 6 "Error_Mode" 7 "Not_used(Reserved)";
VAL_ 1329 HCU_27_DriveMode_JT 0 "ECO" 1 "NORMAL" 2 "SPORT" 3 "SNOW" 4 "MUD" 5 "OffRoad" 6 "SAND" 7 "ROCK" 8 "EXPERT" 9 "X" 10 "WADE" 11 "UTURN" 12 "DRIFT" 13 "TOW" 14 "OffroadRace" 15 "CarSickRelfMode" 16 "CleverEngy" 17 "DCM";
VAL_ 1329 HCU_27_4LModeFed 0 "Not Active" 1 "Active";
VAL_ 1329 HCU_27_CCOSwtFed 0 "Not Active" 1 "Active" 2 "Stand_by" 3 "Failed";
VAL_ 1329 HCU_27_FrntEDLSts 0 "NO Lock" 1 "UNLock" 2 "Lock" 3 "Warning" 4 "UnAvailable" 5 "Stuck Open" 6 "Stuck Close" 7 "Rear4LReq" 8 "RearReq" 9 "4LReq";
VAL_ 1329 HCU_27_RearEDLSts 0 "NO Lock" 1 "UNLock" 2 "Lock" 3 "Warning" 4 "UnAvailable" 5 "Stuc Open" 6 "Stuck Close" 7 "Reserved" 8 "Reserved" 9 "Reserved";
VAL_ 1329 HCU_Sailmode_531h 0 "Convenmod" 1 "SalWadeSts" 2 "DpWadeSts" 3 "SailingFunc" 4 "UpbeachSts" 5 "WaitfinspSts" 6 "EmerfloatingSts" 7 "Reserved";
VAL_ 1330 DWD_WorkSts 0 "Disable" 1 "Standby" 2 "Active" 3 "Failure";
VAL_ 1330 RSensorFailSts 0 "Sensor normal" 1 "Sensor fault";
VAL_ 1330 DWD_Distance 0 "No object" 1 "Object in zone 1, 0~5cm" 2 "Object in zone 2, 6~10cm" 3 "Object in zone 3, 11~15cm" 4 "Object in zone 4, 16~20cm" 5 "Object in zone 5, 21~25cm" 6 "Object in zone 6, 26~30cm" 7 "Object in zone 7, 31~35cm" 8 "Object in zone 8, 36~40cm" 9 "Object in zone 9, 41~45cm" 10 "Object in zone 10, 46~50cm" 11 "Object in zone 11, 51~55cm" 12 "Object in zone 12, 56~60cm" 13 "Object in zone 13, 61~65cm" 14 "Object in zone 14, 66~70cm" 15 "Object in zone 15, 71~75cm" 16 "Object in zone 16, 76~80cm" 17 "Object in zone 17, 81~85cm" 18 "Object in zone 18, 86~90cm" 19 "Object in zone 19, 91~95cm" 20 "Object in zone 20, 96~100cm" 21 "Object in zone 21, 101~105cm" 22 "Object in zone 22, 105~110cm" 23 "Object in zone 23, 111~115cm" 24 "Object in zone 24, 116~120cm" 25 "Object in zone 25, 121~125cm" 26 "Object in zone 26, 126~130cm" 27 "Object in zone 27, 131~135cm" 28 "Object in zone 28, 136~140cm" 29 "Object in zone 29, 141~145cm" 30 "Object in zone 30, 146~150cm";
VAL_ 1360 ICC_XDriveMode 0 "Not Active" 1 "unidentifiable" 2 "Normal" 3 "SNOW" 4 "MUD" 5 "ROCK" 6 "SAND" 7 "WATERSURFACE" 8 "Normal" 9 "SNOW" 10 "MUD" 11 "ROCK" 12 "SAND" 13 "WATERSURFACE" 14 "Normal" 15 "SNOW" 16 "MUD" 17 "ROCK" 18 "SAND" 19 "Reserved" 20 "Reserved" 21 "Reserved" 22 "Reserved" 23 "Reserved" 24 "Reserved" 25 "Reserved" 26 "Reserved" 27 "Reserved" 28 "Reserved" 29 "Reserved" 30 "Reserved" 31 "Reserved";
VAL_ 1417 HCU_stCleverDisReason_589h 0 "No_Command" 1 "please quit offroad drive mode" 2 "please quit cco mode" 3 "please quit ads mode" 4 "please quit energy saving mode" 5 "please quit sickness mode" 6 "please quit Trailer Mode" 7 "please quit  Dragging Mode";
VAL_ 1453 ICC_BedStatus 0 "Not Active" 1 "Large Bed At Home" 2 "Single Bed" 3 "Sofa For Parking" 4 "Travel Bed" 5 "Pause" 6 "Reserved" 7 "OFF";
VAL_ 1582 RMR_RMCU 0 "Inactive" 1 "Active";
VAL_ 1582 RMCU_Wakeup_Poweron 0 "Inactive" 1 "Active";
VAL_ 1582 RMCU_Wakeup_NM 0 "Inactive" 1 "Active";
VAL_ 1582 RMCU_Wakeup_Diag 0 "Inactive" 1 "Active";
VAL_ 1582 RMCU_Awake_Poweron 0 "Inactive" 1 "Active";
VAL_ 1582 RMCU_Awake_NM 0 "Inactive" 1 "Active";
VAL_ 1582 RMCU_Awake_Diag 0 "Inactive" 1 "Active";
VAL_ 1582 RMCU_Awake_Discharge 0 "Inactive" 1 "Active";
VAL_ 1582 RMCU_Awake_HVON 0 "Inactive" 1 "Active";
